VERSION ""

NS_ :

BS_:

BU_:

BO_ 2365524759 FF0B: 8 Vector__XXX
 SG_ LightCheckSwitch : 0|2@1+ (1,0) [0|3] "" Vector__XXX
 SG_ D1DemistSwitch : 4|2@1+ (1,0) [0|3] "" Vector__XXX
 SG_ SchoolFlashSwitch : 6|2@1+ (1,0) [0|3] "" Vector__XXX
 SG_ BellCancelSwitch : 8|2@1+ (1,0) [0|3] "" Vector__XXX
 SG_ MapLightSwitch : 10|2@1+ (1,0) [0|3] "" Vector__XXX
 SG_ CabLightSwitch : 2|2@1+ (1,0) [0|3] "" Vector__XXX
 SG_ D1Switch : 14|2@1+ (1,0) [0|3] "" Vector__XXX
 SG_ D2Switch : 12|2@1+ (1,0) [0|3] "" Vector__XXX
 SG_ Switch_2S_10 : 18|2@1+ (1,0) [0|3] "" Vector__XXX
 SG_ Switch_2S_11 : 20|2@1+ (1,0) [0|3] "" Vector__XXX
 SG_ Switch_2S_12 : 22|2@1+ (1,0) [0|3] "" Vector__XXX
 SG_ Switch_2S_13 : 24|2@1+ (1,0) [0|3] "" Vector__XXX
 SG_ Switch_2S_14 : 56|2@1+ (1,0) [0|3] "" Vector__XXX
 SG_ Switch_2S_15 : 48|2@1+ (1,0) [0|3] "" Vector__XXX
 SG_ Switch_2S_16 : 40|2@1+ (1,0) [0|3] "" Vector__XXX
 SG_ Switch_2S_17 : 32|2@1+ (1,0) [0|3] "" Vector__XXX
 SG_ ECASSwitch : 34|3@1+ (1,0) [0|7] "" Vector__XXX
 SG_ DemistFanSwitch : 37|3@1+ (1,0) [0|7] "" Vector__XXX
 SG_ DriverFanSwitch : 42|3@1+ (1,0) [0|7] "" Vector__XXX
 SG_ SaloonLightSwitch : 45|3@1+ (1,0) [0|7] "" Vector__XXX
 SG_ RTRH_Switch : 29|3@1+ (1,0) [0|7] "" Vector__XXX
 SG_ DemistTempSwitch : 26|3@1+ (1,0) [0|7] "" Vector__XXX
 SG_ Switch_3S_7 : 50|3@1+ (1,0) [0|7] "" Vector__XXX
 SG_ Switch_3S_8 : 53|3@1+ (1,0) [0|7] "" Vector__XXX
 SG_ Switch_3S_9 : 58|3@1+ (1,0) [0|7] "" Vector__XXX
 SG_ Switch_3S_10 : 61|3@1+ (1,0) [0|7] "" Vector__XXX
 SG_ Switch_2S_9 : 16|2@1+ (1,0) [0|3] "" Vector__XXX

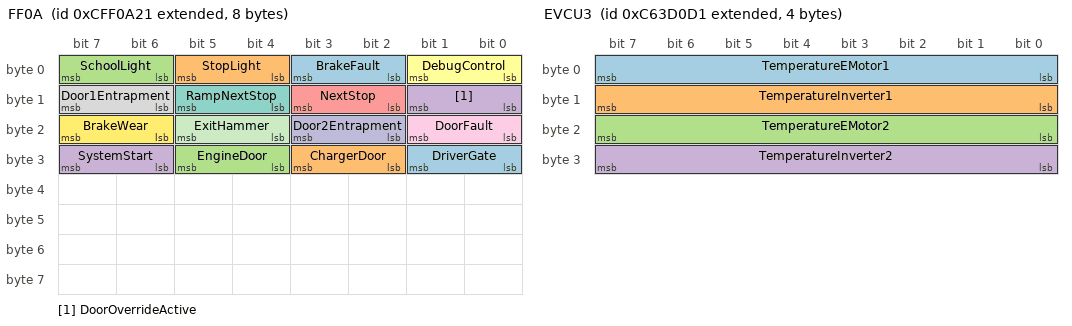
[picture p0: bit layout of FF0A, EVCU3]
BO_ 2365524513 FF0A: 8 Vector__XXX
 SG_ BrakeFault : 2|2@1+ (1,0) [0|3] "" Vector__XXX
 SG_ StopLight : 4|2@1+ (1,0) [0|3] "" Vector__XXX
 SG_ SchoolLight : 6|2@1+ (1,0) [0|3] "" Vector__XXX
 SG_ DoorOverrideActive : 8|2@1+ (1,0) [0|3] "" Vector__XXX
 SG_ NextStop : 10|2@1+ (1,0) [0|3] "" Vector__XXX
 SG_ DebugControl : 0|2@1+ (1,0) [0|3] "" Vector__XXX
 SG_ RampNextStop : 12|2@1+ (1,0) [0|3] "" Vector__XXX
 SG_ Door1Entrapment : 14|2@1+ (1,0) [0|3] "" Vector__XXX
 SG_ DoorFault : 16|2@1+ (1,0) [0|3] "" Vector__XXX
 SG_ Door2Entrapment : 18|2@1+ (1,0) [0|3] "" Vector__XXX
 SG_ ExitHammer : 20|2@1+ (1,0) [0|3] "" Vector__XXX
 SG_ BrakeWear : 22|2@1+ (1,0) [0|3] "" Vector__XXX
 SG_ DriverGate : 24|2@1+ (1,0) [0|3] "" Vector__XXX
 SG_ ChargerDoor : 26|2@1+ (1,0) [0|3] "" Vector__XXX
 SG_ EngineDoor : 28|2@1+ (1,0) [0|3] "" Vector__XXX
 SG_ SystemStart : 30|2@1+ (1,0) [0|3] "" Vector__XXX

BO_ 2355220689 EVCU1: 8 Vector__XXX
 SG_ ActualdirectionmodeAVESyst : 0|2@1+ (1,0) [0|2] "" Vector__XXX
 SG_ ActualDrivemode : 2|2@1+ (1,0) [0|3] "" Vector__XXX
 SG_ WheelSlippagedetection : 4|4@1+ (1,0) [0|3] "sts" Vector__XXX
 SG_ Averagemotorspeed : 8|16@1+ (1,0) [0|15000] "rpm" Vector__XXX
 SG_ ActualtorqueAVESystem : 24|12@1+ (1,0) [0|3200] "Nm" Vector__XXX
 SG_ AVESystemReady : 36|1@1+ (1,0) [0|1] "b" Vector__XXX
 SG_ AVESystemReducedOperational : 37|1@1+ (1,0) [0|1] "b" Vector__XXX
 SG_ ElectricalBrakeTorqueLow : 38|1@1+ (1,0) [0|1] "b" Vector__XXX
 SG_ CreeperStopping : 39|1@1+ (1,0) [0|1] "b" Vector__XXX
 SG_ CreeperNotAvailable : 40|1@1+ (1,0) [0|1] "b" Vector__XXX
 SG_ TUpAStopping : 41|1@1+ (1,0) [0|1] "b" Vector__XXX
 SG_ TUpANotAvailable : 42|1@1+ (1,0) [0|1] "b" Vector__XXX
 SG_ RecuperationHighStatus : 43|1@1+ (1,0) [0|1] "b" Vector__XXX
 SG_ Reserved4 : 44|1@1+ (1,0) [0|1] "b" Vector__XXX
 SG_ Reserved57 : 45|3@1+ (1,0) [0|1] "b" Vector__XXX
 SG_ EMotorOverspeed : 48|2@1+ (1,0) [0|3] "b" Vector__XXX
 SG_ EVECU1MSGCounter : 52|4@1+ (1,0) [0|15] "cnt" Vector__XXX
 SG_ EVEC1MSGCRC : 56|8@1+ (1,0) [0|255] "" Vector__XXX

BO_ 2355351761 EVCU3: 4 Vector__XXX
 SG_ TemperatureEMotor1 : 0|8@1+ (1,-40) [-40|213] "°C" Vector__XXX
 SG_ TemperatureInverter1 : 8|8@1+ (1,-40) [-40|213] "°C" Vector__XXX
 SG_ TemperatureEMotor2 : 16|8@1+ (1,-40) [-40|213] "°C" Vector__XXX
 SG_ TemperatureInverter2 : 24|8@1+ (1,-40) [-40|213] "°C" Vector__XXX

BO_ 2566759713 DC2: 8 Vector__XXX
 SG_ LockStatusOfDoor1 : 0|2@1+ (1,0) [0|3] "" Vector__XXX
 SG_ OpenStatusOfDoor1 : 2|2@1+ (1,0) [0|3] "" Vector__XXX
 SG_ EnableStatusOfDoor1 : 4|2@1+ (1,0) [0|3] "" Vector__XXX
 SG_ LockStatusOfDoor2 : 6|2@1+ (1,0) [0|3] "" Vector__XXX
 SG_ OpenStatusOfDoor2 : 8|2@1+ (1,0) [0|3] "" Vector__XXX
 SG_ EnableStatusOfDoor2 : 10|2@1+ (1,0) [0|3] "" Vector__XXX
 SG_ LockStatusOfDoor3 : 12|2@1+ (1,0) [0|3] "" Vector__XXX
 SG_ OpenStatusOfDoor3 : 14|2@1+ (1,0) [0|3] "" Vector__XXX
 SG_ EnableStatusOfDoor3 : 16|2@1+ (1,0) [0|3] "" Vector__XXX
 SG_ LockStatusOfDoor4 : 18|2@1+ (1,0) [0|3] "" Vector__XXX
 SG_ OpenStatusOfDoor4 : 20|2@1+ (1,0) [0|3] "" Vector__XXX
 SG_ EnableStatusOfDoor4 : 22|2@1+ (1,0) [0|3] "" Vector__XXX
 SG_ LockStatusOfDoor5 : 24|2@1+ (1,0) [0|3] "" Vector__XXX
 SG_ OpenStatusOfDoor5 : 26|2@1+ (1,0) [0|3] "" Vector__XXX
 SG_ EnableStatusOfDoor5 : 28|2@1+ (1,0) [0|3] "" Vector__XXX
 SG_ LockStatusOfDoor6 : 30|2@1+ (1,0) [0|3] "" Vector__XXX
 SG_ OpenStatusOfDoor6 : 32|2@1+ (1,0) [0|3] "" Vector__XXX
 SG_ EnableStatusOfDoor6 : 34|2@1+ (1,0) [0|3] "" Vector__XXX
 SG_ LockStatusOfDoor7 : 36|2@1+ (1,0) [0|3] "" Vector__XXX
 SG_ OpenStatusOfDoor7 : 38|2@1+ (1,0) [0|3] "" Vector__XXX
 SG_ EnableStatusOfDoor7 : 40|2@1+ (1,0) [0|3] "" Vector__XXX
 SG_ LockStatusOfDoor8 : 42|2@1+ (1,0) [0|3] "" Vector__XXX
 SG_ OpenStatusOfDoor8 : 44|2@1+ (1,0) [0|3] "" Vector__XXX
 SG_ EnableStatusOfDoor8 : 46|2@1+ (1,0) [0|3] "" Vector__XXX
 SG_ LockStatusOfDoor9 : 48|2@1+ (1,0) [0|3] "" Vector__XXX
 SG_ OpenStatusOfDoor9 : 50|2@1+ (1,0) [0|3] "" Vector__XXX
 SG_ EnableStatusOfDoor9 : 52|2@1+ (1,0) [0|3] "" Vector__XXX
 SG_ LockStatusOfDoor10 : 54|2@1+ (1,0) [0|3] "" Vector__XXX
 SG_ OpenStatusOfDoor10 : 56|2@1+ (1,0) [0|3] "" Vector__XXX
 SG_ EnableStatusOfDoor10 : 58|2@1+ (1,0) [0|3] "" Vector__XXX

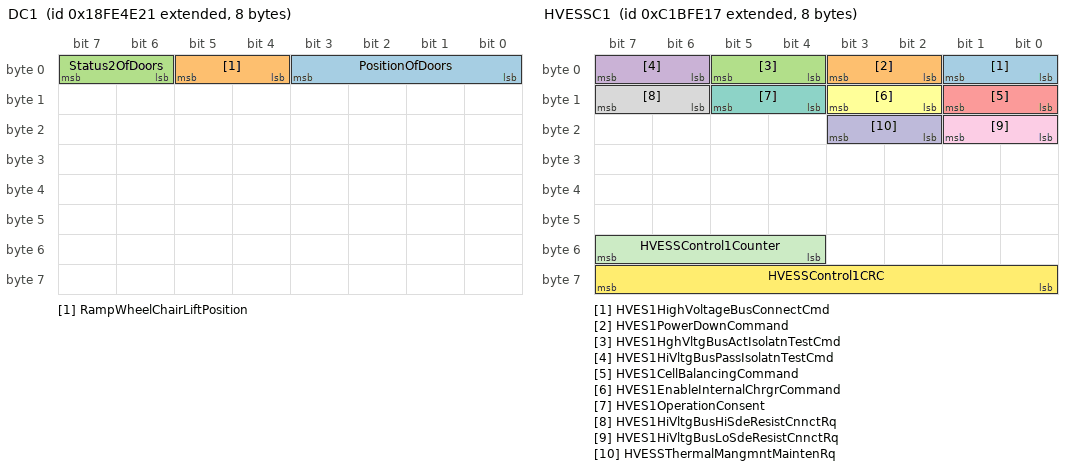
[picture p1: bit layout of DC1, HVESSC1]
BO_ 2566802977 DC1: 8 Vector__XXX
 SG_ PositionOfDoors : 0|4@1+ (1,0) [0|15] "" Vector__XXX
 SG_ RampWheelChairLiftPosition : 4|2@1+ (1,0) [0|3] "" Vector__XXX
 SG_ Status2OfDoors : 6|2@1+ (1,0) [0|3] "" Vector__XXX

BO_ 2350644759 HVESSC1: 8 Vector__XXX
 SG_ HVES1HighVoltageBusConnectCmd : 0|2@1+ (1,0) [0|3] "" Vector__XXX
 SG_ HVES1PowerDownCommand : 2|2@1+ (1,0) [0|3] "" Vector__XXX
 SG_ HVES1HghVltgBusActIsolatnTestCmd : 4|2@1+ (1,0) [0|3] "" Vector__XXX
 SG_ HVES1HiVltgBusPassIsolatnTestCmd : 6|2@1+ (1,0) [0|3] "" Vector__XXX
 SG_ HVES1CellBalancingCommand : 8|2@1+ (1,0) [0|3] "" Vector__XXX
 SG_ HVES1EnableInternalChrgrCommand : 10|2@1+ (1,0) [0|3] "" Vector__XXX
 SG_ HVES1OperationConsent : 12|2@1+ (1,0) [0|3] "" Vector__XXX
 SG_ HVES1HiVltgBusHiSdeResistCnnctRq : 14|2@1+ (1,0) [0|3] "" Vector__XXX
 SG_ HVES1HiVltgBusLoSdeResistCnnctRq : 16|2@1+ (1,0) [0|3] "" Vector__XXX
 SG_ HVESSThermalMangmntMaintenRq : 18|2@1+ (1,0) [0|3] "" Vector__XXX
 SG_ HVESSControl1Counter : 52|4@1+ (1,0) [0|15] "" Vector__XXX
 SG_ HVESSControl1CRC : 56|8@1+ (1,0) [0|255] "" Vector__XXX

BO_ 2565865739 EBC1: 8 Vector__XXX
 SG_ ASREngineControlActive : 0|2@1+ (1,0) [0|3] "" Vector__XXX
 SG_ ASRBrakeControlActive : 2|2@1+ (1,0) [0|3] "" Vector__XXX
 SG_ AntiLockBrakingActive : 4|2@1+ (1,0) [0|3] "" Vector__XXX
 SG_ EBSBrakeSwitch : 6|2@1+ (1,0) [0|3] "" Vector__XXX
 SG_ BrakePedalPosition : 8|8@1+ (0.4,0) [0|100] "%" Vector__XXX
 SG_ ABSOffRoadSwitch : 16|2@1+ (1,0) [0|3] "" Vector__XXX
 SG_ ASROffRoadSwitch : 18|2@1+ (1,0) [0|3] "" Vector__XXX
 SG_ ASRHillHolderSwitch : 20|2@1+ (1,0) [0|3] "" Vector__XXX
 SG_ TractionControlOverrideSwitch : 22|2@1+ (1,0) [0|3] "" Vector__XXX
 SG_ AcceleratorInterlockSwitch : 24|2@1+ (1,0) [0|3] "" Vector__XXX
 SG_ EngineDerateSwitch : 26|2@1+ (1,0) [0|3] "" Vector__XXX
 SG_ EngineAuxiliaryShutdownSwitch : 28|2@1+ (1,0) [0|3] "" Vector__XXX
 SG_ RemoteAcceleratorEnableSwitch : 30|2@1+ (1,0) [0|3] "" Vector__XXX
 SG_ EngineRetarderSelection : 32|8@1+ (0.4,0) [0|100] "%" Vector__XXX
 SG_ ABSFullyOperational : 40|2@1+ (1,0) [0|3] "" Vector__XXX
 SG_ EBSRedWarningSignal : 42|2@1+ (1,0) [0|3] "" Vector__XXX
 SG_ ABSEBSAmberWarningSignal : 44|2@1+ (1,0) [0|3] "" Vector__XXX
 SG_ ATCASRInformationSignal : 46|2@1+ (1,0) [0|3] "" Vector__XXX
 SG_ SrcAddrOfCtrllingDevForBrkCtrl : 48|8@1+ (1,0) [0|255] "" Vector__XXX
 SG_ RailroadModeSwitch : 56|2@1+ (1,0) [0|3] "" Vector__XXX
 SG_ HaltBrakeSwitch : 58|2@1+ (1,0) [0|3] "" Vector__XXX
 SG_ TrailerABSStatus : 60|2@1+ (1,0) [0|3] "" Vector__XXX
 SG_ TractorMntdTrailerABSWarningSig : 62|2@1+ (1,0) [0|3] "" Vector__XXX

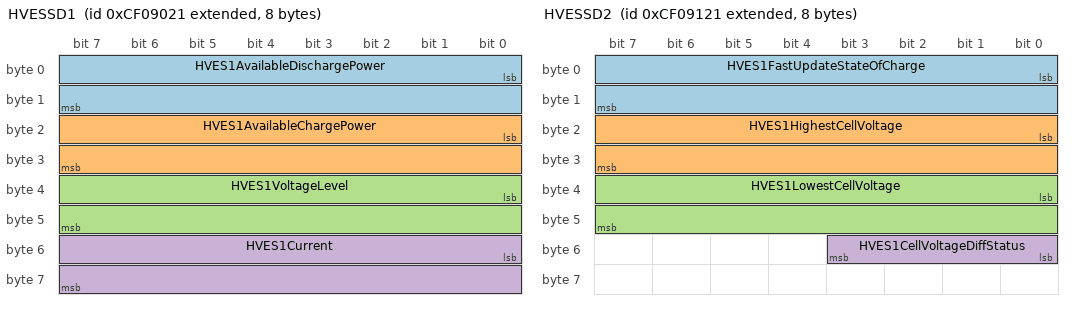
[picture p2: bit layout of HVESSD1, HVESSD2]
BO_ 2364575777 HVESSD1: 8 Vector__XXX
 SG_ HVES1AvailableDischargePower : 0|16@1+ (0.05,0) [0|3212.75] "kW" Vector__XXX
 SG_ HVES1AvailableChargePower : 16|16@1+ (0.05,0) [0|3212.75] "kW" Vector__XXX
 SG_ HVES1VoltageLevel : 32|16@1+ (0.05,0) [0|3212.75] "V" Vector__XXX
 SG_ HVES1Current : 48|16@1+ (0.05,-1600) [-1600|1612.75] "A" Vector__XXX

BO_ 2364576033 HVESSD2: 8 Vector__XXX
 SG_ HVES1FastUpdateStateOfCharge : 0|16@1+ (0.0015625,0) [0|100.3984375] "%" Vector__XXX
 SG_ HVES1HighestCellVoltage : 16|16@1+ (0.001,0) [0|64.255] "V" Vector__XXX
 SG_ HVES1LowestCellVoltage : 32|16@1+ (0.001,0) [0|64.255] "V" Vector__XXX
 SG_ HVES1CellVoltageDiffStatus : 48|4@1+ (1,0) [0|15] "" Vector__XXX

BO_ 2566545953 LD2: 8 Vector__XXX
 SG_ TractorHazardLights : 0|2@1+ (1,0) [0|3] "" Vector__XXX

BO_ 2365219607 LCMD2: 8 Vector__XXX
 SG_ LightingData2RequestCommand : 0|2@1+ (1,0) [0|3] "" Vector__XXX
 SG_ TractorHazardLightsCommand : 2|2@1+ (1,0) [0|3] "" Vector__XXX

BO_ 2499547671 CDC1: 8 Vector__XXX
 SG_ CabDoorsLockActuationCommand : 0|3@1+ (1,0) [0|7] "" Vector__XXX
 SG_ RemoteCabDoorLockRequest : 8|3@1+ (1,0) [0|7] "" Vector__XXX
 SG_ LeftFrontWindowPositionCommand : 16|3@1+ (1,0) [0|7] "" Vector__XXX
 SG_ RightFrontWindowPositionCommand : 19|3@1+ (1,0) [0|7] "" Vector__XXX
 SG_ MirrorFoldingSwitch : 22|2@1+ (1,0) [0|3] "" Vector__XXX
 SG_ LeftRearWindowPositionCommand : 24|3@1+ (1,0) [0|7] "" Vector__XXX
 SG_ RightRearWindowPositionCommand : 27|3@1+ (1,0) [0|7] "" Vector__XXX
 SG_ MirrorAutoPanningEnable : 30|2@1+ (1,0) [0|3] "" Vector__XXX
 SG_ MirrorLeft1HorizontalCommand : 32|2@1+ (1,0) [0|3] "" Vector__XXX
 SG_ MirrorLeft1VerticalCommand : 34|2@1+ (1,0) [0|3] "" Vector__XXX
 SG_ MirrorRight1HorizontalCommand : 36|2@1+ (1,0) [0|3] "" Vector__XXX
 SG_ MirrorRight1VerticalCommand : 38|2@1+ (1,0) [0|3] "" Vector__XXX
 SG_ MirrorLeft2HorizontalCommand : 40|2@1+ (1,0) [0|3] "" Vector__XXX
 SG_ MirrorLeft2VerticalCommand : 42|2@1+ (1,0) [0|3] "" Vector__XXX
 SG_ MirrorRight2HorizontalCommand : 44|2@1+ (1,0) [0|3] "" Vector__XXX
 SG_ MirrorRight2VerticalCommand : 46|2@1+ (1,0) [0|3] "" Vector__XXX
 SG_ MirrorLeft1HeatCommand : 48|2@1+ (1,0) [0|3] "" Vector__XXX
 SG_ MirrorRight1HeatCommand : 50|2@1+ (1,0) [0|3] "" Vector__XXX
 SG_ MirrorLeft2HeatCommand : 52|2@1+ (1,0) [0|3] "" Vector__XXX
 SG_ MirrorRight2HeatCommand : 54|2@1+ (1,0) [0|3] "" Vector__XXX

BO_ 2566771745 CM3: 8 Vector__XXX
 SG_ TransferCaseSelectorSwitch : 0|3@1+ (1,0) [0|7] "" Vector__XXX
 SG_ AfttreatmentSCRDosingModeCommand : 3|3@1+ (1,0) [0|7] "" Vector__XXX
 SG_ MomentaryOperatorKeySwitch : 6|2@1+ (1,0) [0|3] "" Vector__XXX
 SG_ FifthWheelReleaseControl : 8|2@1+ (1,0) [0|3] "" Vector__XXX
 SG_ FifthWhlReleaseCtrlSecurityLckt : 10|2@1+ (1,0) [0|3] "" Vector__XXX
 SG_ VehicleTrailerStatus : 12|2@1+ (1,0) [0|3] "" Vector__XXX
 SG_ OperatorKeyDetected : 14|2@1+ (1,0) [0|3] "" Vector__XXX
 SG_ TransmissionOilLevelRequest : 16|2@1+ (1,0) [0|3] "" Vector__XXX
 SG_ OperatorKeySwitchAccessoryPower : 18|2@1+ (1,0) [0|3] "" Vector__XXX
 SG_ OperatorKeySwitchIgnitionPower : 20|2@1+ (1,0) [0|3] "" Vector__XXX
 SG_ OperatorKeySwitchStart : 22|2@1+ (1,0) [0|3] "" Vector__XXX
 SG_ OprtrKeySwitchDelayedBattryOff : 24|2@1+ (1,0) [0|3] "" Vector__XXX
 SG_ HornSwitch : 26|2@1+ (1,0) [0|3] "" Vector__XXX
 SG_ EngineAirShutoffTestSwitch : 28|2@1+ (1,0) [0|3] "" Vector__XXX
 SG_ EngineAirShutoffManualSwitch : 30|2@1+ (1,0) [0|3] "" Vector__XXX
 SG_ OperatorKeySwitchService : 32|2@1+ (1,0) [0|3] "" Vector__XXX
 SG_ OperatorKeySwitchOff : 34|2@1+ (1,0) [0|3] "" Vector__XXX
 SG_ RemoteKeyFobFunctionRequested : 40|5@1+ (1,0) [0|31] "" Vector__XXX

BO_ 2566799393 LD: 8 Vector__XXX
 SG_ RunningLight : 0|2@1+ (1,0) [0|3] "" Vector__XXX
 SG_ AlternateBeamHeadLightData : 2|2@1+ (1,0) [0|3] "" Vector__XXX
 SG_ LowBeamHeadLightData : 4|2@1+ (1,0) [0|3] "" Vector__XXX
 SG_ HighBeamHeadLightData : 6|2@1+ (1,0) [0|3] "" Vector__XXX
 SG_ TractorFrontFogLights : 8|2@1+ (1,0) [0|3] "" Vector__XXX
 SG_ RotatingBeaconLight : 10|2@1+ (1,0) [0|3] "" Vector__XXX
 SG_ RightTurnSignalLights : 12|2@1+ (1,0) [0|3] "" Vector__XXX
 SG_ LeftTurnSignalLights : 14|2@1+ (1,0) [0|3] "" Vector__XXX
 SG_ BackUpLightAndAlarmHorn : 16|2@1+ (1,0) [0|3] "" Vector__XXX
 SG_ CenterStopLight : 18|2@1+ (1,0) [0|3] "" Vector__XXX
 SG_ RightStopLight : 20|2@1+ (1,0) [0|3] "" Vector__XXX
 SG_ LeftStopLight : 22|2@1+ (1,0) [0|3] "" Vector__XXX
 SG_ ImplementClearanceLight : 24|2@1+ (1,0) [0|3] "" Vector__XXX
 SG_ TractorClearanceLight : 26|2@1+ (1,0) [0|3] "" Vector__XXX
 SG_ ImplementMarkerLight : 28|2@1+ (1,0) [0|3] "" Vector__XXX
 SG_ TractorMarkerLight : 30|2@1+ (1,0) [0|3] "" Vector__XXX
 SG_ RearFogLights : 32|2@1+ (1,0) [0|3] "" Vector__XXX
 SG_ TractorUndersideMntdWorkLights : 34|2@1+ (1,0) [0|3] "" Vector__XXX
 SG_ TractorRearLowMountedWorkLights : 36|2@1+ (1,0) [0|3] "" Vector__XXX
 SG_ TractorRearHighMountedWorkLights : 38|2@1+ (1,0) [0|3] "" Vector__XXX
 SG_ TractorSideLowMountedWorkLights : 40|2@1+ (1,0) [0|3] "" Vector__XXX
 SG_ TractorSideHighMountedWorkLights : 42|2@1+ (1,0) [0|3] "" Vector__XXX
 SG_ TractorFrontLowMountedWorkLights : 44|2@1+ (1,0) [0|3] "" Vector__XXX
 SG_ TractorFrntHighMountedWorkLights : 46|2@1+ (1,0) [0|3] "" Vector__XXX
 SG_ ImplementOEMOption2Light : 48|2@1+ (1,0) [0|3] "" Vector__XXX
 SG_ ImplementOEMOption1Light : 50|2@1+ (1,0) [0|3] "" Vector__XXX
 SG_ ImplementRightFacingWorkLight : 52|2@1+ (1,0) [0|3] "" Vector__XXX
 SG_ ImplementLeftForwardWorkLight : 54|2@1+ (1,0) [0|3] "" Vector__XXX
 SG_ ImplementRightForwardWorkLight : 58|2@1+ (1,0) [0|3] "" Vector__XXX
 SG_ ImplementLeftFacingWorkLight : 60|2@1+ (1,0) [0|3] "" Vector__XXX
 SG_ ImplementRearWorkLight : 62|2@1+ (1,0) [0|3] "" Vector__XXX

BO_ 2365473047 LCMD: 8 Vector__XXX
 SG_ RunningLightCommand : 0|2@1+ (1,0) [0|3] "" Vector__XXX
 SG_ AlternateBeamHeadLightCommand : 2|2@1+ (1,0) [0|3] "" Vector__XXX
 SG_ LowBeamHeadLightCommand : 4|2@1+ (1,0) [0|3] "" Vector__XXX
 SG_ HighBeamHeadLightCommand : 6|2@1+ (1,0) [0|3] "" Vector__XXX
 SG_ TractorFrontFogLightsCommand : 8|2@1+ (1,0) [0|3] "" Vector__XXX
 SG_ RotatingBeaconLightCommand : 10|2@1+ (1,0) [0|3] "" Vector__XXX
 SG_ RightTurnSignalLightsCommand : 12|2@1+ (1,0) [0|3] "" Vector__XXX
 SG_ LeftTurnSignalLightsCommand : 14|2@1+ (1,0) [0|3] "" Vector__XXX
 SG_ BackUpLightAndAlarmHornCommand : 16|2@1+ (1,0) [0|3] "" Vector__XXX
 SG_ CenterStopLightCommand : 18|2@1+ (1,0) [0|3] "" Vector__XXX
 SG_ RightStopLightCommand : 20|2@1+ (1,0) [0|3] "" Vector__XXX
 SG_ LeftStopLightCommand : 22|2@1+ (1,0) [0|3] "" Vector__XXX
 SG_ ImplementClearanceLightCommand : 24|2@1+ (1,0) [0|3] "" Vector__XXX
 SG_ TractorClearanceLightCommand : 26|2@1+ (1,0) [0|3] "" Vector__XXX
 SG_ ImplementMarkerLightCommand : 28|2@1+ (1,0) [0|3] "" Vector__XXX
 SG_ TractorMarkerLightCommand : 30|2@1+ (1,0) [0|3] "" Vector__XXX
 SG_ RearFogLightCommand : 32|2@1+ (1,0) [0|3] "" Vector__XXX
 SG_ TractorUnderSdeMntdWorkLightsCmd : 34|2@1+ (1,0) [0|3] "" Vector__XXX
 SG_ TractorRearLowMntdWorkLightsCmd : 36|2@1+ (1,0) [0|3] "" Vector__XXX
 SG_ TractorRearHghMntdWorkLightsCmd : 38|2@1+ (1,0) [0|3] "" Vector__XXX
 SG_ TractorSideLowMntdWorkLightsCmd : 40|2@1+ (1,0) [0|3] "" Vector__XXX
 SG_ TractorSideHghMntdWorkLightsCmd : 42|2@1+ (1,0) [0|3] "" Vector__XXX
 SG_ TractorFrntLowMntdWorkLightsCmd : 44|2@1+ (1,0) [0|3] "" Vector__XXX
 SG_ TractorFrntHghMntdWorkLightsCmd : 46|2@1+ (1,0) [0|3] "" Vector__XXX
 SG_ ImplementOEMOption2LightCommand : 48|2@1+ (1,0) [0|3] "" Vector__XXX
 SG_ ImplementOEMOption1LightCommand : 50|2@1+ (1,0) [0|3] "" Vector__XXX
 SG_ ImplementRightFacingWorkLightCmd : 52|2@1+ (1,0) [0|3] "" Vector__XXX
 SG_ ImplementLeftForwardWorkLightCmd : 54|2@1+ (1,0) [0|3] "" Vector__XXX
 SG_ LightingDataRequestCommand : 56|2@1+ (1,0) [0|3] "" Vector__XXX
 SG_ ImplementRightFrwdWorkLightCmd : 58|2@1+ (1,0) [0|3] "" Vector__XXX
 SG_ ImplementLeftFacingWorkLightCmd : 60|2@1+ (1,0) [0|3] "" Vector__XXX
 SG_ ImplementRearWorkLightCommand : 62|2@1+ (1,0) [0|3] "" Vector__XXX

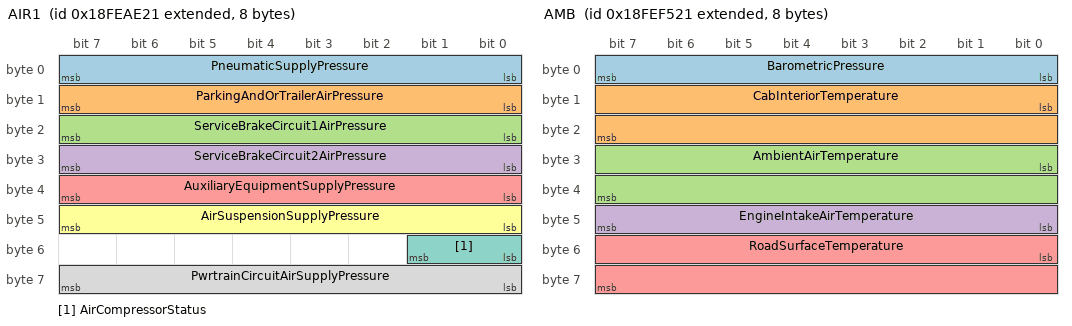
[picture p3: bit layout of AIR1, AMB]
BO_ 2566827553 AIR1: 8 Vector__XXX
 SG_ PneumaticSupplyPressure : 0|8@1+ (8,0) [0|2000] "kPa" Vector__XXX
 SG_ ParkingAndOrTrailerAirPressure : 8|8@1+ (8,0) [0|2000] "kPa" Vector__XXX
 SG_ ServiceBrakeCircuit1AirPressure : 16|8@1+ (8,0) [0|2000] "kPa" Vector__XXX
 SG_ ServiceBrakeCircuit2AirPressure : 24|8@1+ (8,0) [0|2000] "kPa" Vector__XXX
 SG_ AuxiliaryEquipmentSupplyPressure : 32|8@1+ (8,0) [0|2000] "kPa" Vector__XXX
 SG_ AirSuspensionSupplyPressure : 40|8@1+ (8,0) [0|2000] "kPa" Vector__XXX
 SG_ AirCompressorStatus : 48|2@1+ (1,0) [0|3] "" Vector__XXX
 SG_ PwrtrainCircuitAirSupplyPressure : 56|8@1+ (8,0) [0|2000] "kPa" Vector__XXX

BO_ 2566844705 CCVS1: 8 Vector__XXX
 SG_ TwoSpeedAxleSwitch : 0|2@1+ (1,0) [0|3] "" Vector__XXX
 SG_ ParkingBrakeSwitch : 2|2@1+ (1,0) [0|3] "" Vector__XXX
 SG_ CruiseControlPauseSwitch : 4|2@1+ (1,0) [0|3] "" Vector__XXX
 SG_ ParkBrakeReleaseInhibitRequest : 6|2@1+ (1,0) [0|3] "" Vector__XXX
 SG_ WheelBasedVehicleSpeed : 8|16@1+ (0.00390625,0) [0|250.99609375] "km/h" Vector__XXX
 SG_ CruiseControlActive : 24|2@1+ (1,0) [0|3] "" Vector__XXX
 SG_ CruiseControlEnableSwitch : 26|2@1+ (1,0) [0|3] "" Vector__XXX
 SG_ BrakeSwitch : 28|2@1+ (1,0) [0|3] "" Vector__XXX
 SG_ ClutchSwitch : 30|2@1+ (1,0) [0|3] "" Vector__XXX
 SG_ CruiseControlSetSwitch : 32|2@1+ (1,0) [0|3] "" Vector__XXX
 SG_ CruiseControlCoastSwitch : 34|2@1+ (1,0) [0|3] "" Vector__XXX
 SG_ CruiseControlResumeSwitch : 36|2@1+ (1,0) [0|3] "" Vector__XXX
 SG_ CruiseControlAccelerateSwitch : 38|2@1+ (1,0) [0|3] "" Vector__XXX
 SG_ CruiseControlSetSpeed : 40|8@1+ (1,0) [0|250] "km/h" Vector__XXX
 SG_ PTOGovernorState : 48|5@1+ (1,0) [0|31] "" Vector__XXX
 SG_ CruiseControlStates : 53|3@1+ (1,0) [0|7] "" Vector__XXX
 SG_ EngineIdleIncrementSwitch : 56|2@1+ (1,0) [0|3] "" Vector__XXX
 SG_ EngineIdleDecrementSwitch : 58|2@1+ (1,0) [0|3] "" Vector__XXX
 SG_ EngineDiagnosticTestModeSwitch : 60|2@1+ (1,0) [0|3] "" Vector__XXX
 SG_ EngineShutdownOverrideSwitch : 62|2@1+ (1,0) [0|3] "" Vector__XXX

BO_ 2566845729 AMB: 8 Vector__XXX
 SG_ BarometricPressure : 0|8@1+ (0.5,0) [0|125] "kPa" Vector__XXX
 SG_ CabInteriorTemperature : 8|16@1+ (0.03125,-273) [-273|1734.96875] "deg C" Vector__XXX
 SG_ AmbientAirTemperature : 24|16@1+ (0.03125,-273) [-273|1734.96875] "deg C" Vector__XXX
 SG_ EngineIntakeAirTemperature : 40|8@1+ (1,-40) [-40|210] "deg C" Vector__XXX
 SG_ RoadSurfaceTemperature : 48|16@1+ (0.03125,-273) [-273|1734.96875] "deg C" Vector__XXX

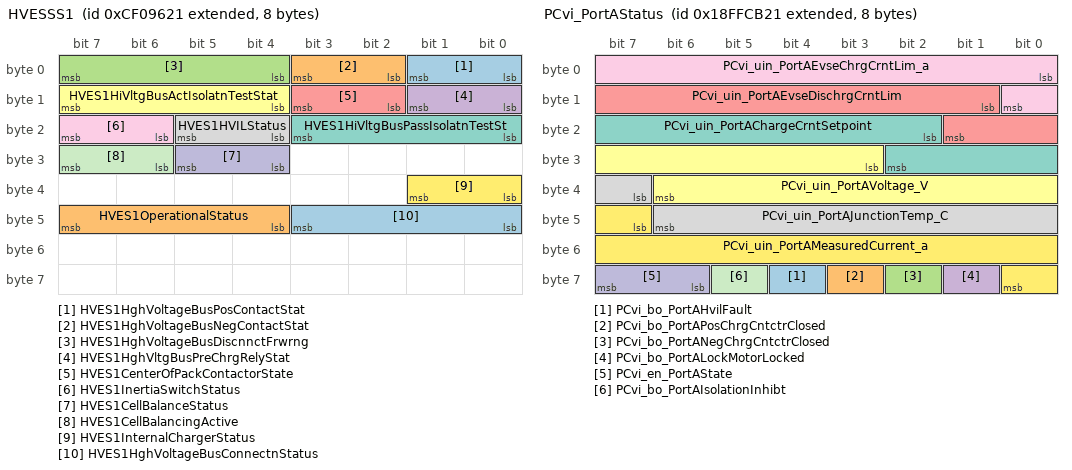
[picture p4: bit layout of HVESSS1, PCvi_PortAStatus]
BO_ 2364577313 HVESSS1: 8 Vector__XXX
 SG_ HVES1HghVoltageBusPosContactStat : 0|2@1+ (1,0) [0|3] "" Vector__XXX
 SG_ HVES1HghVoltageBusNegContactStat : 2|2@1+ (1,0) [0|3] "" Vector__XXX
 SG_ HVES1HghVoltageBusDiscnnctFrwrng : 4|4@1+ (1,0) [0|15] "" Vector__XXX
 SG_ HVES1HghVltgBusPreChrgRelyStat : 8|2@1+ (1,0) [0|3] "" Vector__XXX
 SG_ HVES1CenterOfPackContactorState : 10|2@1+ (1,0) [0|3] "" Vector__XXX
 SG_ HVES1HiVltgBusActIsolatnTestStat : 12|4@1+ (1,0) [0|15] "" Vector__XXX
 SG_ HVES1HiVltgBusPassIsolatnTestSt : 16|4@1+ (1,0) [0|15] "" Vector__XXX
 SG_ HVES1HVILStatus : 20|2@1+ (1,0) [0|3] "" Vector__XXX
 SG_ HVES1InertiaSwitchStatus : 22|2@1+ (1,0) [0|3] "" Vector__XXX
 SG_ HVES1CellBalanceStatus : 28|2@1+ (1,0) [0|3] "" Vector__XXX
 SG_ HVES1CellBalancingActive : 30|2@1+ (1,0) [0|3] "" Vector__XXX
 SG_ HVES1InternalChargerStatus : 32|2@1+ (1,0) [0|3] "" Vector__XXX
 SG_ HVES1HghVoltageBusConnectnStatus : 40|4@1+ (1,0) [0|15] "" Vector__XXX
 SG_ HVES1OperationalStatus : 44|4@1+ (1,0) [0|15] "" Vector__XXX

BO_ 2566900513 PCvi_PortAStatus: 8 Vector__XXX
 SG_ PCvi_bo_PortAHvilFault : 60|1@1+ (1,0) [0|1] "" Vector__XXX
 SG_ PCvi_bo_PortAPosChrgCntctrClosed : 59|1@1+ (1,0) [0|1] "" Vector__XXX
 SG_ PCvi_bo_PortANegChrgCntctrClosed : 58|1@1+ (1,0) [0|1] "" Vector__XXX
 SG_ PCvi_bo_PortALockMotorLocked : 57|1@1+ (1,0) [0|1] "" Vector__XXX
 SG_ PCvi_uin_PortAEvseDischrgCrntLim : 9|9@1+ (1,0) [0|511] "A" Vector__XXX
 SG_ PCvi_uin_PortAVoltage_V : 27|12@1+ (0.5,-1024) [-1024|1023.5] "V" Vector__XXX
 SG_ PCvi_uin_PortAChargeCrntSetpoint : 18|9@1+ (1,0) [0|511] "A" Vector__XXX
 SG_ PCvi_uin_PortAJunctionTemp_C : 39|8@1+ (1,-50) [-50|205] "C" Vector__XXX
 SG_ PCvi_uin_PortAEvseChrgCrntLim_a : 0|9@1+ (1,0) [0|511] "A" Vector__XXX
 SG_ PCvi_en_PortAState : 62|2@1+ (1,0) [0|3] "" Vector__XXX
 SG_ PCvi_bo_PortAIsolationInhibt : 61|1@1+ (1,0) [0|1] "" Vector__XXX
 SG_ PCvi_uin_PortAMeasuredCurrent_a : 47|10@1+ (1,-512) [-512|511] "A" Vector__XXX

BO_ 2365479471 ASC1_A: 8 Vector__XXX
 SG_ NominalLevelFrontAxle : 0|4@1+ (1,0) [0|15] "" Vector__XXX
 SG_ NominalLevelRearAxle : 4|4@1+ (1,0) [0|15] "" Vector__XXX
 SG_ BelowNominalLevelFrontAxle : 8|2@1+ (1,0) [0|3] "" Vector__XXX
 SG_ BelowNominalLevelRearAxle : 10|2@1+ (1,0) [0|3] "" Vector__XXX
 SG_ AboveNominalLevelFrontAxle : 12|2@1+ (1,0) [0|3] "" Vector__XXX
 SG_ AboveNominalLevelRearAxle : 14|2@1+ (1,0) [0|3] "" Vector__XXX
 SG_ LoweringControlModeFrontAxle : 16|2@1+ (1,0) [0|3] "" Vector__XXX
 SG_ LoweringControlModeRearAxle : 18|2@1+ (1,0) [0|3] "" Vector__XXX
 SG_ LiftingControlModeFrontAxle : 20|2@1+ (1,0) [0|3] "" Vector__XXX
 SG_ LiftingControlModeRearAxle : 22|2@1+ (1,0) [0|3] "" Vector__XXX
 SG_ KneelingInformation : 24|4@1+ (1,0) [0|15] "" Vector__XXX
 SG_ LevelControlMode : 28|4@1+ (1,0) [0|15] "" Vector__XXX
 SG_ SecurityDevice : 32|2@1+ (1,0) [0|3] "" Vector__XXX
 SG_ VehicleMotionInhibit : 34|2@1+ (1,0) [0|3] "" Vector__XXX
 SG_ DoorRelease : 36|2@1+ (1,0) [0|3] "" Vector__XXX
 SG_ LiftAxle1Position : 38|2@1+ (1,0) [0|3] "" Vector__XXX
 SG_ FrontAxleInBumperRange : 40|2@1+ (1,0) [0|3] "" Vector__XXX
 SG_ RearAxleInBumperRange : 42|2@1+ (1,0) [0|3] "" Vector__XXX
 SG_ LiftAxle2Position : 46|2@1+ (1,0) [0|3] "" Vector__XXX
 SG_ SuspensionRemoteControl1 : 48|2@1+ (1,0) [0|3] "" Vector__XXX
 SG_ SuspensionRemoteControl2 : 50|2@1+ (1,0) [0|3] "" Vector__XXX
 SG_ AllowLevelCtrlDuringBrkngStatus : 52|2@1+ (1,0) [0|3] "" Vector__XXX
 SG_ SpeedDependantLevelControlStatus : 54|2@1+ (1,0) [0|3] "" Vector__XXX
 SG_ SuspensionCtrlRefusalInformation : 56|4@1+ (1,0) [0|15] "" Vector__XXX
 SG_ MemoryLevel : 60|4@1+ (1,0) [0|15] "" Vector__XXX

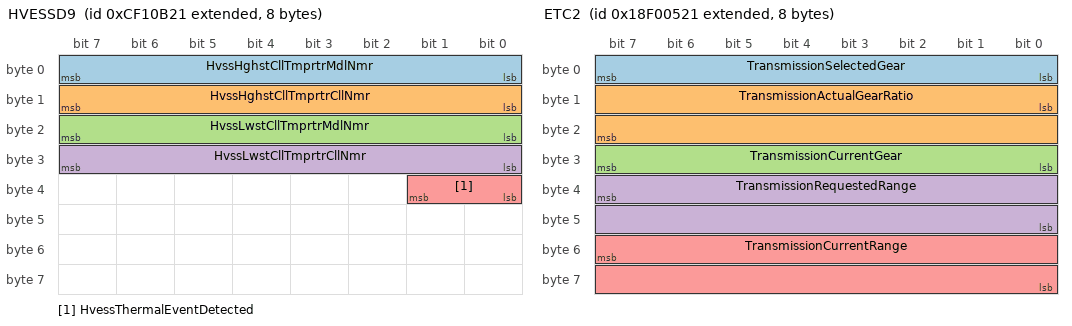
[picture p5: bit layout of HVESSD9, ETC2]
BO_ 2364607265 HVESSD9: 8 Vector__XXX
 SG_ HvssHghstCllTmprtrMdlNmr : 0|8@1+ (1,0) [0|250] "count" Vector__XXX
 SG_ HvssHghstCllTmprtrCllNmr : 8|8@1+ (1,0) [0|250] "count" Vector__XXX
 SG_ HvssLwstCllTmprtrMdlNmr : 16|8@1+ (1,0) [0|250] "count" Vector__XXX
 SG_ HvssLwstCllTmprtrCllNmr : 24|8@1+ (1,0) [0|250] "count" Vector__XXX
 SG_ HvessThermalEventDetected : 32|2@1+ (1,0) [0|3] "" Vector__XXX

BO_ 2565866785 ETC2: 8 Vector__XXX
 SG_ TransmissionSelectedGear : 0|8@1+ (1,-125) [-125|125] "" Vector__XXX
 SG_ TransmissionActualGearRatio : 8|16@1+ (0.001,0) [0|64.255] "" Vector__XXX
 SG_ TransmissionCurrentGear : 24|8@1+ (1,-125) [-125|125] "" Vector__XXX
 SG_ TransmissionRequestedRange : 39|16@0+ (1,0) [0|65535] "ASCII" Vector__XXX
 SG_ TransmissionCurrentRange : 55|16@0+ (1,0) [0|65535] "ASCII" Vector__XXX

BO_ 2566719265 DLCC1: 8 Vector__XXX
 SG_ EngineProtectLampCommand : 0|2@1+ (1,0) [0|3] "" Vector__XXX
 SG_ EngineAmberWarningLampCommand : 2|2@1+ (1,0) [0|3] "" Vector__XXX
 SG_ EngineRedStopLampCommand : 4|2@1+ (1,0) [0|3] "" Vector__XXX
 SG_ OBDMalfunctionIndicatorLampCmd : 6|2@1+ (1,0) [0|3] "" Vector__XXX
 SG_ EngineBrakeActiveLampCommand : 8|2@1+ (1,0) [0|3] "" Vector__XXX
 SG_ ComPrsionBrkEnblSwIndictrLampCmd : 10|2@1+ (1,0) [0|3] "" Vector__XXX
 SG_ EngineOilPressureLowLampCommand : 12|2@1+ (1,0) [0|3] "" Vector__XXX
 SG_ EngCoolntTemperatureHighLampCmd : 14|2@1+ (1,0) [0|3] "" Vector__XXX
 SG_ EngineCoolantLevelLowLampCommand : 16|2@1+ (1,0) [0|3] "" Vector__XXX
 SG_ EngineIdleManagementActvLampCmd : 18|2@1+ (1,0) [0|3] "" Vector__XXX
 SG_ EngAirFilterRestrictionLampCmd : 20|2@1+ (1,0) [0|3] "" Vector__XXX
 SG_ EngFuelFilterRestrictedLampCmd : 22|2@1+ (1,0) [0|3] "" Vector__XXX
 SG_ EngCtrlModule1ReadyForUseLampCmd : 24|2@1+ (1,0) [0|3] "" Vector__XXX
 SG_ EngCtrlModule2ReadyForUseLampCmd : 26|2@1+ (1,0) [0|3] "" Vector__XXX
 SG_ EngCtrlModule3ReadyForUseLampCmd : 28|2@1+ (1,0) [0|3] "" Vector__XXX
 SG_ EngineSpeedHighLampCommand : 30|2@1+ (1,0) [0|3] "" Vector__XXX
 SG_ EngineSpeedVeryHighLampCommand : 32|2@1+ (1,0) [0|3] "" Vector__XXX
 SG_ VehicleAccltnRateLimitLampCmd : 34|2@1+ (1,0) [0|3] "" Vector__XXX
 SG_ EngIdlMangmntPendingEvntLampCmd : 36|2@1+ (1,0) [0|3] "" Vector__XXX
 SG_ EngStopStartAutoStopActvLampCmd : 38|2@1+ (1,0) [0|3] "" Vector__XXX
 SG_ EngStopStrtAutoStrtFailedLampCmd : 40|2@1+ (1,0) [0|3] "" Vector__XXX
 SG_ EngineStopStartEnabledLampCmd : 42|2@1+ (1,0) [0|3] "" Vector__XXX
 SG_ EngineOilTemperatureHighLampCmd : 44|2@1+ (1,0) [0|3] "" Vector__XXX
 SG_ EngineFuelTemperatureHighLampCmd : 46|2@1+ (1,0) [0|3] "" Vector__XXX
 SG_ EngIntercoolerTempHghLampCmd : 48|2@1+ (1,0) [0|3] "" Vector__XXX
 SG_ EngineAirShutoffLampCommand : 50|2@1+ (1,0) [0|3] "" Vector__XXX

BO_ 2566749463 FMS1: 8 Vector__XXX
 SG_ FMS1_Mux M : 0|4@1+ (1,0) [0|0] "" Vector__XXX
 SG_ Coolingairconditioning m0 : 4|3@1+ (1,0) [0|7] "" Vector__XXX
 SG_ Highbeammainbeam m0 : 8|3@1+ (1,0) [0|7] "" Vector__XXX
 SG_ Lowbeamdippedbeam m0 : 12|3@1+ (1,0) [0|7] "" Vector__XXX
 SG_ Turnsignals m0 : 16|3@1+ (1,0) [0|7] "" Vector__XXX
 SG_ Hazardwarning m0 : 20|3@1+ (1,0) [0|7] "" Vector__XXX
 SG_ Provisionforthehandicapped m0 : 24|3@1+ (1,0) [0|7] "" Vector__XXX
 SG_ ParkingBrake m0 : 28|3@1+ (1,0) [0|7] "" Vector__XXX
 SG_ Brakefailure m0 : 32|3@1+ (1,0) [0|7] "" Vector__XXX
 SG_ Hatchopen m0 : 36|3@1+ (1,0) [0|7] "" Vector__XXX
 SG_ Fuellevel m0 : 40|3@1+ (1,0) [0|7] "" Vector__XXX
 SG_ Enginecoolanttemperature m0 : 44|3@1+ (1,0) [0|7] "" Vector__XXX
 SG_ Batterychargingcondition m0 : 48|3@1+ (1,0) [0|7] "" Vector__XXX
 SG_ Engineoil m0 : 52|3@1+ (1,0) [0|7] "" Vector__XXX
 SG_ Positionlightssidelights m0 : 56|3@1+ (1,0) [0|7] "" Vector__XXX
 SG_ Frontfoglight m0 : 60|3@1+ (1,0) [0|7] "" Vector__XXX
 SG_ StopRequest m2 : 32|3@1+ (1,0) [0|7] "" Vector__XXX
 SG_ Electricmotorfailures m4 : 8|3@1+ (1,0) [0|7] "" Vector__XXX
 SG_ Batterypack m4 : 20|3@1+ (1,0) [0|7] "" Vector__XXX
 SG_ HVsystemcaution m4 : 24|3@1+ (1,0) [0|7] "" Vector__XXX
 SG_ Batterypacktemperature m4 : 28|3@1+ (1,0) [0|7] "" Vector__XXX
 SG_ Limitedperformanceelectricmtr m4 : 32|3@1+ (1,0) [0|7] "" Vector__XXX
 SG_ Batterypackcooling m4 : 36|3@1+ (1,0) [0|7] "" Vector__XXX

BO_ 2566843431 VI: 200 Vector__XXX

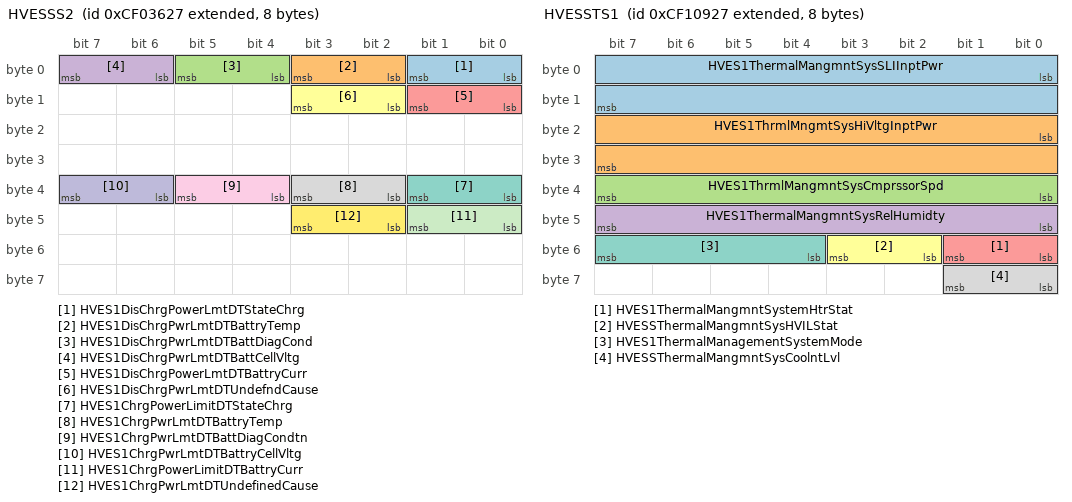
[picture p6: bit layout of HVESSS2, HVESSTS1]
BO_ 2364552743 HVESSS2: 8 Vector__XXX
 SG_ HVES1DisChrgPowerLmtDTStateChrg : 0|2@1+ (1,0) [0|3] "" Vector__XXX
 SG_ HVES1DisChrgPwrLmtDTBattryTemp : 2|2@1+ (1,0) [0|3] "" Vector__XXX
 SG_ HVES1DisChrgPwrLmtDTBattDiagCond : 4|2@1+ (1,0) [0|3] "" Vector__XXX
 SG_ HVES1DisChrgPwrLmtDTBattCellVltg : 6|2@1+ (1,0) [0|3] "" Vector__XXX
 SG_ HVES1DisChrgPowerLmtDTBattryCurr : 8|2@1+ (1,0) [0|3] "" Vector__XXX
 SG_ HVES1DisChrgPwrLmtDTUndefndCause : 10|2@1+ (1,0) [0|3] "" Vector__XXX
 SG_ HVES1ChrgPowerLimitDTStateChrg : 32|2@1+ (1,0) [0|3] "" Vector__XXX
 SG_ HVES1ChrgPwrLmtDTBattryTemp : 34|2@1+ (1,0) [0|3] "" Vector__XXX
 SG_ HVES1ChrgPwrLmtDTBattDiagCondtn : 36|2@1+ (1,0) [0|3] "" Vector__XXX
 SG_ HVES1ChrgPwrLmtDTBattryCellVltg : 38|2@1+ (1,0) [0|3] "" Vector__XXX
 SG_ HVES1ChrgPowerLimitDTBattryCurr : 40|2@1+ (1,0) [0|3] "" Vector__XXX
 SG_ HVES1ChrgPwrLmtDTUndefinedCause : 42|2@1+ (1,0) [0|3] "" Vector__XXX

BO_ 2364606759 HVESSTS1: 8 Vector__XXX
 SG_ HVES1ThermalMangmntSysSLIInptPwr : 0|16@1+ (0.5,0) [0|32127.5] "W" Vector__XXX
 SG_ HVES1ThrmlMngmtSysHiVltgInptPwr : 16|16@1+ (0.5,0) [0|32127.5] "W" Vector__XXX
 SG_ HVES1ThrmlMangmntSysCmprssorSpd : 32|8@1+ (32,0) [0|8000] "rpm" Vector__XXX
 SG_ HVES1ThermalMangmntSysRelHumidty : 40|8@1+ (0.4,0) [0|100] "%" Vector__XXX
 SG_ HVES1ThermalMangmntSystemHtrStat : 48|2@1+ (1,0) [0|3] "" Vector__XXX
 SG_ HVESSThermalMangmntSysHVILStat : 50|2@1+ (1,0) [0|3] "" Vector__XXX
 SG_ HVES1ThermalManagementSystemMode : 52|4@1+ (1,0) [0|15] "" Vector__XXX
 SG_ HVESSThermalMangmntSysCoolntLvl : 56|2@1+ (1,0) [0|3] "" Vector__XXX

BO_ 2566540583 EVEI: 8 Vector__XXX
 SG_ TotalTripEnergyConsumed : 0|32@1+ (0.1,0) [0|421108121.5] "kWh" Vector__XXX
 SG_ TripDriveEnergyEconomy : 32|16@1+ (0.001953125,0) [0|125.49804688] "kWh/km" Vector__XXX

BO_ 2365349415 HVESSHIST: 19 Vector__XXX
 SG_ HVES1StateOfHealth : 0|8@1+ (0.4,0) [0|100] "%" Vector__XXX
 SG_ HVES1ContactorOpenUnderLoadCount : 8|16@1+ (1,0) [0|64255] "" Vector__XXX
 SG_ HVES1TotalEnergyThroughput : 24|32@1+ (100,0) [0|201326492] "Watt-hour" Vector__XXX
 SG_ HVES1TotalAccumulatedCharge : 56|32@1+ (100,0) [0|201326492] "Ah" Vector__XXX
 SG_ HVESSTotalLifetimeEnergyInput : 88|32@1+ (1,0) [0|4211081215] "kWh" Vector__XXX
 SG_ HVESSTotalLifetimeEnergyOutput : 120|32@1+ (1,0) [0|4211081215] "kWh" Vector__XXX

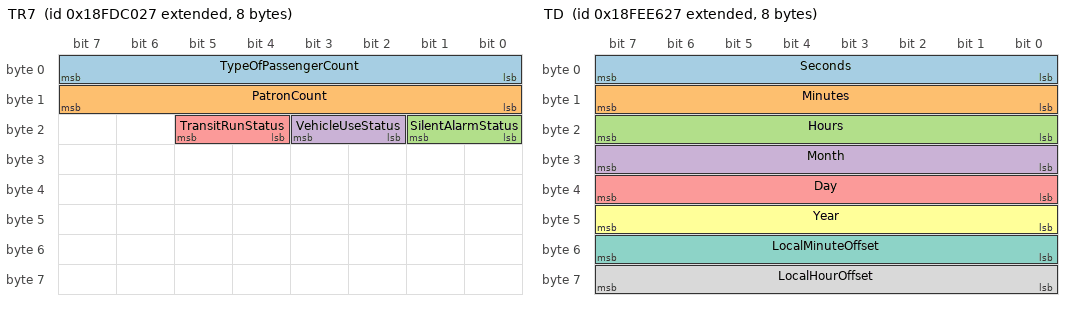
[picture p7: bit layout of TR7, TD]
BO_ 2566766631 TR7: 8 Vector__XXX
 SG_ TypeOfPassengerCount : 0|8@1+ (1,0) [0|255] "" Vector__XXX
 SG_ PatronCount : 8|8@1+ (1,0) [0|250] "" Vector__XXX
 SG_ SilentAlarmStatus : 16|2@1+ (1,0) [0|3] "" Vector__XXX
 SG_ VehicleUseStatus : 18|2@1+ (1,0) [0|3] "" Vector__XXX
 SG_ TransitRunStatus : 20|2@1+ (1,0) [0|3] "" Vector__XXX

BO_ 2566841895 TD: 8 Vector__XXX
 SG_ Seconds : 0|8@1+ (0.25,0) [0|62.5] "s" Vector__XXX
 SG_ Minutes : 8|8@1+ (1,0) [0|250] "min" Vector__XXX
 SG_ Hours : 16|8@1+ (1,0) [0|250] "h" Vector__XXX
 SG_ Month : 24|8@1+ (1,0) [0|250] "month" Vector__XXX
 SG_ Day : 32|8@1+ (0.25,0) [0|62.5] "Days" Vector__XXX
 SG_ Year : 40|8@1+ (1,1985) [1985|2235] "year" Vector__XXX
 SG_ LocalMinuteOffset : 48|8@1+ (1,-125) [-125|125] "min" Vector__XXX
 SG_ LocalHourOffset : 56|8@1+ (1,-125) [-125|125] "h" Vector__XXX

BO_ 2566842151 VH: 8 Vector__XXX
 SG_ TotalVehicleHours : 0|32@1+ (0.05,0) [0|210554060.75] "h" Vector__XXX
 SG_ TotalPowerTakeoffHours : 32|32@1+ (0.05,0) [0|210554060.75] "h" Vector__XXX

BO_ 2566834699 DM1_EBS: 50 Vector__XXX
 SG_ ProtectLamp : 0|2@1+ (1,0) [0|3] "" Vector__XXX
 SG_ AmberWarningLamp : 2|2@1+ (1,0) [0|3] "" Vector__XXX
 SG_ RedStopLamp : 4|2@1+ (1,0) [0|3] "" Vector__XXX
 SG_ MalfunctionIndicatorLamp : 6|2@1+ (1,0) [0|3] "" Vector__XXX
 SG_ FlashProtectLamp : 8|2@1+ (1,0) [0|3] "" Vector__XXX
 SG_ FlashAmberWarningLamp : 10|2@1+ (1,0) [0|3] "" Vector__XXX
 SG_ FlashRedStopLamp : 12|2@1+ (1,0) [0|3] "" Vector__XXX
 SG_ FlashMalfunctionIndicatorLamp : 14|2@1+ (1,0) [0|3] "" Vector__XXX
 SG_ SuspectParameterNumber : 23|19@0+ (1,0) [0|524287] "" Vector__XXX
 SG_ FailureModeIdentifier : 32|5@1+ (1,0) [0|31] "" Vector__XXX
 SG_ OccurrenceCount : 40|7@1+ (1,0) [0|127] "" Vector__XXX
 SG_ SPNConversionMethod : 47|1@1+ (1,0) [0|1] "" Vector__XXX
 SG_ SuspectParameterNumber2 : 39|19@0+ (1,0) [0|524287] "" Vector__XXX
 SG_ FailureModeIdentifier2 : 64|5@1+ (1,0) [0|31] "" Vector__XXX
 SG_ OccurrenceCount2 : 72|7@1+ (1,0) [0|127] "" Vector__XXX
 SG_ SPNConversionMethod2 : 79|1@1+ (1,0) [0|1] "" Vector__XXX
 SG_ SuspectParameterNumber3 : 71|19@0+ (1,0) [0|524287] "" Vector__XXX
 SG_ FailureModeIdentifier3 : 96|5@1+ (1,0) [0|31] "" Vector__XXX
 SG_ OccurrenceCount3 : 104|7@1+ (1,0) [0|127] "" Vector__XXX
 SG_ SPNConversionMethod3 : 111|1@1+ (1,0) [0|1] "" Vector__XXX
 SG_ SuspectParameterNumber4 : 103|19@0+ (1,0) [0|524287] "" Vector__XXX
 SG_ FailureModeIdentifier4 : 128|5@1+ (1,0) [0|31] "" Vector__XXX
 SG_ OccurrenceCount4 : 136|7@1+ (1,0) [0|127] "" Vector__XXX
 SG_ SPNConversionMethod4 : 143|1@1+ (1,0) [0|1] "" Vector__XXX
 SG_ SuspectParameterNumber5 : 135|19@0+ (1,0) [0|524287] "" Vector__XXX
 SG_ FailureModeIdentifier5 : 160|5@1+ (1,0) [0|31] "" Vector__XXX
 SG_ OccurrenceCount5 : 168|7@1+ (1,0) [0|127] "" Vector__XXX
 SG_ SPNConversionMethod5 : 175|1@1+ (1,0) [0|1] "" Vector__XXX
 SG_ SuspectParameterNumber6 : 167|19@0+ (1,0) [0|524287] "" Vector__XXX
 SG_ FailureModeIdentifier6 : 192|5@1+ (1,0) [0|31] "" Vector__XXX
 SG_ OccurrenceCount6 : 200|7@1+ (1,0) [0|127] "" Vector__XXX
 SG_ SPNConversionMethod6 : 207|1@1+ (1,0) [0|1] "" Vector__XXX
 SG_ SuspectParameterNumber7 : 199|19@0+ (1,0) [0|524287] "" Vector__XXX
 SG_ FailureModeIdentifier7 : 224|5@1+ (1,0) [0|31] "" Vector__XXX
 SG_ OccurrenceCount7 : 232|7@1+ (1,0) [0|127] "" Vector__XXX
 SG_ SPNConversionMethod7 : 239|1@1+ (1,0) [0|1] "" Vector__XXX
 SG_ SuspectParameterNumber8 : 231|19@0+ (1,0) [0|524287] "" Vector__XXX
 SG_ FailureModeIdentifier8 : 256|5@1+ (1,0) [0|31] "" Vector__XXX
 SG_ OccurrenceCount8 : 264|7@1+ (1,0) [0|127] "" Vector__XXX
 SG_ SPNConversionMethod8 : 271|1@1+ (1,0) [0|1] "" Vector__XXX
 SG_ SuspectParameterNumber9 : 263|19@0+ (1,0) [0|524287] "" Vector__XXX
 SG_ FailureModeIdentifier9 : 288|5@1+ (1,0) [0|31] "" Vector__XXX
 SG_ OccurrenceCount9 : 296|7@1+ (1,0) [0|127] "" Vector__XXX
 SG_ SPNConversionMethod9 : 303|1@1+ (1,0) [0|1] "" Vector__XXX
 SG_ SuspectParameterNumber10 : 295|19@0+ (1,0) [0|524287] "" Vector__XXX
 SG_ FailureModeIdentifier10 : 320|5@1+ (1,0) [0|31] "" Vector__XXX
 SG_ OccurrenceCount10 : 328|7@1+ (1,0) [0|127] "" Vector__XXX
 SG_ SPNConversionMethod10 : 335|1@1+ (1,0) [0|1] "" Vector__XXX
 SG_ SuspectParameterNumber11 : 327|19@0+ (1,0) [0|524287] "" Vector__XXX
 SG_ FailureModeIdentifier11 : 352|5@1+ (1,0) [0|31] "" Vector__XXX
 SG_ OccurrenceCount11 : 360|7@1+ (1,0) [0|127] "" Vector__XXX
 SG_ SPNConversionMethod11 : 367|1@1+ (1,0) [0|1] "" Vector__XXX
 SG_ SuspectParameterNumber12 : 359|19@0+ (1,0) [0|524287] "" Vector__XXX
 SG_ FailureModeIdentifier12 : 384|5@1+ (1,0) [0|31] "" Vector__XXX
 SG_ OccurrenceCount12 : 392|7@1+ (1,0) [0|127] "" Vector__XXX
 SG_ SPNConversionMethod12 : 399|1@1+ (1,0) [0|1] "" Vector__XXX

BO_ 2566834735 DM1_ECAS: 50 Vector__XXX
 SG_ ProtectLamp : 0|2@1+ (1,0) [0|3] "" Vector__XXX
 SG_ AmberWarningLamp : 2|2@1+ (1,0) [0|3] "" Vector__XXX
 SG_ RedStopLamp : 4|2@1+ (1,0) [0|3] "" Vector__XXX
 SG_ MalfunctionIndicatorLamp : 6|2@1+ (1,0) [0|3] "" Vector__XXX
 SG_ FlashProtectLamp : 8|2@1+ (1,0) [0|3] "" Vector__XXX
 SG_ FlashAmberWarningLamp : 10|2@1+ (1,0) [0|3] "" Vector__XXX
 SG_ FlashRedStopLamp : 12|2@1+ (1,0) [0|3] "" Vector__XXX
 SG_ FlashMalfunctionIndicatorLamp : 14|2@1+ (1,0) [0|3] "" Vector__XXX
 SG_ SuspectParameterNumber : 23|19@0+ (1,0) [0|524287] "" Vector__XXX
 SG_ FailureModeIdentifier : 32|5@1+ (1,0) [0|31] "" Vector__XXX
 SG_ OccurrenceCount : 40|7@1+ (1,0) [0|127] "" Vector__XXX
 SG_ SPNConversionMethod : 47|1@1+ (1,0) [0|1] "" Vector__XXX
 SG_ SuspectParameterNumber2 : 39|19@0+ (1,0) [0|524287] "" Vector__XXX
 SG_ FailureModeIdentifier2 : 64|5@1+ (1,0) [0|31] "" Vector__XXX
 SG_ OccurrenceCount2 : 72|7@1+ (1,0) [0|127] "" Vector__XXX
 SG_ SPNConversionMethod2 : 79|1@1+ (1,0) [0|1] "" Vector__XXX
 SG_ SuspectParameterNumber3 : 71|19@0+ (1,0) [0|524287] "" Vector__XXX
 SG_ FailureModeIdentifier3 : 96|5@1+ (1,0) [0|31] "" Vector__XXX
 SG_ OccurrenceCount3 : 104|7@1+ (1,0) [0|127] "" Vector__XXX
 SG_ SPNConversionMethod3 : 111|1@1+ (1,0) [0|1] "" Vector__XXX
 SG_ SuspectParameterNumber4 : 103|19@0+ (1,0) [0|524287] "" Vector__XXX
 SG_ FailureModeIdentifier4 : 128|5@1+ (1,0) [0|31] "" Vector__XXX
 SG_ OccurrenceCount4 : 136|7@1+ (1,0) [0|127] "" Vector__XXX
 SG_ SPNConversionMethod4 : 143|1@1+ (1,0) [0|1] "" Vector__XXX
 SG_ SuspectParameterNumber5 : 135|19@0+ (1,0) [0|524287] "" Vector__XXX
 SG_ FailureModeIdentifier5 : 160|5@1+ (1,0) [0|31] "" Vector__XXX
 SG_ OccurrenceCount5 : 168|7@1+ (1,0) [0|127] "" Vector__XXX
 SG_ SPNConversionMethod5 : 175|1@1+ (1,0) [0|1] "" Vector__XXX
 SG_ SuspectParameterNumber6 : 167|19@0+ (1,0) [0|524287] "" Vector__XXX
 SG_ FailureModeIdentifier6 : 192|5@1+ (1,0) [0|31] "" Vector__XXX
 SG_ OccurrenceCount6 : 200|7@1+ (1,0) [0|127] "" Vector__XXX
 SG_ SPNConversionMethod6 : 207|1@1+ (1,0) [0|1] "" Vector__XXX
 SG_ SuspectParameterNumber7 : 199|19@0+ (1,0) [0|524287] "" Vector__XXX
 SG_ FailureModeIdentifier7 : 224|5@1+ (1,0) [0|31] "" Vector__XXX
 SG_ OccurrenceCount7 : 232|7@1+ (1,0) [0|127] "" Vector__XXX
 SG_ SPNConversionMethod7 : 239|1@1+ (1,0) [0|1] "" Vector__XXX
 SG_ SuspectParameterNumber8 : 231|19@0+ (1,0) [0|524287] "" Vector__XXX
 SG_ FailureModeIdentifier8 : 256|5@1+ (1,0) [0|31] "" Vector__XXX
 SG_ OccurrenceCount8 : 264|7@1+ (1,0) [0|127] "" Vector__XXX
 SG_ SPNConversionMethod8 : 271|1@1+ (1,0) [0|1] "" Vector__XXX
 SG_ SuspectParameterNumber9 : 263|19@0+ (1,0) [0|524287] "" Vector__XXX
 SG_ FailureModeIdentifier9 : 288|5@1+ (1,0) [0|31] "" Vector__XXX
 SG_ OccurrenceCount9 : 296|7@1+ (1,0) [0|127] "" Vector__XXX
 SG_ SPNConversionMethod9 : 303|1@1+ (1,0) [0|1] "" Vector__XXX
 SG_ SuspectParameterNumber10 : 295|19@0+ (1,0) [0|524287] "" Vector__XXX
 SG_ FailureModeIdentifier10 : 320|5@1+ (1,0) [0|31] "" Vector__XXX
 SG_ OccurrenceCount10 : 328|7@1+ (1,0) [0|127] "" Vector__XXX
 SG_ SPNConversionMethod10 : 335|1@1+ (1,0) [0|1] "" Vector__XXX
 SG_ SuspectParameterNumber11 : 327|19@0+ (1,0) [0|524287] "" Vector__XXX
 SG_ FailureModeIdentifier11 : 352|5@1+ (1,0) [0|31] "" Vector__XXX
 SG_ OccurrenceCount11 : 360|7@1+ (1,0) [0|127] "" Vector__XXX
 SG_ SPNConversionMethod11 : 367|1@1+ (1,0) [0|1] "" Vector__XXX
 SG_ SuspectParameterNumber12 : 359|19@0+ (1,0) [0|524287] "" Vector__XXX
 SG_ FailureModeIdentifier12 : 384|5@1+ (1,0) [0|31] "" Vector__XXX
 SG_ OccurrenceCount12 : 392|7@1+ (1,0) [0|127] "" Vector__XXX
 SG_ SPNConversionMethod12 : 399|1@1+ (1,0) [0|1] "" Vector__XXX

BO_ 2566834778 DM1_ZF: 50 Vector__XXX
 SG_ ProtectLamp : 0|2@1+ (1,0) [0|3] "" Vector__XXX
 SG_ AmberWarningLamp : 2|2@1+ (1,0) [0|3] "" Vector__XXX
 SG_ RedStopLamp : 4|2@1+ (1,0) [0|3] "" Vector__XXX
 SG_ MalfunctionIndicatorLamp : 6|2@1+ (1,0) [0|3] "" Vector__XXX
 SG_ FlashProtectLamp : 8|2@1+ (1,0) [0|3] "" Vector__XXX
 SG_ FlashAmberWarningLamp : 10|2@1+ (1,0) [0|3] "" Vector__XXX
 SG_ FlashRedStopLamp : 12|2@1+ (1,0) [0|3] "" Vector__XXX
 SG_ FlashMalfunctionIndicatorLamp : 14|2@1+ (1,0) [0|3] "" Vector__XXX
 SG_ SuspectParameterNumber : 23|19@0+ (1,0) [0|524287] "" Vector__XXX
 SG_ FailureModeIdentifier : 32|5@1+ (1,0) [0|31] "" Vector__XXX
 SG_ OccurrenceCount : 40|7@1+ (1,0) [0|127] "" Vector__XXX
 SG_ SPNConversionMethod : 47|1@1+ (1,0) [0|1] "" Vector__XXX
 SG_ SuspectParameterNumber2 : 39|19@0+ (1,0) [0|524287] "" Vector__XXX
 SG_ FailureModeIdentifier2 : 64|5@1+ (1,0) [0|31] "" Vector__XXX
 SG_ OccurrenceCount2 : 72|7@1+ (1,0) [0|127] "" Vector__XXX
 SG_ SPNConversionMethod2 : 79|1@1+ (1,0) [0|1] "" Vector__XXX
 SG_ SuspectParameterNumber3 : 71|19@0+ (1,0) [0|524287] "" Vector__XXX
 SG_ FailureModeIdentifier3 : 96|5@1+ (1,0) [0|31] "" Vector__XXX
 SG_ OccurrenceCount3 : 104|7@1+ (1,0) [0|127] "" Vector__XXX
 SG_ SPNConversionMethod3 : 111|1@1+ (1,0) [0|1] "" Vector__XXX
 SG_ SuspectParameterNumber4 : 103|19@0+ (1,0) [0|524287] "" Vector__XXX
 SG_ FailureModeIdentifier4 : 128|5@1+ (1,0) [0|31] "" Vector__XXX
 SG_ OccurrenceCount4 : 136|7@1+ (1,0) [0|127] "" Vector__XXX
 SG_ SPNConversionMethod4 : 143|1@1+ (1,0) [0|1] "" Vector__XXX
 SG_ SuspectParameterNumber5 : 135|19@0+ (1,0) [0|524287] "" Vector__XXX
 SG_ FailureModeIdentifier5 : 160|5@1+ (1,0) [0|31] "" Vector__XXX
 SG_ OccurrenceCount5 : 168|7@1+ (1,0) [0|127] "" Vector__XXX
 SG_ SPNConversionMethod5 : 175|1@1+ (1,0) [0|1] "" Vector__XXX
 SG_ SuspectParameterNumber6 : 167|19@0+ (1,0) [0|524287] "" Vector__XXX
 SG_ FailureModeIdentifier6 : 192|5@1+ (1,0) [0|31] "" Vector__XXX
 SG_ OccurrenceCount6 : 200|7@1+ (1,0) [0|127] "" Vector__XXX
 SG_ SPNConversionMethod6 : 207|1@1+ (1,0) [0|1] "" Vector__XXX
 SG_ SuspectParameterNumber7 : 199|19@0+ (1,0) [0|524287] "" Vector__XXX
 SG_ FailureModeIdentifier7 : 224|5@1+ (1,0) [0|31] "" Vector__XXX
 SG_ OccurrenceCount7 : 232|7@1+ (1,0) [0|127] "" Vector__XXX
 SG_ SPNConversionMethod7 : 239|1@1+ (1,0) [0|1] "" Vector__XXX
 SG_ SuspectParameterNumber8 : 231|19@0+ (1,0) [0|524287] "" Vector__XXX
 SG_ FailureModeIdentifier8 : 256|5@1+ (1,0) [0|31] "" Vector__XXX
 SG_ OccurrenceCount8 : 264|7@1+ (1,0) [0|127] "" Vector__XXX
 SG_ SPNConversionMethod8 : 271|1@1+ (1,0) [0|1] "" Vector__XXX
 SG_ SuspectParameterNumber9 : 263|19@0+ (1,0) [0|524287] "" Vector__XXX
 SG_ FailureModeIdentifier9 : 288|5@1+ (1,0) [0|31] "" Vector__XXX
 SG_ OccurrenceCount9 : 296|7@1+ (1,0) [0|127] "" Vector__XXX
 SG_ SPNConversionMethod9 : 303|1@1+ (1,0) [0|1] "" Vector__XXX
 SG_ SuspectParameterNumber10 : 295|19@0+ (1,0) [0|524287] "" Vector__XXX
 SG_ FailureModeIdentifier10 : 320|5@1+ (1,0) [0|31] "" Vector__XXX
 SG_ OccurrenceCount10 : 328|7@1+ (1,0) [0|127] "" Vector__XXX
 SG_ SPNConversionMethod10 : 335|1@1+ (1,0) [0|1] "" Vector__XXX
 SG_ SuspectParameterNumber11 : 327|19@0+ (1,0) [0|524287] "" Vector__XXX
 SG_ FailureModeIdentifier11 : 352|5@1+ (1,0) [0|31] "" Vector__XXX
 SG_ OccurrenceCount11 : 360|7@1+ (1,0) [0|127] "" Vector__XXX
 SG_ SPNConversionMethod11 : 367|1@1+ (1,0) [0|1] "" Vector__XXX
 SG_ SuspectParameterNumber12 : 359|19@0+ (1,0) [0|524287] "" Vector__XXX
 SG_ FailureModeIdentifier12 : 384|5@1+ (1,0) [0|31] "" Vector__XXX
 SG_ OccurrenceCount12 : 392|7@1+ (1,0) [0|127] "" Vector__XXX
 SG_ SPNConversionMethod12 : 399|1@1+ (1,0) [0|1] "" Vector__XXX

CM_ BO_ 2365524759 "Proprietary B (0Bh) (Dash IO)";
CM_ BO_ 2365524513 "Proprietary B - Page 1 (0Ah)";
CM_ BO_ 2566759713 "Door Control 2";
CM_ BO_ 2566802977 "Door Control 1";
CM_ BO_ 2350644759 "High Voltage Energy Storage System Control 1";
CM_ BO_ 2565865739 "Electronic Brake Controller 1";
CM_ BO_ 2364575777 "High Voltage Energy Storage System Data 1";
CM_ BO_ 2364576033 "High Voltage Energy Storage System Data 2";
CM_ BO_ 2566545953 "Lighting Data 2";
CM_ BO_ 2365219607 "Lighting Command 2";
CM_ BO_ 2499547671 "Cab Door Control 1";
CM_ BO_ 2566771745 "Cab Message 3";
CM_ BO_ 2566799393 "Lighting Data";
CM_ BO_ 2365473047 "Lighting Command";
CM_ BO_ 2566827553 "Air Supply Pressure";
CM_ BO_ 2566844705 "Cruise Control/Vehicle Speed 1";
CM_ BO_ 2566845729 "Ambient Conditions";
CM_ BO_ 2364577313 "High Voltage Energy Storage System Status 1, Proterra VIC";
CM_ BO_ 2566900513 "Proprietary: [PropB_CA] Needs Definition";
CM_ BO_ 2365479471 "Air Suspension Control 1";
CM_ BO_ 2364607265 "High Voltage Energy Storage System Data 9";
CM_ SG_ 2364607265 HvssHghstCllTmprtrMdlNmr "HVESS Highest Cell Temperature Module Number: Identifies the location of the module containing SPN 8075 (HVESS Highest Cell Temperature).This parameter provides HVES system level information. If there are multiple packs in the system, then both indiv...";
CM_ SG_ 2364607265 HvssHghstCllTmprtrCllNmr "HVESS Highest Cell Temperature Cell Number: Identifies the location of SPN 8075 (HVESS Highest Cell Temperature) within SPN 8241 (HVESS Highest Cell Temperature Module Number).This parameter provides HVES system level information. If there are multip...";
CM_ SG_ 2364607265 HvssLwstCllTmprtrMdlNmr "HVESS Lowest Cell Temperature Module Number: Identifies the location of the module containing SPN 8076 (HVESS Lowest Cell Temperature ).This parameter provides HVES system level information. If there are multiple packs in the system, then both indivi...";
CM_ SG_ 2364607265 HvssLwstCllTmprtrCllNmr "HVESS Lowest Cell Temperature Cell Number: Identifies the location of SPN 8076 (HVESS Lowest Cell Temperature) within SPN 8243 (HVESS Lowest Cell Temperature Module Number).This parameter provides HVES system level information. If there are multiple ...";
CM_ SG_ 2364607265 HvessThermalEventDetected "HVESS Thermal Event Detected: A sensor has detected the presence of a thermal event at or near High Voltage Energy Storage System  (or Pack 1 in systems with only one pack).00b = No Thermal Event Detected01b = Thermal Event Detected10b = Error11b = N...";
CM_ BO_ 2565866785 "Electronic Transmission Controller 2";
CM_ BO_ 2566719265 "Direct Lamp Control Command 1";
CM_ BO_ 2566749463 "Reserved for FMS Telltale status";
CM_ BO_ 2566843431 "Vehicle Identification";
CM_ BO_ 2364552743 "High Voltage Energy Storage System Status 2";
CM_ BO_ 2364606759 "High Voltage Energy Storage System Thermal Management System Status 1";
CM_ BO_ 2566540583 "EV Economy Information";
CM_ BO_ 2365349415 "High Voltage Energy Storage System History";
CM_ BO_ 2566766631 "Passenger Counter";
CM_ BO_ 2566841895 "Time/Date";
CM_ BO_ 2566842151 "Vehicle Hours";
CM_ BO_ 2566834699 "Active Diagnostic Trouble Codes";
CM_ BO_ 2566834735 "Active Diagnostic Trouble Codes";
CM_ BO_ 2566834778 "Active Diagnostic Trouble Codes";
BA_DEF_  "BusType" STRING ;
BA_DEF_  "ProtocolType" STRING ;
BA_DEF_ BO_  "VFrameFormat" ENUM  "StandardCAN","ExtendedCAN","reserved","J1939PG";
BA_DEF_ BO_  "GenMsgCycleTime" INT 0 65535;
BA_DEF_ SG_  "GenSigStartValue" FLOAT -3.4e+38 3.4e+38;
BA_DEF_ SG_  "SPN" INT 0 655350;
BA_DEF_DEF_  "BusType" "CAN";
BA_DEF_DEF_  "ProtocolType" "J1939";
BA_DEF_DEF_  "VFrameFormat" "J1939PG";
BA_DEF_DEF_  "GenMsgCycleTime" 0;
BA_DEF_DEF_  "GenSigStartValue" 0;
BA_DEF_DEF_  "SPN" 0;
BA_ "GenMsgCycleTime" BO_ 2365524759 1000;
BA_ "GenSigStartValue" SG_ 2365524759 LightCheckSwitch 3;
BA_ "GenSigStartValue" SG_ 2365524759 D1DemistSwitch 3;
BA_ "GenSigStartValue" SG_ 2365524759 SchoolFlashSwitch 3;
BA_ "GenSigStartValue" SG_ 2365524759 BellCancelSwitch 3;
BA_ "GenSigStartValue" SG_ 2365524759 MapLightSwitch 3;
BA_ "GenSigStartValue" SG_ 2365524759 CabLightSwitch 3;
BA_ "GenSigStartValue" SG_ 2365524759 D1Switch 3;
BA_ "GenSigStartValue" SG_ 2365524759 D2Switch 3;
BA_ "GenSigStartValue" SG_ 2365524759 Switch_2S_10 3;
BA_ "GenSigStartValue" SG_ 2365524759 Switch_2S_11 3;
BA_ "GenSigStartValue" SG_ 2365524759 Switch_2S_12 3;
BA_ "GenSigStartValue" SG_ 2365524759 Switch_2S_13 3;
BA_ "GenSigStartValue" SG_ 2365524759 Switch_2S_14 3;
BA_ "GenSigStartValue" SG_ 2365524759 Switch_2S_15 3;
BA_ "GenSigStartValue" SG_ 2365524759 Switch_2S_16 3;
BA_ "GenSigStartValue" SG_ 2365524759 Switch_2S_17 3;
BA_ "GenSigStartValue" SG_ 2365524759 ECASSwitch 7;
BA_ "GenSigStartValue" SG_ 2365524759 DemistFanSwitch 7;
BA_ "GenSigStartValue" SG_ 2365524759 DriverFanSwitch 7;
BA_ "GenSigStartValue" SG_ 2365524759 SaloonLightSwitch 7;
BA_ "GenSigStartValue" SG_ 2365524759 RTRH_Switch 7;
BA_ "GenSigStartValue" SG_ 2365524759 DemistTempSwitch 7;
BA_ "GenSigStartValue" SG_ 2365524759 Switch_3S_7 7;
BA_ "GenSigStartValue" SG_ 2365524759 Switch_3S_8 7;
BA_ "GenSigStartValue" SG_ 2365524759 Switch_3S_9 7;
BA_ "GenSigStartValue" SG_ 2365524759 Switch_3S_10 7;
BA_ "GenSigStartValue" SG_ 2365524759 Switch_2S_9 3;
BA_ "GenMsgCycleTime" BO_ 2365524513 1000;
BA_ "GenMsgCycleTime" BO_ 2355220689 10;
BA_ "GenMsgCycleTime" BO_ 2355351761 100;
BA_ "GenMsgCycleTime" BO_ 2566759713 100;
BA_ "SPN" SG_ 2566759713 LockStatusOfDoor1 3412;
BA_ "SPN" SG_ 2566759713 OpenStatusOfDoor1 3413;
BA_ "SPN" SG_ 2566759713 EnableStatusOfDoor1 3414;
BA_ "SPN" SG_ 2566759713 LockStatusOfDoor2 3415;
BA_ "SPN" SG_ 2566759713 OpenStatusOfDoor2 3416;
BA_ "SPN" SG_ 2566759713 EnableStatusOfDoor2 3417;
BA_ "SPN" SG_ 2566759713 LockStatusOfDoor3 3418;
BA_ "SPN" SG_ 2566759713 OpenStatusOfDoor3 3419;
BA_ "SPN" SG_ 2566759713 EnableStatusOfDoor3 3420;
BA_ "SPN" SG_ 2566759713 LockStatusOfDoor4 3421;
BA_ "SPN" SG_ 2566759713 OpenStatusOfDoor4 3422;
BA_ "SPN" SG_ 2566759713 EnableStatusOfDoor4 3423;
BA_ "SPN" SG_ 2566759713 LockStatusOfDoor5 3424;
BA_ "SPN" SG_ 2566759713 OpenStatusOfDoor5 3425;
BA_ "SPN" SG_ 2566759713 EnableStatusOfDoor5 3426;
BA_ "SPN" SG_ 2566759713 LockStatusOfDoor6 3427;
BA_ "SPN" SG_ 2566759713 OpenStatusOfDoor6 3428;
BA_ "SPN" SG_ 2566759713 EnableStatusOfDoor6 3429;
BA_ "SPN" SG_ 2566759713 LockStatusOfDoor7 3430;
BA_ "SPN" SG_ 2566759713 OpenStatusOfDoor7 3431;
BA_ "SPN" SG_ 2566759713 EnableStatusOfDoor7 3432;
BA_ "SPN" SG_ 2566759713 LockStatusOfDoor8 3433;
BA_ "SPN" SG_ 2566759713 OpenStatusOfDoor8 3434;
BA_ "SPN" SG_ 2566759713 EnableStatusOfDoor8 3435;
BA_ "SPN" SG_ 2566759713 LockStatusOfDoor9 3436;
BA_ "SPN" SG_ 2566759713 OpenStatusOfDoor9 3437;
BA_ "SPN" SG_ 2566759713 EnableStatusOfDoor9 3438;
BA_ "SPN" SG_ 2566759713 LockStatusOfDoor10 3439;
BA_ "SPN" SG_ 2566759713 OpenStatusOfDoor10 3440;
BA_ "SPN" SG_ 2566759713 EnableStatusOfDoor10 3441;
BA_ "GenMsgCycleTime" BO_ 2566802977 100;
BA_ "SPN" SG_ 2566802977 PositionOfDoors 1821;
BA_ "SPN" SG_ 2566802977 RampWheelChairLiftPosition 1820;
BA_ "SPN" SG_ 2566802977 Status2OfDoors 3411;
BA_ "GenMsgCycleTime" BO_ 2350644759 20;
BA_ "SPN" SG_ 2350644759 HVES1HighVoltageBusConnectCmd 8123;
BA_ "SPN" SG_ 2350644759 HVES1PowerDownCommand 8124;
BA_ "SPN" SG_ 2350644759 HVES1HghVltgBusActIsolatnTestCmd 8125;
BA_ "SPN" SG_ 2350644759 HVES1HiVltgBusPassIsolatnTestCmd 8126;
BA_ "SPN" SG_ 2350644759 HVES1CellBalancingCommand 8127;
BA_ "SPN" SG_ 2350644759 HVES1EnableInternalChrgrCommand 8213;
BA_ "SPN" SG_ 2350644759 HVES1OperationConsent 8412;
BA_ "SPN" SG_ 2350644759 HVES1HiVltgBusHiSdeResistCnnctRq 8433;
BA_ "SPN" SG_ 2350644759 HVES1HiVltgBusLoSdeResistCnnctRq 8434;
BA_ "SPN" SG_ 2350644759 HVESSThermalMangmntMaintenRq 20878;
BA_ "SPN" SG_ 2350644759 HVESSControl1Counter 13027;
BA_ "SPN" SG_ 2350644759 HVESSControl1CRC 13028;
BA_ "GenMsgCycleTime" BO_ 2565865739 100;
BA_ "SPN" SG_ 2565865739 ASREngineControlActive 561;
BA_ "SPN" SG_ 2565865739 ASRBrakeControlActive 562;
BA_ "SPN" SG_ 2565865739 AntiLockBrakingActive 563;
BA_ "SPN" SG_ 2565865739 EBSBrakeSwitch 1121;
BA_ "SPN" SG_ 2565865739 BrakePedalPosition 521;
BA_ "SPN" SG_ 2565865739 ABSOffRoadSwitch 575;
BA_ "SPN" SG_ 2565865739 ASROffRoadSwitch 576;
BA_ "SPN" SG_ 2565865739 ASRHillHolderSwitch 577;
BA_ "SPN" SG_ 2565865739 TractionControlOverrideSwitch 1238;
BA_ "SPN" SG_ 2565865739 AcceleratorInterlockSwitch 972;
BA_ "SPN" SG_ 2565865739 EngineDerateSwitch 971;
BA_ "SPN" SG_ 2565865739 EngineAuxiliaryShutdownSwitch 970;
BA_ "SPN" SG_ 2565865739 RemoteAcceleratorEnableSwitch 969;
BA_ "SPN" SG_ 2565865739 EngineRetarderSelection 973;
BA_ "SPN" SG_ 2565865739 ABSFullyOperational 1243;
BA_ "SPN" SG_ 2565865739 EBSRedWarningSignal 1439;
BA_ "SPN" SG_ 2565865739 ABSEBSAmberWarningSignal 1438;
BA_ "SPN" SG_ 2565865739 ATCASRInformationSignal 1793;
BA_ "SPN" SG_ 2565865739 SrcAddrOfCtrllingDevForBrkCtrl 1481;
BA_ "SPN" SG_ 2565865739 RailroadModeSwitch 7941;
BA_ "SPN" SG_ 2565865739 HaltBrakeSwitch 2911;
BA_ "SPN" SG_ 2565865739 TrailerABSStatus 1836;
BA_ "SPN" SG_ 2565865739 TractorMntdTrailerABSWarningSig 1792;
BA_ "GenMsgCycleTime" BO_ 2364575777 20;
BA_ "SPN" SG_ 2364575777 HVES1AvailableDischargePower 5917;
BA_ "SPN" SG_ 2364575777 HVES1AvailableChargePower 5918;
BA_ "SPN" SG_ 2364575777 HVES1VoltageLevel 5919;
BA_ "SPN" SG_ 2364575777 HVES1Current 5920;
BA_ "GenMsgCycleTime" BO_ 2364576033 20;
BA_ "SPN" SG_ 2364576033 HVES1FastUpdateStateOfCharge 5921;
BA_ "SPN" SG_ 2364576033 HVES1HighestCellVoltage 5922;
BA_ "SPN" SG_ 2364576033 HVES1LowestCellVoltage 5923;
BA_ "SPN" SG_ 2364576033 HVES1CellVoltageDiffStatus 5924;
BA_ "GenMsgCycleTime" BO_ 2566545953 1000;
BA_ "SPN" SG_ 2566545953 TractorHazardLights 20800;
BA_ "GenMsgCycleTime" BO_ 2365219607 1000;
BA_ "SPN" SG_ 2365219607 LightingData2RequestCommand 20798;
BA_ "SPN" SG_ 2365219607 TractorHazardLightsCommand 20799;
BA_ "GenMsgCycleTime" BO_ 2499547671 1000;
BA_ "SPN" SG_ 2499547671 CabDoorsLockActuationCommand 7727;
BA_ "SPN" SG_ 2499547671 RemoteCabDoorLockRequest 7728;
BA_ "SPN" SG_ 2499547671 LeftFrontWindowPositionCommand 7729;
BA_ "SPN" SG_ 2499547671 RightFrontWindowPositionCommand 7730;
BA_ "SPN" SG_ 2499547671 MirrorFoldingSwitch 12317;
BA_ "SPN" SG_ 2499547671 LeftRearWindowPositionCommand 7731;
BA_ "SPN" SG_ 2499547671 RightRearWindowPositionCommand 7732;
BA_ "SPN" SG_ 2499547671 MirrorAutoPanningEnable 12318;
BA_ "SPN" SG_ 2499547671 MirrorLeft1HorizontalCommand 7733;
BA_ "SPN" SG_ 2499547671 MirrorLeft1VerticalCommand 7734;
BA_ "SPN" SG_ 2499547671 MirrorRight1HorizontalCommand 7735;
BA_ "SPN" SG_ 2499547671 MirrorRight1VerticalCommand 7736;
BA_ "SPN" SG_ 2499547671 MirrorLeft2HorizontalCommand 7737;
BA_ "SPN" SG_ 2499547671 MirrorLeft2VerticalCommand 7738;
BA_ "SPN" SG_ 2499547671 MirrorRight2HorizontalCommand 7739;
BA_ "SPN" SG_ 2499547671 MirrorRight2VerticalCommand 7740;
BA_ "SPN" SG_ 2499547671 MirrorLeft1HeatCommand 7741;
BA_ "SPN" SG_ 2499547671 MirrorRight1HeatCommand 7742;
BA_ "SPN" SG_ 2499547671 MirrorLeft2HeatCommand 7743;
BA_ "SPN" SG_ 2499547671 MirrorRight2HeatCommand 7744;
BA_ "GenMsgCycleTime" BO_ 2566771745 10000;
BA_ "SPN" SG_ 2566771745 TransferCaseSelectorSwitch 2796;
BA_ "SPN" SG_ 2566771745 AfttreatmentSCRDosingModeCommand 9175;
BA_ "SPN" SG_ 2566771745 MomentaryOperatorKeySwitch 9842;
BA_ "SPN" SG_ 2566771745 FifthWheelReleaseControl 3314;
BA_ "SPN" SG_ 2566771745 FifthWhlReleaseCtrlSecurityLckt 3315;
BA_ "SPN" SG_ 2566771745 VehicleTrailerStatus 7711;
BA_ "SPN" SG_ 2566771745 OperatorKeyDetected 10144;
BA_ "SPN" SG_ 2566771745 TransmissionOilLevelRequest 3809;
BA_ "SPN" SG_ 2566771745 OperatorKeySwitchAccessoryPower 3996;
BA_ "SPN" SG_ 2566771745 OperatorKeySwitchIgnitionPower 10145;
BA_ "SPN" SG_ 2566771745 OperatorKeySwitchStart 10146;
BA_ "SPN" SG_ 2566771745 OprtrKeySwitchDelayedBattryOff 10147;
BA_ "SPN" SG_ 2566771745 HornSwitch 2641;
BA_ "SPN" SG_ 2566771745 EngineAirShutoffTestSwitch 13363;
BA_ "SPN" SG_ 2566771745 EngineAirShutoffManualSwitch 13364;
BA_ "SPN" SG_ 2566771745 OperatorKeySwitchService 21126;
BA_ "SPN" SG_ 2566771745 OperatorKeySwitchOff 21127;
BA_ "SPN" SG_ 2566771745 RemoteKeyFobFunctionRequested 21139;
BA_ "GenMsgCycleTime" BO_ 2566799393 1000;
BA_ "SPN" SG_ 2566799393 RunningLight 2404;
BA_ "SPN" SG_ 2566799393 AlternateBeamHeadLightData 2352;
BA_ "SPN" SG_ 2566799393 LowBeamHeadLightData 2350;
BA_ "SPN" SG_ 2566799393 HighBeamHeadLightData 2348;
BA_ "SPN" SG_ 2566799393 TractorFrontFogLights 2388;
BA_ "SPN" SG_ 2566799393 RotatingBeaconLight 2386;
BA_ "SPN" SG_ 2566799393 RightTurnSignalLights 2370;
BA_ "SPN" SG_ 2566799393 LeftTurnSignalLights 2368;
BA_ "SPN" SG_ 2566799393 BackUpLightAndAlarmHorn 2392;
BA_ "SPN" SG_ 2566799393 CenterStopLight 2376;
BA_ "SPN" SG_ 2566799393 RightStopLight 2374;
BA_ "SPN" SG_ 2566799393 LeftStopLight 2372;
BA_ "SPN" SG_ 2566799393 ImplementClearanceLight 2384;
BA_ "SPN" SG_ 2566799393 TractorClearanceLight 2382;
BA_ "SPN" SG_ 2566799393 ImplementMarkerLight 2380;
BA_ "SPN" SG_ 2566799393 TractorMarkerLight 2378;
BA_ "SPN" SG_ 2566799393 RearFogLights 2390;
BA_ "SPN" SG_ 2566799393 TractorUndersideMntdWorkLights 2358;
BA_ "SPN" SG_ 2566799393 TractorRearLowMountedWorkLights 2360;
BA_ "SPN" SG_ 2566799393 TractorRearHighMountedWorkLights 2362;
BA_ "SPN" SG_ 2566799393 TractorSideLowMountedWorkLights 2364;
BA_ "SPN" SG_ 2566799393 TractorSideHighMountedWorkLights 2366;
BA_ "SPN" SG_ 2566799393 TractorFrontLowMountedWorkLights 2354;
BA_ "SPN" SG_ 2566799393 TractorFrntHighMountedWorkLights 2356;
BA_ "SPN" SG_ 2566799393 ImplementOEMOption2Light 2398;
BA_ "SPN" SG_ 2566799393 ImplementOEMOption1Light 2396;
BA_ "SPN" SG_ 2566799393 ImplementRightFacingWorkLight 2407;
BA_ "SPN" SG_ 2566799393 ImplementLeftForwardWorkLight 2598;
BA_ "SPN" SG_ 2566799393 ImplementRightForwardWorkLight 2402;
BA_ "SPN" SG_ 2566799393 ImplementLeftFacingWorkLight 2400;
BA_ "SPN" SG_ 2566799393 ImplementRearWorkLight 2394;
BA_ "GenMsgCycleTime" BO_ 2365473047 1000;
BA_ "SPN" SG_ 2365473047 RunningLightCommand 2403;
BA_ "SPN" SG_ 2365473047 AlternateBeamHeadLightCommand 2351;
BA_ "SPN" SG_ 2365473047 LowBeamHeadLightCommand 2349;
BA_ "SPN" SG_ 2365473047 HighBeamHeadLightCommand 2347;
BA_ "SPN" SG_ 2365473047 TractorFrontFogLightsCommand 2387;
BA_ "SPN" SG_ 2365473047 RotatingBeaconLightCommand 2385;
BA_ "SPN" SG_ 2365473047 RightTurnSignalLightsCommand 2369;
BA_ "SPN" SG_ 2365473047 LeftTurnSignalLightsCommand 2367;
BA_ "SPN" SG_ 2365473047 BackUpLightAndAlarmHornCommand 2391;
BA_ "SPN" SG_ 2365473047 CenterStopLightCommand 2375;
BA_ "SPN" SG_ 2365473047 RightStopLightCommand 2373;
BA_ "SPN" SG_ 2365473047 LeftStopLightCommand 2371;
BA_ "SPN" SG_ 2365473047 ImplementClearanceLightCommand 2383;
BA_ "SPN" SG_ 2365473047 TractorClearanceLightCommand 2381;
BA_ "SPN" SG_ 2365473047 ImplementMarkerLightCommand 2379;
BA_ "SPN" SG_ 2365473047 TractorMarkerLightCommand 2377;
BA_ "SPN" SG_ 2365473047 RearFogLightCommand 2389;
BA_ "SPN" SG_ 2365473047 TractorUnderSdeMntdWorkLightsCmd 2357;
BA_ "SPN" SG_ 2365473047 TractorRearLowMntdWorkLightsCmd 2359;
BA_ "SPN" SG_ 2365473047 TractorRearHghMntdWorkLightsCmd 2361;
BA_ "SPN" SG_ 2365473047 TractorSideLowMntdWorkLightsCmd 2363;
BA_ "SPN" SG_ 2365473047 TractorSideHghMntdWorkLightsCmd 2365;
BA_ "SPN" SG_ 2365473047 TractorFrntLowMntdWorkLightsCmd 2353;
BA_ "SPN" SG_ 2365473047 TractorFrntHghMntdWorkLightsCmd 2355;
BA_ "SPN" SG_ 2365473047 ImplementOEMOption2LightCommand 2397;
BA_ "SPN" SG_ 2365473047 ImplementOEMOption1LightCommand 2395;
BA_ "SPN" SG_ 2365473047 ImplementRightFacingWorkLightCmd 2406;
BA_ "SPN" SG_ 2365473047 ImplementLeftForwardWorkLightCmd 2597;
BA_ "SPN" SG_ 2365473047 LightingDataRequestCommand 2393;
BA_ "SPN" SG_ 2365473047 ImplementRightFrwdWorkLightCmd 2401;
BA_ "SPN" SG_ 2365473047 ImplementLeftFacingWorkLightCmd 2399;
BA_ "SPN" SG_ 2365473047 ImplementRearWorkLightCommand 2405;
BA_ "GenMsgCycleTime" BO_ 2566827553 1000;
BA_ "SPN" SG_ 2566827553 PneumaticSupplyPressure 46;
BA_ "SPN" SG_ 2566827553 ParkingAndOrTrailerAirPressure 1086;
BA_ "SPN" SG_ 2566827553 ServiceBrakeCircuit1AirPressure 1087;
BA_ "SPN" SG_ 2566827553 ServiceBrakeCircuit2AirPressure 1088;
BA_ "SPN" SG_ 2566827553 AuxiliaryEquipmentSupplyPressure 1089;
BA_ "SPN" SG_ 2566827553 AirSuspensionSupplyPressure 1090;
BA_ "SPN" SG_ 2566827553 AirCompressorStatus 1351;
BA_ "SPN" SG_ 2566827553 PwrtrainCircuitAirSupplyPressure 6305;
BA_ "GenMsgCycleTime" BO_ 2566844705 100;
BA_ "SPN" SG_ 2566844705 TwoSpeedAxleSwitch 69;
BA_ "SPN" SG_ 2566844705 ParkingBrakeSwitch 70;
BA_ "SPN" SG_ 2566844705 CruiseControlPauseSwitch 1633;
BA_ "SPN" SG_ 2566844705 ParkBrakeReleaseInhibitRequest 3807;
BA_ "SPN" SG_ 2566844705 WheelBasedVehicleSpeed 84;
BA_ "SPN" SG_ 2566844705 CruiseControlActive 595;
BA_ "SPN" SG_ 2566844705 CruiseControlEnableSwitch 596;
BA_ "SPN" SG_ 2566844705 BrakeSwitch 597;
BA_ "SPN" SG_ 2566844705 ClutchSwitch 598;
BA_ "SPN" SG_ 2566844705 CruiseControlSetSwitch 599;
BA_ "SPN" SG_ 2566844705 CruiseControlCoastSwitch 600;
BA_ "SPN" SG_ 2566844705 CruiseControlResumeSwitch 601;
BA_ "SPN" SG_ 2566844705 CruiseControlAccelerateSwitch 602;
BA_ "SPN" SG_ 2566844705 CruiseControlSetSpeed 86;
BA_ "SPN" SG_ 2566844705 PTOGovernorState 976;
BA_ "SPN" SG_ 2566844705 CruiseControlStates 527;
BA_ "SPN" SG_ 2566844705 EngineIdleIncrementSwitch 968;
BA_ "SPN" SG_ 2566844705 EngineIdleDecrementSwitch 967;
BA_ "SPN" SG_ 2566844705 EngineDiagnosticTestModeSwitch 966;
BA_ "SPN" SG_ 2566844705 EngineShutdownOverrideSwitch 1237;
BA_ "GenMsgCycleTime" BO_ 2566845729 1000;
BA_ "SPN" SG_ 2566845729 BarometricPressure 108;
BA_ "SPN" SG_ 2566845729 CabInteriorTemperature 170;
BA_ "SPN" SG_ 2566845729 AmbientAirTemperature 171;
BA_ "SPN" SG_ 2566845729 EngineIntakeAirTemperature 172;
BA_ "SPN" SG_ 2566845729 RoadSurfaceTemperature 79;
BA_ "GenMsgCycleTime" BO_ 2364577313 100;
BA_ "SPN" SG_ 2364577313 HVES1HghVoltageBusPosContactStat 8091;
BA_ "SPN" SG_ 2364577313 HVES1HghVoltageBusNegContactStat 8092;
BA_ "SPN" SG_ 2364577313 HVES1HghVoltageBusDiscnnctFrwrng 8093;
BA_ "SPN" SG_ 2364577313 HVES1HghVltgBusPreChrgRelyStat 8094;
BA_ "SPN" SG_ 2364577313 HVES1CenterOfPackContactorState 8095;
BA_ "SPN" SG_ 2364577313 HVES1HiVltgBusActIsolatnTestStat 8096;
BA_ "SPN" SG_ 2364577313 HVES1HiVltgBusPassIsolatnTestSt 8097;
BA_ "SPN" SG_ 2364577313 HVES1HVILStatus 8098;
BA_ "SPN" SG_ 2364577313 HVES1InertiaSwitchStatus 8099;
BA_ "SPN" SG_ 2364577313 HVES1CellBalanceStatus 8101;
BA_ "SPN" SG_ 2364577313 HVES1CellBalancingActive 8102;
BA_ "SPN" SG_ 2364577313 HVES1InternalChargerStatus 8207;
BA_ "SPN" SG_ 2364577313 HVES1HghVoltageBusConnectnStatus 8413;
BA_ "SPN" SG_ 2364577313 HVES1OperationalStatus 8414;
BA_ "GenMsgCycleTime" BO_ 2566900513 250;
BA_ "GenMsgCycleTime" BO_ 2365479471 100;
BA_ "SPN" SG_ 2365479471 NominalLevelFrontAxle 1734;
BA_ "SPN" SG_ 2365479471 NominalLevelRearAxle 1733;
BA_ "SPN" SG_ 2365479471 BelowNominalLevelFrontAxle 1738;
BA_ "SPN" SG_ 2365479471 BelowNominalLevelRearAxle 1754;
BA_ "SPN" SG_ 2365479471 AboveNominalLevelFrontAxle 1737;
BA_ "SPN" SG_ 2365479471 AboveNominalLevelRearAxle 1736;
BA_ "SPN" SG_ 2365479471 LoweringControlModeFrontAxle 1740;
BA_ "SPN" SG_ 2365479471 LoweringControlModeRearAxle 1755;
BA_ "SPN" SG_ 2365479471 LiftingControlModeFrontAxle 1739;
BA_ "SPN" SG_ 2365479471 LiftingControlModeRearAxle 1756;
BA_ "SPN" SG_ 2365479471 KneelingInformation 1742;
BA_ "SPN" SG_ 2365479471 LevelControlMode 1741;
BA_ "SPN" SG_ 2365479471 SecurityDevice 1746;
BA_ "SPN" SG_ 2365479471 VehicleMotionInhibit 1745;
BA_ "SPN" SG_ 2365479471 DoorRelease 1744;
BA_ "SPN" SG_ 2365479471 LiftAxle1Position 1743;
BA_ "SPN" SG_ 2365479471 FrontAxleInBumperRange 1824;
BA_ "SPN" SG_ 2365479471 RearAxleInBumperRange 1823;
BA_ "SPN" SG_ 2365479471 LiftAxle2Position 1822;
BA_ "SPN" SG_ 2365479471 SuspensionRemoteControl1 1826;
BA_ "SPN" SG_ 2365479471 SuspensionRemoteControl2 1825;
BA_ "SPN" SG_ 2365479471 AllowLevelCtrlDuringBrkngStatus 5294;
BA_ "SPN" SG_ 2365479471 SpeedDependantLevelControlStatus 5296;
BA_ "SPN" SG_ 2365479471 SuspensionCtrlRefusalInformation 1827;
BA_ "SPN" SG_ 2365479471 MemoryLevel 5432;
BA_ "SPN" SG_ 2364607265 HvssHghstCllTmprtrMdlNmr 8241;
BA_ "SPN" SG_ 2364607265 HvssHghstCllTmprtrCllNmr 8242;
BA_ "SPN" SG_ 2364607265 HvssLwstCllTmprtrMdlNmr 8243;
BA_ "SPN" SG_ 2364607265 HvssLwstCllTmprtrCllNmr 8244;
BA_ "SPN" SG_ 2364607265 HvessThermalEventDetected 21287;
BA_ "GenMsgCycleTime" BO_ 2565866785 100;
BA_ "SPN" SG_ 2565866785 TransmissionSelectedGear 524;
BA_ "SPN" SG_ 2565866785 TransmissionActualGearRatio 526;
BA_ "SPN" SG_ 2565866785 TransmissionCurrentGear 523;
BA_ "SPN" SG_ 2565866785 TransmissionRequestedRange 162;
BA_ "SPN" SG_ 2565866785 TransmissionCurrentRange 163;
BA_ "GenMsgCycleTime" BO_ 2566719265 1000;
BA_ "SPN" SG_ 2566719265 EngineProtectLampCommand 5077;
BA_ "SPN" SG_ 2566719265 EngineAmberWarningLampCommand 5078;
BA_ "SPN" SG_ 2566719265 EngineRedStopLampCommand 5079;
BA_ "SPN" SG_ 2566719265 OBDMalfunctionIndicatorLampCmd 5080;
BA_ "SPN" SG_ 2566719265 EngineBrakeActiveLampCommand 5081;
BA_ "SPN" SG_ 2566719265 ComPrsionBrkEnblSwIndictrLampCmd 3987;
BA_ "SPN" SG_ 2566719265 EngineOilPressureLowLampCommand 5082;
BA_ "SPN" SG_ 2566719265 EngCoolntTemperatureHighLampCmd 5083;
BA_ "SPN" SG_ 2566719265 EngineCoolantLevelLowLampCommand 5084;
BA_ "SPN" SG_ 2566719265 EngineIdleManagementActvLampCmd 5085;
BA_ "SPN" SG_ 2566719265 EngAirFilterRestrictionLampCmd 5086;
BA_ "SPN" SG_ 2566719265 EngFuelFilterRestrictedLampCmd 5469;
BA_ "SPN" SG_ 2566719265 EngCtrlModule1ReadyForUseLampCmd 6205;
BA_ "SPN" SG_ 2566719265 EngCtrlModule2ReadyForUseLampCmd 6206;
BA_ "SPN" SG_ 2566719265 EngCtrlModule3ReadyForUseLampCmd 6207;
BA_ "SPN" SG_ 2566719265 EngineSpeedHighLampCommand 6709;
BA_ "SPN" SG_ 2566719265 EngineSpeedVeryHighLampCommand 6710;
BA_ "SPN" SG_ 2566719265 VehicleAccltnRateLimitLampCmd 6899;
BA_ "SPN" SG_ 2566719265 EngIdlMangmntPendingEvntLampCmd 9372;
BA_ "SPN" SG_ 2566719265 EngStopStartAutoStopActvLampCmd 9683;
BA_ "SPN" SG_ 2566719265 EngStopStrtAutoStrtFailedLampCmd 9684;
BA_ "SPN" SG_ 2566719265 EngineStopStartEnabledLampCmd 9685;
BA_ "SPN" SG_ 2566719265 EngineOilTemperatureHighLampCmd 13105;
BA_ "SPN" SG_ 2566719265 EngineFuelTemperatureHighLampCmd 13106;
BA_ "SPN" SG_ 2566719265 EngIntercoolerTempHghLampCmd 13107;
BA_ "SPN" SG_ 2566719265 EngineAirShutoffLampCommand 13379;
BA_ "GenMsgCycleTime" BO_ 2364552743 100;
BA_ "SPN" SG_ 2364552743 HVES1DisChrgPowerLmtDTStateChrg 8103;
BA_ "SPN" SG_ 2364552743 HVES1DisChrgPwrLmtDTBattryTemp 8104;
BA_ "SPN" SG_ 2364552743 HVES1DisChrgPwrLmtDTBattDiagCond 8105;
BA_ "SPN" SG_ 2364552743 HVES1DisChrgPwrLmtDTBattCellVltg 8106;
BA_ "SPN" SG_ 2364552743 HVES1DisChrgPowerLmtDTBattryCurr 8107;
BA_ "SPN" SG_ 2364552743 HVES1DisChrgPwrLmtDTUndefndCause 8108;
BA_ "SPN" SG_ 2364552743 HVES1ChrgPowerLimitDTStateChrg 8109;
BA_ "SPN" SG_ 2364552743 HVES1ChrgPwrLmtDTBattryTemp 8110;
BA_ "SPN" SG_ 2364552743 HVES1ChrgPwrLmtDTBattDiagCondtn 8111;
BA_ "SPN" SG_ 2364552743 HVES1ChrgPwrLmtDTBattryCellVltg 8112;
BA_ "SPN" SG_ 2364552743 HVES1ChrgPowerLimitDTBattryCurr 8113;
BA_ "SPN" SG_ 2364552743 HVES1ChrgPwrLmtDTUndefinedCause 8114;
BA_ "GenMsgCycleTime" BO_ 2364606759 100;
BA_ "SPN" SG_ 2364606759 HVES1ThermalMangmntSysSLIInptPwr 8230;
BA_ "SPN" SG_ 2364606759 HVES1ThrmlMngmtSysHiVltgInptPwr 8231;
BA_ "SPN" SG_ 2364606759 HVES1ThrmlMangmntSysCmprssorSpd 8232;
BA_ "SPN" SG_ 2364606759 HVES1ThermalMangmntSysRelHumidty 8233;
BA_ "SPN" SG_ 2364606759 HVES1ThermalMangmntSystemHtrStat 8234;
BA_ "SPN" SG_ 2364606759 HVESSThermalMangmntSysHVILStat 12813;
BA_ "SPN" SG_ 2364606759 HVES1ThermalManagementSystemMode 8235;
BA_ "SPN" SG_ 2364606759 HVESSThermalMangmntSysCoolntLvl 12897;
BA_ "SPN" SG_ 2566540583 TotalTripEnergyConsumed 20876;
BA_ "SPN" SG_ 2566540583 TripDriveEnergyEconomy 20875;
BA_ "SPN" SG_ 2365349415 HVES1StateOfHealth 8121;
BA_ "SPN" SG_ 2365349415 HVES1ContactorOpenUnderLoadCount 8122;
BA_ "SPN" SG_ 2365349415 HVES1TotalEnergyThroughput 8211;
BA_ "SPN" SG_ 2365349415 HVES1TotalAccumulatedCharge 8212;
BA_ "SPN" SG_ 2365349415 HVESSTotalLifetimeEnergyInput 13365;
BA_ "SPN" SG_ 2365349415 HVESSTotalLifetimeEnergyOutput 13366;
BA_ "SPN" SG_ 2566766631 TypeOfPassengerCount 3043;
BA_ "SPN" SG_ 2566766631 PatronCount 3047;
BA_ "SPN" SG_ 2566766631 SilentAlarmStatus 3044;
BA_ "SPN" SG_ 2566766631 VehicleUseStatus 3045;
BA_ "SPN" SG_ 2566766631 TransitRunStatus 3046;
BA_ "SPN" SG_ 2566841895 Seconds 959;
BA_ "SPN" SG_ 2566841895 Minutes 960;
BA_ "SPN" SG_ 2566841895 Hours 961;
BA_ "SPN" SG_ 2566841895 Month 963;
BA_ "SPN" SG_ 2566841895 Day 962;
BA_ "GenSigStartValue" SG_ 2566841895 Year 1985;
BA_ "SPN" SG_ 2566841895 Year 964;
BA_ "SPN" SG_ 2566841895 LocalMinuteOffset 1601;
BA_ "SPN" SG_ 2566841895 LocalHourOffset 1602;
BA_ "SPN" SG_ 2566842151 TotalVehicleHours 246;
BA_ "SPN" SG_ 2566842151 TotalPowerTakeoffHours 248;
BA_ "SPN" SG_ 2566834699 ProtectLamp 987;
BA_ "SPN" SG_ 2566834699 AmberWarningLamp 624;
BA_ "SPN" SG_ 2566834699 RedStopLamp 623;
BA_ "SPN" SG_ 2566834699 MalfunctionIndicatorLamp 1213;
BA_ "SPN" SG_ 2566834699 FlashProtectLamp 3041;
BA_ "SPN" SG_ 2566834699 FlashAmberWarningLamp 3040;
BA_ "SPN" SG_ 2566834699 FlashRedStopLamp 3039;
BA_ "SPN" SG_ 2566834699 FlashMalfunctionIndicatorLamp 3038;
BA_ "SPN" SG_ 2566834699 SuspectParameterNumber 1214;
BA_ "SPN" SG_ 2566834699 FailureModeIdentifier 1215;
BA_ "SPN" SG_ 2566834699 OccurrenceCount 1216;
BA_ "SPN" SG_ 2566834699 SPNConversionMethod 1706;
BA_ "SPN" SG_ 2566834699 SuspectParameterNumber2 1214;
BA_ "SPN" SG_ 2566834699 FailureModeIdentifier2 1215;
BA_ "SPN" SG_ 2566834699 OccurrenceCount2 1216;
BA_ "SPN" SG_ 2566834699 SPNConversionMethod2 1706;
BA_ "SPN" SG_ 2566834699 SuspectParameterNumber3 1214;
BA_ "SPN" SG_ 2566834699 FailureModeIdentifier3 1215;
BA_ "SPN" SG_ 2566834699 OccurrenceCount3 1216;
BA_ "SPN" SG_ 2566834699 SPNConversionMethod3 1706;
BA_ "SPN" SG_ 2566834699 SuspectParameterNumber4 1214;
BA_ "SPN" SG_ 2566834699 FailureModeIdentifier4 1215;
BA_ "SPN" SG_ 2566834699 OccurrenceCount4 1216;
BA_ "SPN" SG_ 2566834699 SPNConversionMethod4 1706;
BA_ "SPN" SG_ 2566834699 SuspectParameterNumber5 1214;
BA_ "SPN" SG_ 2566834699 FailureModeIdentifier5 1215;
BA_ "SPN" SG_ 2566834699 OccurrenceCount5 1216;
BA_ "SPN" SG_ 2566834699 SPNConversionMethod5 1706;
BA_ "SPN" SG_ 2566834699 SuspectParameterNumber6 1214;
BA_ "SPN" SG_ 2566834699 FailureModeIdentifier6 1215;
BA_ "SPN" SG_ 2566834699 OccurrenceCount6 1216;
BA_ "SPN" SG_ 2566834699 SPNConversionMethod6 1706;
BA_ "SPN" SG_ 2566834699 SuspectParameterNumber7 1214;
BA_ "SPN" SG_ 2566834699 FailureModeIdentifier7 1215;
BA_ "SPN" SG_ 2566834699 OccurrenceCount7 1216;
BA_ "SPN" SG_ 2566834699 SPNConversionMethod7 1706;
BA_ "SPN" SG_ 2566834699 SuspectParameterNumber8 1214;
BA_ "SPN" SG_ 2566834699 FailureModeIdentifier8 1215;
BA_ "SPN" SG_ 2566834699 OccurrenceCount8 1216;
BA_ "SPN" SG_ 2566834699 SPNConversionMethod8 1706;
BA_ "SPN" SG_ 2566834699 SuspectParameterNumber9 1214;
BA_ "SPN" SG_ 2566834699 FailureModeIdentifier9 1215;
BA_ "SPN" SG_ 2566834699 OccurrenceCount9 1216;
BA_ "SPN" SG_ 2566834699 SPNConversionMethod9 1706;
BA_ "SPN" SG_ 2566834699 SuspectParameterNumber10 1214;
BA_ "SPN" SG_ 2566834699 FailureModeIdentifier10 1215;
BA_ "SPN" SG_ 2566834699 OccurrenceCount10 1216;
BA_ "SPN" SG_ 2566834699 SPNConversionMethod10 1706;
BA_ "SPN" SG_ 2566834699 SuspectParameterNumber11 1214;
BA_ "SPN" SG_ 2566834699 FailureModeIdentifier11 1215;
BA_ "SPN" SG_ 2566834699 OccurrenceCount11 1216;
BA_ "SPN" SG_ 2566834699 SPNConversionMethod11 1706;
BA_ "SPN" SG_ 2566834699 SuspectParameterNumber12 1214;
BA_ "SPN" SG_ 2566834699 FailureModeIdentifier12 1215;
BA_ "SPN" SG_ 2566834699 OccurrenceCount12 1216;
BA_ "SPN" SG_ 2566834699 SPNConversionMethod12 1706;
BA_ "SPN" SG_ 2566834735 ProtectLamp 987;
BA_ "SPN" SG_ 2566834735 AmberWarningLamp 624;
BA_ "SPN" SG_ 2566834735 RedStopLamp 623;
BA_ "SPN" SG_ 2566834735 MalfunctionIndicatorLamp 1213;
BA_ "SPN" SG_ 2566834735 FlashProtectLamp 3041;
BA_ "SPN" SG_ 2566834735 FlashAmberWarningLamp 3040;
BA_ "SPN" SG_ 2566834735 FlashRedStopLamp 3039;
BA_ "SPN" SG_ 2566834735 FlashMalfunctionIndicatorLamp 3038;
BA_ "SPN" SG_ 2566834735 SuspectParameterNumber 1214;
BA_ "SPN" SG_ 2566834735 FailureModeIdentifier 1215;
BA_ "SPN" SG_ 2566834735 OccurrenceCount 1216;
BA_ "SPN" SG_ 2566834735 SPNConversionMethod 1706;
BA_ "SPN" SG_ 2566834735 SuspectParameterNumber2 1214;
BA_ "SPN" SG_ 2566834735 FailureModeIdentifier2 1215;
BA_ "SPN" SG_ 2566834735 OccurrenceCount2 1216;
BA_ "SPN" SG_ 2566834735 SPNConversionMethod2 1706;
BA_ "SPN" SG_ 2566834735 SuspectParameterNumber3 1214;
BA_ "SPN" SG_ 2566834735 FailureModeIdentifier3 1215;
BA_ "SPN" SG_ 2566834735 OccurrenceCount3 1216;
BA_ "SPN" SG_ 2566834735 SPNConversionMethod3 1706;
BA_ "SPN" SG_ 2566834735 SuspectParameterNumber4 1214;
BA_ "SPN" SG_ 2566834735 FailureModeIdentifier4 1215;
BA_ "SPN" SG_ 2566834735 OccurrenceCount4 1216;
BA_ "SPN" SG_ 2566834735 SPNConversionMethod4 1706;
BA_ "SPN" SG_ 2566834735 SuspectParameterNumber5 1214;
BA_ "SPN" SG_ 2566834735 FailureModeIdentifier5 1215;
BA_ "SPN" SG_ 2566834735 OccurrenceCount5 1216;
BA_ "SPN" SG_ 2566834735 SPNConversionMethod5 1706;
BA_ "SPN" SG_ 2566834735 SuspectParameterNumber6 1214;
BA_ "SPN" SG_ 2566834735 FailureModeIdentifier6 1215;
BA_ "SPN" SG_ 2566834735 OccurrenceCount6 1216;
BA_ "SPN" SG_ 2566834735 SPNConversionMethod6 1706;
BA_ "SPN" SG_ 2566834735 SuspectParameterNumber7 1214;
BA_ "SPN" SG_ 2566834735 FailureModeIdentifier7 1215;
BA_ "SPN" SG_ 2566834735 OccurrenceCount7 1216;
BA_ "SPN" SG_ 2566834735 SPNConversionMethod7 1706;
BA_ "SPN" SG_ 2566834735 SuspectParameterNumber8 1214;
BA_ "SPN" SG_ 2566834735 FailureModeIdentifier8 1215;
BA_ "SPN" SG_ 2566834735 OccurrenceCount8 1216;
BA_ "SPN" SG_ 2566834735 SPNConversionMethod8 1706;
BA_ "SPN" SG_ 2566834735 SuspectParameterNumber9 1214;
BA_ "SPN" SG_ 2566834735 FailureModeIdentifier9 1215;
BA_ "SPN" SG_ 2566834735 OccurrenceCount9 1216;
BA_ "SPN" SG_ 2566834735 SPNConversionMethod9 1706;
BA_ "SPN" SG_ 2566834735 SuspectParameterNumber10 1214;
BA_ "SPN" SG_ 2566834735 FailureModeIdentifier10 1215;
BA_ "SPN" SG_ 2566834735 OccurrenceCount10 1216;
BA_ "SPN" SG_ 2566834735 SPNConversionMethod10 1706;
BA_ "SPN" SG_ 2566834735 SuspectParameterNumber11 1214;
BA_ "SPN" SG_ 2566834735 FailureModeIdentifier11 1215;
BA_ "SPN" SG_ 2566834735 OccurrenceCount11 1216;
BA_ "SPN" SG_ 2566834735 SPNConversionMethod11 1706;
BA_ "SPN" SG_ 2566834735 SuspectParameterNumber12 1214;
BA_ "SPN" SG_ 2566834735 FailureModeIdentifier12 1215;
BA_ "SPN" SG_ 2566834735 OccurrenceCount12 1216;
BA_ "SPN" SG_ 2566834735 SPNConversionMethod12 1706;
BA_ "SPN" SG_ 2566834778 ProtectLamp 987;
BA_ "SPN" SG_ 2566834778 AmberWarningLamp 624;
BA_ "SPN" SG_ 2566834778 RedStopLamp 623;
BA_ "SPN" SG_ 2566834778 MalfunctionIndicatorLamp 1213;
BA_ "SPN" SG_ 2566834778 FlashProtectLamp 3041;
BA_ "SPN" SG_ 2566834778 FlashAmberWarningLamp 3040;
BA_ "SPN" SG_ 2566834778 FlashRedStopLamp 3039;
BA_ "SPN" SG_ 2566834778 FlashMalfunctionIndicatorLamp 3038;
BA_ "SPN" SG_ 2566834778 SuspectParameterNumber 1214;
BA_ "SPN" SG_ 2566834778 FailureModeIdentifier 1215;
BA_ "SPN" SG_ 2566834778 OccurrenceCount 1216;
BA_ "SPN" SG_ 2566834778 SPNConversionMethod 1706;
BA_ "SPN" SG_ 2566834778 SuspectParameterNumber2 1214;
BA_ "SPN" SG_ 2566834778 FailureModeIdentifier2 1215;
BA_ "SPN" SG_ 2566834778 OccurrenceCount2 1216;
BA_ "SPN" SG_ 2566834778 SPNConversionMethod2 1706;
BA_ "SPN" SG_ 2566834778 SuspectParameterNumber3 1214;
BA_ "SPN" SG_ 2566834778 FailureModeIdentifier3 1215;
BA_ "SPN" SG_ 2566834778 OccurrenceCount3 1216;
BA_ "SPN" SG_ 2566834778 SPNConversionMethod3 1706;
BA_ "SPN" SG_ 2566834778 SuspectParameterNumber4 1214;
BA_ "SPN" SG_ 2566834778 FailureModeIdentifier4 1215;
BA_ "SPN" SG_ 2566834778 OccurrenceCount4 1216;
BA_ "SPN" SG_ 2566834778 SPNConversionMethod4 1706;
BA_ "SPN" SG_ 2566834778 SuspectParameterNumber5 1214;
BA_ "SPN" SG_ 2566834778 FailureModeIdentifier5 1215;
BA_ "SPN" SG_ 2566834778 OccurrenceCount5 1216;
BA_ "SPN" SG_ 2566834778 SPNConversionMethod5 1706;
BA_ "SPN" SG_ 2566834778 SuspectParameterNumber6 1214;
BA_ "SPN" SG_ 2566834778 FailureModeIdentifier6 1215;
BA_ "SPN" SG_ 2566834778 OccurrenceCount6 1216;
BA_ "SPN" SG_ 2566834778 SPNConversionMethod6 1706;
BA_ "SPN" SG_ 2566834778 SuspectParameterNumber7 1214;
BA_ "SPN" SG_ 2566834778 FailureModeIdentifier7 1215;
BA_ "SPN" SG_ 2566834778 OccurrenceCount7 1216;
BA_ "SPN" SG_ 2566834778 SPNConversionMethod7 1706;
BA_ "SPN" SG_ 2566834778 SuspectParameterNumber8 1214;
BA_ "SPN" SG_ 2566834778 FailureModeIdentifier8 1215;
BA_ "SPN" SG_ 2566834778 OccurrenceCount8 1216;
BA_ "SPN" SG_ 2566834778 SPNConversionMethod8 1706;
BA_ "SPN" SG_ 2566834778 SuspectParameterNumber9 1214;
BA_ "SPN" SG_ 2566834778 FailureModeIdentifier9 1215;
BA_ "SPN" SG_ 2566834778 OccurrenceCount9 1216;
BA_ "SPN" SG_ 2566834778 SPNConversionMethod9 1706;
BA_ "SPN" SG_ 2566834778 SuspectParameterNumber10 1214;
BA_ "SPN" SG_ 2566834778 FailureModeIdentifier10 1215;
BA_ "SPN" SG_ 2566834778 OccurrenceCount10 1216;
BA_ "SPN" SG_ 2566834778 SPNConversionMethod10 1706;
BA_ "SPN" SG_ 2566834778 SuspectParameterNumber11 1214;
BA_ "SPN" SG_ 2566834778 FailureModeIdentifier11 1215;
BA_ "SPN" SG_ 2566834778 OccurrenceCount11 1216;
BA_ "SPN" SG_ 2566834778 SPNConversionMethod11 1706;
BA_ "SPN" SG_ 2566834778 SuspectParameterNumber12 1214;
BA_ "SPN" SG_ 2566834778 FailureModeIdentifier12 1215;
BA_ "SPN" SG_ 2566834778 OccurrenceCount12 1216;
BA_ "SPN" SG_ 2566834778 SPNConversionMethod12 1706;
VAL_ 2365524759 LightCheckSwitch 0 "Off" 1 "On" 2 "Error" 3 "Not avaliable" ;
VAL_ 2365524759 D1DemistSwitch 0 "Off" 1 "On" 2 "Error" 3 "Not avaliable" ;
VAL_ 2365524759 SchoolFlashSwitch 0 "Off" 1 "On" 2 "Error" 3 "Not avaliable" ;
VAL_ 2365524759 BellCancelSwitch 0 "Off" 1 "On" 2 "Error" 3 "Not avaliable" ;
VAL_ 2365524759 MapLightSwitch 0 "Off" 1 "On" 2 "Error" 3 "Not avaliable" ;
VAL_ 2365524759 CabLightSwitch 0 "Off" 1 "On" 2 "Error" 3 "Not avaliable" ;
VAL_ 2365524759 D1Switch 0 "Off" 1 "On" 2 "Error" 3 "Not avaliable" ;
VAL_ 2365524759 D2Switch 0 "Off" 1 "On" 2 "Error" 3 "Not avaliable" ;
VAL_ 2365524759 Switch_2S_10 0 "Off" 1 "On" 2 "Error" 3 "Not avaliable" ;
VAL_ 2365524759 Switch_2S_11 0 "Off" 1 "On" 2 "Error" 3 "Not avaliable" ;
VAL_ 2365524759 Switch_2S_12 0 "Off" 1 "On" 2 "Error" 3 "Not avaliable" ;
VAL_ 2365524759 Switch_2S_13 0 "Off" 1 "On" 2 "Error" 3 "Not avaliable" ;
VAL_ 2365524759 Switch_2S_14 0 "Off" 1 "On" 2 "Error" 3 "Not avaliable" ;
VAL_ 2365524759 Switch_2S_15 0 "Off" 1 "On" 2 "Error" 3 "Not avaliable" ;
VAL_ 2365524759 Switch_2S_16 0 "Off" 1 "On" 2 "Error" 3 "Not avaliable" ;
VAL_ 2365524759 Switch_2S_17 0 "Off" 1 "On" 2 "Error" 3 "Not avaliable" ;
VAL_ 2365524759 ECASSwitch 0 "Off" 1 "Lower" 2 "Raise" 7 "Not avaliable" 6 "Error" ;
VAL_ 2365524759 DemistFanSwitch 0 "Off" 1 "Low" 2 "High" 7 "Not avaliable" 6 "Error" ;
VAL_ 2365524759 DriverFanSwitch 0 "Off" 1 "Low" 2 "High" 7 "Not avaliable" 6 "Error" ;
VAL_ 2365524759 SaloonLightSwitch 0 "Off" 1 "Low" 2 "High" 7 "Not avaliable" 6 "Error" ;
VAL_ 2365524759 RTRH_Switch 0 "Off" 1 "Kneel" 2 "RTRH" 7 "Not avaliable" 6 "Error" ;
VAL_ 2365524759 DemistTempSwitch 0 "Off" 1 "Low" 2 "High" 7 "Not avaliable" 6 "Error" ;
VAL_ 2365524759 Switch_3S_7 0 "Off" 1 "State 1" 2 "State 2" 7 "Not avaliable" 6 "Error" ;
VAL_ 2365524759 Switch_3S_8 0 "Off" 1 "State 1" 2 "State 2" 7 "Not avaliable" 6 "Error" ;
VAL_ 2365524759 Switch_3S_9 0 "Off" 1 "State 1" 2 "State 2" 7 "Not avaliable" 6 "Error" ;
VAL_ 2365524759 Switch_3S_10 0 "Off" 1 "State 1" 2 "State 2" 7 "Not avaliable" 6 "Error" ;
VAL_ 2365524759 Switch_2S_9 0 "Off" 1 "On" 2 "Error" 3 "Not avaliable" ;
VAL_ 2365524513 BrakeFault 0 "Off" 1 "Colour A" 2 "Colour B" 3 "Not avaliable" ;
VAL_ 2365524513 StopLight 0 "Off" 1 "Colour A" 2 "Colour B" 3 "Not avaliable" ;
VAL_ 2365524513 SchoolLight 0 "Off" 1 "Colour A" 2 "Colour B" 3 "Not avaliable" ;
VAL_ 2365524513 DoorOverrideActive 0 "Off" 1 "Colour A" 2 "Colour B" 3 "Not avaliable" ;
VAL_ 2365524513 NextStop 0 "Off" 1 "Colour A" 2 "Colour B" 3 "Not avaliable" ;
VAL_ 2365524513 DebugControl 0 "Default screen" 1 "Debug screen" 2 "Error" 3 "Not avaliable" ;
VAL_ 2365524513 RampNextStop 0 "Off" 1 "Colour A" 2 "Colour B" 3 "Not avaliable" ;
VAL_ 2365524513 Door1Entrapment 0 "No Doors" 1 "Door 1" 2 "Door 2" 3 "Not avaliable" ;
VAL_ 2365524513 DoorFault 0 "No Doors" 1 "Door 1" 2 "Door 2" 3 "Not avaliable" ;
VAL_ 2365524513 Door2Entrapment 0 "No Doors" 1 "Door 1" 2 "Door 2" 3 "Not avaliable" ;
VAL_ 2365524513 ExitHammer 0 "Off" 1 "Colour A" 2 "Colour B" 3 "Not avaliable" ;
VAL_ 2365524513 BrakeWear 0 "Off" 1 "Colour A" 2 "Colour B" 3 "Not avaliable" ;
VAL_ 2365524513 DriverGate 0 "Off" 1 "Colour A" 2 "Colour B" 3 "Not avaliable" ;
VAL_ 2365524513 ChargerDoor 0 "Off" 1 "Colour A" 2 "Colour B" 3 "Not avaliable" ;
VAL_ 2365524513 EngineDoor 0 "Off" 1 "Colour A" 2 "Colour B" 3 "Not avaliable" ;
VAL_ 2365524513 SystemStart 0 "Off" 1 "Colour A" 2 "Colour B" 3 "Not avaliable" ;
VAL_ 2566759713 LockStatusOfDoor1 0 "Unlocked" 1 "Locked" 2 "Error" 3 "Not available" ;
VAL_ 2566759713 OpenStatusOfDoor1 0 "Door closed" 1 "Door opened" 2 "Error" 3 "Not available" ;
VAL_ 2566759713 EnableStatusOfDoor1 0 "Door disabled" 1 "Door enabled" 2 "Error" 3 "Not available" ;
VAL_ 2566759713 LockStatusOfDoor2 0 "Unlocked" 1 "Locked" 2 "Error" 3 "Not available" ;
VAL_ 2566759713 OpenStatusOfDoor2 0 "Door closed" 1 "Door opened" 2 "Error" 3 "Not available" ;
VAL_ 2566759713 EnableStatusOfDoor2 0 "Door disabled" 1 "Door enabled" 2 "Error" 3 "Not available" ;
VAL_ 2566759713 LockStatusOfDoor3 0 "Unlocked" 1 "Locked" 2 "Error" 3 "Not available" ;
VAL_ 2566759713 OpenStatusOfDoor3 0 "Door closed" 1 "Door opened" 2 "Error" 3 "Not available" ;
VAL_ 2566759713 EnableStatusOfDoor3 0 "Door disabled" 1 "Door enabled" 2 "Error" 3 "Not available" ;
VAL_ 2566759713 LockStatusOfDoor4 0 "Unlocked" 1 "Locked" 2 "Error" 3 "Not available" ;
VAL_ 2566759713 OpenStatusOfDoor4 0 "Door closed" 1 "Door opened" 2 "Error" 3 "Not available" ;
VAL_ 2566759713 EnableStatusOfDoor4 0 "Door disabled" 1 "Door enabled" 2 "Error" 3 "Not available" ;
VAL_ 2566759713 LockStatusOfDoor5 0 "Unlocked" 1 "Locked" 2 "Error" 3 "Not available" ;
VAL_ 2566759713 OpenStatusOfDoor5 0 "Door closed" 1 "Door opened" 2 "Error" 3 "Not available" ;
VAL_ 2566759713 EnableStatusOfDoor5 0 "Door disabled" 1 "Door enabled" 2 "Error" 3 "Not available" ;
VAL_ 2566759713 LockStatusOfDoor6 0 "Unlocked" 1 "Locked" 2 "Error" 3 "Not available" ;
VAL_ 2566759713 OpenStatusOfDoor6 0 "Door closed" 1 "Door opened" 2 "Error" 3 "Not available" ;
VAL_ 2566759713 EnableStatusOfDoor6 0 "Door disabled" 1 "Door enabled" 2 "Error" 3 "Not available" ;
VAL_ 2566759713 LockStatusOfDoor7 0 "Unlocked" 1 "Locked" 2 "Error" 3 "Not available" ;
VAL_ 2566759713 OpenStatusOfDoor7 0 "Door closed" 1 "Door opened" 2 "Error" 3 "Not available" ;
VAL_ 2566759713 EnableStatusOfDoor7 0 "Door disabled" 1 "Door enabled" 2 "Error" 3 "Not available" ;
VAL_ 2566759713 LockStatusOfDoor8 0 "Unlocked" 1 "Locked" 2 "Error" 3 "Not available" ;
VAL_ 2566759713 OpenStatusOfDoor8 0 "Door closed" 1 "Door opened" 2 "Error" 3 "Not available" ;
VAL_ 2566759713 EnableStatusOfDoor8 0 "Door disabled" 1 "Door enabled" 2 "Error" 3 "Not available" ;
VAL_ 2566759713 LockStatusOfDoor9 0 "Unlocked" 1 "Locked" 2 "Error" 3 "Not available" ;
VAL_ 2566759713 OpenStatusOfDoor9 0 "Door closed" 1 "Door opened" 2 "Error" 3 "Not available" ;
VAL_ 2566759713 EnableStatusOfDoor9 0 "Door disabled" 1 "Door enabled" 2 "Error" 3 "Not available" ;
VAL_ 2566759713 LockStatusOfDoor10 0 "Unlocked" 1 "Locked" 2 "Error" 3 "Not available" ;
VAL_ 2566759713 OpenStatusOfDoor10 0 "Door closed" 1 "Door opened" 2 "Error" 3 "Not available" ;
VAL_ 2566759713 EnableStatusOfDoor10 0 "Door disabled" 1 "Door enabled" 2 "Error" 3 "Not available" ;
VAL_ 2566802977 PositionOfDoors 0 "At least 1 door is open" 1 "Closing last door" 2 "All doors close" 3 "Not defined" 14 "Error" 15 "Not available" ;
VAL_ 2566802977 RampWheelChairLiftPosition 0 "Inside bus" 1 "Outside bus" 2 "Error" 3 "Not available" ;
VAL_ 2566802977 Status2OfDoors 0 "all bus doors are disabled" 1 "at least 1 bus door enabled" 2 "error" 3 "not available" ;
VAL_ 2350644759 HVES1HighVoltageBusConnectCmd 0 "Open Contactor" 1 "Close Contactor" 2 "Emergency contactor closure request" 3 "Don't care/Take no action" ;
VAL_ 2350644759 HVES1PowerDownCommand 0 "Power-down not requested" 1 "Execute normal power-down" 2 "Execute emergency power-down" 3 "Don't care/Take no action" ;
VAL_ 2350644759 HVES1HghVltgBusActIsolatnTestCmd 0 "Active Isolation Test not requested" 1 "Active Isolation Test request" 2 "Inhibit Active Isolation Test" 3 "Don't care/Take no action" ;
VAL_ 2350644759 HVES1HiVltgBusPassIsolatnTestCmd 0 "Passive Isolation Test not requested" 1 "Passive Isolation Test request" 2 "Inhibit Passive Isolation Test" 3 "Don't care/Take no action" ;
VAL_ 2350644759 HVES1CellBalancingCommand 0 "Cell Balancing not requested" 1 "Cell Balancing requested" 2 "Reserved" 3 "Don't care/Take no action" ;
VAL_ 2350644759 HVES1EnableInternalChrgrCommand 0 "Disable charging" 1 "Enable charging" 2 "Reserved" 3 "Don't care/Take no action" ;
VAL_ 2350644759 HVES1OperationConsent 0 "Consent revoked" 1 "Consent given" 2 "Error" 3 "Don't care/Take no action" ;
VAL_ 2350644759 HVES1HiVltgBusHiSdeResistCnnctRq 0 "Connection not Requested" 1 "Connection Requested" 2 "Reserved" 3 "Don't care/take no action" ;
VAL_ 2350644759 HVES1HiVltgBusLoSdeResistCnnctRq 0 "Connection not Requested" 1 "Connection Requested" 2 "Reserved" 3 "Don't care/take no action" ;
VAL_ 2350644759 HVESSThermalMangmntMaintenRq 0 "HVESS Thermal Management Maintenance Mode is not requested" 1 "HVESS Thermal Management Maintenance Mode is requested" 2 "Reserved" 3 "Don't care/take no action" ;
VAL_ 2565865739 ASREngineControlActive 0 "ASR engine control passive but installed" 1 "ASR engine control active" 2 "Reserved" 3 "Not available" ;
VAL_ 2565865739 ASRBrakeControlActive 0 "ASR brake control passive but installed" 1 "ASR brake control active" 2 "Reserved" 3 "Not available" ;
VAL_ 2565865739 AntiLockBrakingActive 0 "ABS passive but installed" 1 "ABS active" 2 "Reserved" 3 "Not available" ;
VAL_ 2565865739 EBSBrakeSwitch 0 "Brake pedal is not being pressed" 1 "Brake pedal is being pressed" 2 "Error" 3 "Not available" ;
VAL_ 2565865739 ABSOffRoadSwitch 0 "ABS off-road switch passive" 1 "ABS off-road switch active" 2 "Error" 3 "Not available" ;
VAL_ 2565865739 ASROffRoadSwitch 0 "ASR off-road switch passive" 1 "ASR off-road switch active" 2 "Error" 3 "Not available" ;
VAL_ 2565865739 ASRHillHolderSwitch 0 "ASR 'hill holder' switch passive" 1 "ASR 'hill holder' switch active" 2 "Error" 3 "Not available" ;
VAL_ 2565865739 TractionControlOverrideSwitch 0 "Off" 1 "On" 2 "Error" 3 "Not available or not installed" ;
VAL_ 2565865739 AcceleratorInterlockSwitch 0 "Off" 1 "On" 2 "Error" 3 "Not available" ;
VAL_ 2565865739 EngineDerateSwitch 0 "Off" 1 "On" 2 "Error" 3 "Not available" ;
VAL_ 2565865739 EngineAuxiliaryShutdownSwitch 0 "Off" 1 "On" 2 "Error" 3 "Not available" ;
VAL_ 2565865739 RemoteAcceleratorEnableSwitch 0 "Off" 1 "On" 2 "Error" 3 "Not available" ;
VAL_ 2565865739 ABSFullyOperational 0 "Not Fully Operational" 1 "Fully Operational" 2 "Reserved" 3 "Not available" ;
VAL_ 2565865739 EBSRedWarningSignal 0 "Off" 1 "On" 2 "Reserved" 3 "Take no action" ;
VAL_ 2565865739 ABSEBSAmberWarningSignal 0 "Off" 1 "On" 2 "Reserved" 3 "Take no action" ;
VAL_ 2565865739 ATCASRInformationSignal 0 "Off" 1 "On" 2 "Reserved" 3 "Take no action" ;
VAL_ 2565865739 RailroadModeSwitch 0 "Railroad mode switch passive" 1 "Railroad mode switch active" 2 "Error" 3 "Not available" ;
VAL_ 2565865739 HaltBrakeSwitch 0 "Halt brake switch passive" 1 "Halt brake switch active" 2 "Error" 3 "Not available" ;
VAL_ 2565865739 TrailerABSStatus 0 "Information Available Not Active" 1 "Active" 2 "Reserved" 3 "Information Not Available" ;
VAL_ 2565865739 TractorMntdTrailerABSWarningSig 0 "Off" 1 "On" 2 "Reserved" 3 "Take no action" ;
VAL_ 2364576033 HVES1CellVoltageDiffStatus 0 "Cell-to-cell voltage differential is within acceptable limits" 1 "Cell-to-cell voltage differential exceeds acceptable limits but can be corrected via auto-balancing" 2 "Cell-to-cell voltage differential exceeds acceptable limits to a point where external maintenance balancing is required to restore battery performance" 3 "Cell-to-cell voltage differential exceeds acceptable limits to a point where external maintenance balancing cannot restore battery performance" 4 "Cell-to-cell voltage differential exceeds acceptable limits" 5 "Reserved" 14 "Error" 15 "Not Available" ;
VAL_ 2566545953 TractorHazardLights 0 "De-activated" 1 "Activated" 2 "Fault Detected" 3 "Not Available" ;
VAL_ 2365219607 LightingData2RequestCommand 0 "Response not requested" 1 "Response requested" 2 "Reserved" 3 "Don't Care" ;
VAL_ 2365219607 TractorHazardLightsCommand 0 "De-activate" 1 "Activate" 2 "Reserved" 3 "Don't Care" ;
VAL_ 2499547671 CabDoorsLockActuationCommand 0 "Unlock left front cab door latch" 1 "Unlock right front cab door latch" 2 "Unlock left rear cab door latch" 3 "Unlock right rear cab door latch" 4 "Unlock all cab door latches" 5 "Lock all cab door latches" 6 "Reserved" 7 "Take no action" ;
VAL_ 2499547671 RemoteCabDoorLockRequest 0 "Request unlock left front cab door latch" 1 "Request unlock right front cab door latch" 2 "Request unlock left rear cab door latch" 3 "Request unlock right rear cab door latch" 4 "Request unlock all cab door latches" 5 "Request lock all cab door latches" 6 "Reserved" 7 "Take no action" ;
VAL_ 2499547671 LeftFrontWindowPositionCommand 0 "Window move up" 1 "Window move down" 2 "Window auto up" 3 "Window auto down" 4 "Reserved" 7 "Take no action" ;
VAL_ 2499547671 RightFrontWindowPositionCommand 0 "Window move up" 1 "Window move down" 2 "Window auto up" 3 "Window auto down" 4 "Reserved" 7 "Take no action" ;
VAL_ 2499547671 MirrorFoldingSwitch 0 "No Request" 1 "Request to toggle mirror position (fold/unfold)" 2 "Reserved" 3 "Take no action" ;
VAL_ 2499547671 LeftRearWindowPositionCommand 0 "Window move up" 1 "Window move down" 2 "Window auto up" 3 "Window auto down" 4 "Reserved" 7 "Take no action" ;
VAL_ 2499547671 RightRearWindowPositionCommand 0 "Window move up" 1 "Window move down" 2 "Window auto up" 3 "Window auto down" 4 "Reserved" 7 "Take no action" ;
VAL_ 2499547671 MirrorAutoPanningEnable 0 "Disable panning" 1 "Enable panning" 2 "Reserved" 3 "Not available/Take no action" ;
VAL_ 2499547671 MirrorLeft1HorizontalCommand 0 "Move left" 1 "Move right" 2 "Reset (Move to predefined position)" 3 "Take no action" ;
VAL_ 2499547671 MirrorLeft1VerticalCommand 0 "Move up" 1 "Move down" 2 "Reset (Move to predefined position)" 3 "Take no action" ;
VAL_ 2499547671 MirrorRight1HorizontalCommand 0 "Move left" 1 "Move right" 2 "Reset (Move to predefined position)" 3 "Take no action" ;
VAL_ 2499547671 MirrorRight1VerticalCommand 0 "Move up" 1 "Move down" 2 "Reset (Move to predefined position)" 3 "Take no action" ;
VAL_ 2499547671 MirrorLeft2HorizontalCommand 0 "Move left" 1 "Move right" 2 "Reset (Move to predefined position)" 3 "Take no action" ;
VAL_ 2499547671 MirrorLeft2VerticalCommand 0 "Move up" 1 "Move down" 2 "Reset (Move to predefined position)" 3 "Take no action" ;
VAL_ 2499547671 MirrorRight2HorizontalCommand 0 "Move left" 1 "Move right" 2 "Reset (Move to predefined position)" 3 "Take no action" ;
VAL_ 2499547671 MirrorRight2VerticalCommand 0 "Move up" 1 "Move down" 2 "Reset (Move to predefined position)" 3 "Take no action" ;
VAL_ 2499547671 MirrorLeft1HeatCommand 0 "Mirror heat off" 1 "Mirror heat on" 2 "Reserved" 3 "Take no action" ;
VAL_ 2499547671 MirrorRight1HeatCommand 0 "Mirror heat off" 1 "Mirror heat on" 2 "Reserved" 3 "Take no action" ;
VAL_ 2499547671 MirrorLeft2HeatCommand 0 "Mirror heat off" 1 "Mirror heat on" 2 "Reserved" 3 "Take no action" ;
VAL_ 2499547671 MirrorRight2HeatCommand 0 "Mirror heat off" 1 "Mirror heat on" 2 "Reserved" 3 "Take no action" ;
VAL_ 2566771745 TransferCaseSelectorSwitch 0 "2 wheel high (Normal or 'On Highway' Range)" 1 "4 wheel high (Normal or 'On Highway' Range)" 2 "Neutral" 3 "2 wheel low (or 'Off Highway' Range)" 4 "4 wheel low (or 'Off Highway' Range)" 5 "Reserved for SAE assignment" 6 "Error indicator" 7 "Not available" ;
VAL_ 2566771745 AfttreatmentSCRDosingModeCommand 0 "Standard SCR Dosing Mode" 1 "Reduced SCR Dosing Mode" 2 "Reserved" 6 "Reserved for status error value" 7 "Don't care/Take no Action" ;
VAL_ 2566771745 MomentaryOperatorKeySwitch 0 "Button is not depressed by the operator" 1 "Button is depressed by the operator" 2 "Error" 3 "Not Available" ;
VAL_ 2566771745 FifthWheelReleaseControl 0 "Coupler Locked" 1 "Coupler Unlocked" 2 "Error" 3 "Not Available" ;
VAL_ 2566771745 FifthWhlReleaseCtrlSecurityLckt 0 "Fifth wheel release Disabled" 1 "Fifth wheel release Enabled" 2 "Error" 3 "Not Available" ;
VAL_ 2566771745 VehicleTrailerStatus 0 "Trailer is not detected" 1 "Trailer is detected" 2 "Error" 3 "Not available" ;
VAL_ 2566771745 OperatorKeyDetected 0 "No key detected" 1 "Key is detected" 2 "Error" 3 "Not Available" ;
VAL_ 2566771745 TransmissionOilLevelRequest 0 "No transmission oil level reading desired" 1 "Transmission oil level reading desired" 2 "Reserved" 3 "Don't care / take no action" ;
VAL_ 2566771745 OperatorKeySwitchAccessoryPower 0 "Accessory power state is not active" 1 "Accessory power state active" 2 "Error" 3 "Not Available" ;
VAL_ 2566771745 OperatorKeySwitchIgnitionPower 0 "Ignition state is not active" 1 "Ignition state is active" 2 "Error" 3 "Not Available" ;
VAL_ 2566771745 OperatorKeySwitchStart 0 "Start state is not active" 1 "Start state is active" 2 "Error" 3 "Not Available" ;
VAL_ 2566771745 OprtrKeySwitchDelayedBattryOff 0 "Delayed battery off state not active" 1 "Battery power will be removed after delay" 2 "Error" 3 "Not Available" ;
VAL_ 2566771745 HornSwitch 0 "Horn switch is off" 1 "Horn switch is on" 2 "Error" 3 "Not Available" ;
VAL_ 2566771745 EngineAirShutoffTestSwitch 0 "Off" 1 "On" 2 "Error" 3 "Not available" ;
VAL_ 2566771745 EngineAirShutoffManualSwitch 0 "Off" 1 "On" 2 "Error" 3 "Not available" ;
VAL_ 2566771745 OperatorKeySwitchService 0 "Service state is not active" 1 "Service state is active" 2 "Error" 3 "Not Available" ;
VAL_ 2566771745 OperatorKeySwitchOff 0 "Non-Off State" 1 "Off State" 2 "Error" 3 "Not Available" ;
VAL_ 2566771745 RemoteKeyFobFunctionRequested 0 "No Request" 1 "Door Unlock Request" 2 "Door Lock Request" 3 "Start Request" 4 "Stop Request" 5 "Front Closure Release Request" 6 "Rear Closure Release Request" 7 "Power Rear Closure Start Request" 8 "Power Rear Closure Stop Request" 9 "Fuel Operated Heater Request Off" 10 "Fuel Operated Heater Request On" 11 "Mirror Unfold Request" 12 "Mirror Fold Request" 13 "Window Open Request" 14 "Window Close Request" 15 "Power Top Open" 16 "Power Top Close" 17 "Power Top Pause" 18 "Power Top Stop" 19 "Panic Alarm" 20 "Locator Alarm" 21 "Reserved" 30 "Error" 31 "Not Available" ;
VAL_ 2566799393 RunningLight 0 "De-activated" 1 "Activated" 2 "Fault Detected" 3 "Not Available" ;
VAL_ 2566799393 AlternateBeamHeadLightData 0 "De-activated" 1 "Activated" 2 "Fault Detected" 3 "Not Available" ;
VAL_ 2566799393 LowBeamHeadLightData 0 "De-activated" 1 "Activated" 2 "Fault Detected" 3 "Not Available" ;
VAL_ 2566799393 HighBeamHeadLightData 0 "De-activated" 1 "Activated" 2 "Fault Detected" 3 "Not Available" ;
VAL_ 2566799393 TractorFrontFogLights 0 "De-activated" 1 "Activated" 2 "Fault Detected" 3 "Not Available" ;
VAL_ 2566799393 RotatingBeaconLight 0 "De-activated" 1 "Activated" 2 "Fault Detected" 3 "Not Available" ;
VAL_ 2566799393 RightTurnSignalLights 0 "De-activated" 1 "Activated" 2 "Fault Detected" 3 "Not Available" ;
VAL_ 2566799393 LeftTurnSignalLights 0 "De-activated" 1 "Activated" 2 "Fault Detected" 3 "Not Available" ;
VAL_ 2566799393 BackUpLightAndAlarmHorn 0 "De-activated" 1 "Activated" 2 "Fault Detected" 3 "Not Available" ;
VAL_ 2566799393 CenterStopLight 0 "De-activated" 1 "Activated" 2 "Fault Detected" 3 "Not Available" ;
VAL_ 2566799393 RightStopLight 0 "De-activated" 1 "Activated" 2 "Fault Detected" 3 "Not Available" ;
VAL_ 2566799393 LeftStopLight 0 "De-activated" 1 "Activated" 2 "Fault Detected" 3 "Not Available" ;
VAL_ 2566799393 ImplementClearanceLight 0 "De-activated" 1 "Activated" 2 "Fault Detected" 3 "Not Available" ;
VAL_ 2566799393 TractorClearanceLight 0 "De-activated" 1 "Activated" 2 "Fault Detected" 3 "Not Available" ;
VAL_ 2566799393 ImplementMarkerLight 0 "De-activated" 1 "Activated" 2 "Fault Detected" 3 "Not Available" ;
VAL_ 2566799393 TractorMarkerLight 0 "De-activated" 1 "Activated" 2 "Fault Detected" 3 "Not Available" ;
VAL_ 2566799393 RearFogLights 0 "De-activated" 1 "Activated" 2 "Fault Detected" 3 "Not Available" ;
VAL_ 2566799393 TractorUndersideMntdWorkLights 0 "De-activated" 1 "Activated" 2 "Fault Detected" 3 "Not Available" ;
VAL_ 2566799393 TractorRearLowMountedWorkLights 0 "De-activated" 1 "Activated" 2 "Fault Detected" 3 "Not Available" ;
VAL_ 2566799393 TractorRearHighMountedWorkLights 0 "De-activated" 1 "Activated" 2 "Fault Detected" 3 "Not Available" ;
VAL_ 2566799393 TractorSideLowMountedWorkLights 0 "De-activated" 1 "Activated" 2 "Fault Detected" 3 "Not Available" ;
VAL_ 2566799393 TractorSideHighMountedWorkLights 0 "De-activated" 1 "Activated" 2 "Fault Detected" 3 "Not Available" ;
VAL_ 2566799393 TractorFrontLowMountedWorkLights 0 "De-activated" 1 "Activated" 2 "Fault Detected" 3 "Not Available" ;
VAL_ 2566799393 TractorFrntHighMountedWorkLights 0 "De-activated" 1 "Activated" 2 "Fault Detected" 3 "Not Available" ;
VAL_ 2566799393 ImplementOEMOption2Light 0 "De-activated" 1 "Activated" 2 "Fault Detected" 3 "Not Available" ;
VAL_ 2566799393 ImplementOEMOption1Light 0 "De-activated" 1 "Activated" 2 "Fault Detected" 3 "Not Available" ;
VAL_ 2566799393 ImplementRightFacingWorkLight 0 "De-activated" 1 "Activated" 2 "Fault Detected" 3 "Not Available" ;
VAL_ 2566799393 ImplementLeftForwardWorkLight 0 "De-activated" 1 "Activated" 2 "Fault Detected" 3 "Not Available" ;
VAL_ 2566799393 ImplementRightForwardWorkLight 0 "De-activated" 1 "Activated" 2 "Fault Detected" 3 "Not Available" ;
VAL_ 2566799393 ImplementLeftFacingWorkLight 0 "De-activated" 1 "Activated" 2 "Fault Detected" 3 "Not Available" ;
VAL_ 2566799393 ImplementRearWorkLight 0 "De-activated" 1 "Activated" 2 "Fault Detected" 3 "Not Available" ;
VAL_ 2365473047 RunningLightCommand 0 "De-activate" 1 "Activate" 2 "Reserved" 3 "Don't Care" ;
VAL_ 2365473047 AlternateBeamHeadLightCommand 0 "De-activate" 1 "Activate" 2 "Reserved" 3 "Don't Care" ;
VAL_ 2365473047 LowBeamHeadLightCommand 0 "De-activate" 1 "Activate" 2 "Reserved" 3 "Don't Care" ;
VAL_ 2365473047 HighBeamHeadLightCommand 0 "De-activate" 1 "Activate" 2 "Reserved" 3 "Don't Care" ;
VAL_ 2365473047 TractorFrontFogLightsCommand 0 "De-activate" 1 "Activate" 2 "Reserved" 3 "Don't Care" ;
VAL_ 2365473047 RotatingBeaconLightCommand 0 "De-activate" 1 "Activate" 2 "Reserved" 3 "Don't Care" ;
VAL_ 2365473047 RightTurnSignalLightsCommand 0 "De-activate" 1 "Activate" 2 "Reserved" 3 "Don't Care" ;
VAL_ 2365473047 LeftTurnSignalLightsCommand 0 "De-activate" 1 "Activate" 2 "Reserved" 3 "Don't Care" ;
VAL_ 2365473047 BackUpLightAndAlarmHornCommand 0 "De-activate" 1 "Activate" 2 "Reserved" 3 "Don't Care" ;
VAL_ 2365473047 CenterStopLightCommand 0 "De-activate" 1 "Activate" 2 "Reserved" 3 "Don't Care" ;
VAL_ 2365473047 RightStopLightCommand 0 "De-activate" 1 "Activate" 2 "Reserved" 3 "Don't Care" ;
VAL_ 2365473047 LeftStopLightCommand 0 "De-activate" 1 "Activate" 2 "Reserved" 3 "Don't Care" ;
VAL_ 2365473047 ImplementClearanceLightCommand 0 "De-activate" 1 "Activate" 2 "Reserved" 3 "Don't Care" ;
VAL_ 2365473047 TractorClearanceLightCommand 0 "De-activate" 1 "Activate" 2 "Reserved" 3 "Don't Care" ;
VAL_ 2365473047 ImplementMarkerLightCommand 0 "De-activate" 1 "Activate" 2 "Reserved" 3 "Don't Care" ;
VAL_ 2365473047 TractorMarkerLightCommand 0 "De-activate" 1 "Activate" 2 "Reserved" 3 "Don't Care" ;
VAL_ 2365473047 RearFogLightCommand 0 "De-activate" 1 "Activate" 2 "Reserved" 3 "Don't Care" ;
VAL_ 2365473047 TractorUnderSdeMntdWorkLightsCmd 0 "De-activate" 1 "Activate" 2 "Reserved" 3 "Don't Care" ;
VAL_ 2365473047 TractorRearLowMntdWorkLightsCmd 0 "De-activate" 1 "Activate" 2 "Reserved" 3 "Don't Care" ;
VAL_ 2365473047 TractorRearHghMntdWorkLightsCmd 0 "De-activate" 1 "Activate" 2 "Reserved" 3 "Don't Care" ;
VAL_ 2365473047 TractorSideLowMntdWorkLightsCmd 0 "De-activate" 1 "Activate" 2 "Reserved" 3 "Don't Care" ;
VAL_ 2365473047 TractorSideHghMntdWorkLightsCmd 0 "De-activate" 1 "Activate" 2 "Reserved" 3 "Don't Care" ;
VAL_ 2365473047 TractorFrntLowMntdWorkLightsCmd 0 "De-activate" 1 "Activate" 2 "Reserved" 3 "Don't Care" ;
VAL_ 2365473047 TractorFrntHghMntdWorkLightsCmd 0 "De-activate" 1 "Activate" 2 "Reserved" 3 "Don't Care" ;
VAL_ 2365473047 ImplementOEMOption2LightCommand 0 "De-activate" 1 "Activate" 2 "Reserved" 3 "Don't Care" ;
VAL_ 2365473047 ImplementOEMOption1LightCommand 0 "De-activate" 1 "Activate" 2 "Reserved" 3 "Don't Care" ;
VAL_ 2365473047 ImplementRightFacingWorkLightCmd 0 "De-activate" 1 "Activate" 2 "Reserved" 3 "Don't Care" ;
VAL_ 2365473047 ImplementLeftForwardWorkLightCmd 0 "De-activate" 1 "Activate" 2 "Reserved" 3 "Don't Care" ;
VAL_ 2365473047 LightingDataRequestCommand 0 "Response not requested" 1 "Response requested" 2 "Reserved" 3 "Don't Care" ;
VAL_ 2365473047 ImplementRightFrwdWorkLightCmd 0 "De-activate" 1 "Activate" 2 "Reserved" 3 "Don't Care" ;
VAL_ 2365473047 ImplementLeftFacingWorkLightCmd 0 "De-activate" 1 "Activate" 2 "Reserved" 3 "Don't Care" ;
VAL_ 2365473047 ImplementRearWorkLightCommand 0 "De-activate" 1 "Activate" 2 "Reserved" 3 "Don't Care" ;
VAL_ 2566827553 AirCompressorStatus 0 "Compressor not active" 1 "Compressor active" 2 "Error indicator" 3 "Not available" ;
VAL_ 2566844705 TwoSpeedAxleSwitch 0 "Low speed range" 1 "High speed range" 2 "Error" 3 "Not available" ;
VAL_ 2566844705 ParkingBrakeSwitch 0 "Parking brake not set" 1 "Parking brake set" 2 "Error" 3 "Not available" ;
VAL_ 2566844705 CruiseControlPauseSwitch 0 "Off" 1 "On" 2 "Error Indicator" 3 "Take No Action" ;
VAL_ 2566844705 ParkBrakeReleaseInhibitRequest 0 "Park Brake Release Inhibit not requested" 1 "Park Brake Release Inhibit requested" 2 "SAE reserved" 3 "Unavailable" ;
VAL_ 2566844705 CruiseControlActive 0 "Cruise control switched off" 1 "Cruise control switched on" 2 "Error" 3 "Not available" ;
VAL_ 2566844705 CruiseControlEnableSwitch 0 "Cruise control disabled" 1 "Cruise control enabled" 2 "Error" 3 "Not available" ;
VAL_ 2566844705 BrakeSwitch 0 "Brake pedal released" 1 "Brake pedal depressed" 2 "Error" 3 "Not Available" ;
VAL_ 2566844705 ClutchSwitch 0 "Clutch pedal released" 1 "Clutch pedal depressed" 2 "Error" 3 "Not available" ;
VAL_ 2566844705 CruiseControlSetSwitch 0 "Cruise control activator not in the position 'set'" 1 "Cruise control activator in position 'set'" 2 "Error" 3 "Not available" ;
VAL_ 2566844705 CruiseControlCoastSwitch 0 "Cruise control activator not in the position 'coast'" 1 "Cruise control activator in position 'coast'" 2 "Error" 3 "Not available" ;
VAL_ 2566844705 CruiseControlResumeSwitch 0 "Cruise control activator not in the position 'resume'" 1 "Cruise control activator in position 'resume'" 2 "Error" 3 "Not available" ;
VAL_ 2566844705 CruiseControlAccelerateSwitch 0 "Cruise control activator not in the position 'accelerate'" 1 "Cruise control activator in position 'accelerate'" 2 "Error" 3 "Not available" ;
VAL_ 2566844705 PTOGovernorState 0 "Off/Disabled" 1 "Hold" 2 "Remote Hold" 3 "Standby" 4 "Remote Standby" 5 "Set" 6 "Decelerate/Coast" 7 "Resume" 8 "Accelerate" 9 "Accelerator Override" 10 "Preprogrammed set speed 1" 11 "Preprogrammed set speed 2" 12 "Preprogrammed set speed 3" 13 "Preprogrammed set speed 4" 14 "Preprogrammed set speed 5" 15 "Preprogrammed set speed 6" 16 "Preprogrammed set speed 7" 17 "Preprogrammed set speed 8" 18 "PTO set speed memory 1" 19 "PTO set speed memory 2" 20 "PTO set speed memory 3" 21 "Not defined" 31 "Not available" ;
VAL_ 2566844705 CruiseControlStates 0 "Off/Disabled" 1 "Hold" 2 "Accelerate" 3 "Decelerate" 4 "Resume" 5 "Set" 6 "Accelerator Override" 7 "Not available" ;
VAL_ 2566844705 EngineIdleIncrementSwitch 0 "Off" 1 "On" 2 "Error" 3 "Not available" ;
VAL_ 2566844705 EngineIdleDecrementSwitch 0 "Off" 1 "On" 2 "Error" 3 "Not available" ;
VAL_ 2566844705 EngineDiagnosticTestModeSwitch 0 "Off" 1 "On" 2 "Error" 3 "Not available" ;
VAL_ 2566844705 EngineShutdownOverrideSwitch 0 "Off" 1 "On" 2 "Error" 3 "Not available" ;
VAL_ 2364577313 HVES1HghVoltageBusPosContactStat 0 "Contactor Open" 1 "Contactor Closed" 2 "Error" 3 "Not Available" ;
VAL_ 2364577313 HVES1HghVoltageBusNegContactStat 0 "Contactor Open" 1 "Contactor Closed" 2 "Error" 3 "Not Available" ;
VAL_ 2364577313 HVES1HghVoltageBusDiscnnctFrwrng 0 "Disconnect not pending" 1 "Disconnect imminent due to battery pack voltage approaching minimum acceptable level" 2 "Disconnect imminent due to battery pack voltage approaching maximum acceptable level" 3 "Disconnect imminent due to module voltage approaching minimum acceptable level" 4 "Disconnect imminent due to module voltage approaching maximum acceptable level" 5 "Disconnect imminent due to cell voltage approaching minimum acceptable level" 6 "Disconnect imminent due to cell voltage approaching maximum acceptable level" 7 "Disconnect imminent due to battery pack current approaching maximum acceptable level" 8 "Reserved" 13 "Disconnect imminent" 14 "Error" 15 "Not Available" ;
VAL_ 2364577313 HVES1HghVltgBusPreChrgRelyStat 0 "Relay Open" 1 "Relay Closed" 2 "Error" 3 "Not Available" ;
VAL_ 2364577313 HVES1CenterOfPackContactorState 0 "Contactor Open" 1 "Contactor Closed" 2 "Error" 3 "Not Available" ;
VAL_ 2364577313 HVES1HiVltgBusActIsolatnTestStat 0 "No test requested / No test in process" 1 "Test requested but not yet in process" 2 "Test in process" 3 "Test complete - isolation acceptable" 4 "Test complete - isolation marginal" 5 "Test complete - isolation fault" 6 "Test is inhibited" 7 "Reserved" 14 "Error" 15 "Not available" ;
VAL_ 2364577313 HVES1HiVltgBusPassIsolatnTestSt 0 "No test requested / No test in process" 1 "Test requested but not yet in process" 2 "Test in process" 3 "Test complete - isolation acceptable" 4 "Test complete - isolation marginal" 5 "Test complete - isolation fault" 6 "Test is inhibited" 7 "Reserved" 14 "Error" 15 "Not available" ;
VAL_ 2364577313 HVES1HVILStatus 0 "HVIL Closed" 1 "HVIL Open" 2 "Error" 3 "Not Available" ;
VAL_ 2364577313 HVES1InertiaSwitchStatus 0 "No impact sensed" 1 "Impact sensed" 2 "Error" 3 "Not Available" ;
VAL_ 2364577313 HVES1CellBalanceStatus 0 "Cells are balanced" 1 "Cells are unbalanced" 2 "Error" 3 "Not Available" ;
VAL_ 2364577313 HVES1CellBalancingActive 0 "Cell balancing is not active" 1 "Cell balancing is active" 2 "Error" 3 "Not Available" ;
VAL_ 2364577313 HVES1InternalChargerStatus 0 "Charging off" 1 "Charging on" 2 "Error" 3 "Not Available" ;
VAL_ 2364577313 HVES1HghVoltageBusConnectnStatus 0 "Disconnected" 1 "Connected" 2 "Connection in Process" 3 "Disconnection in Process" 4 "Disconnected: Precharge Failed" 5 "Reserved" 14 "Error" 15 "Not Available" ;
VAL_ 2364577313 HVES1OperationalStatus 0 "Initialization in Process" 1 "Initialization Complete, awaiting Operation Consent" 2 "Operational" 3 "Normal Power-Down in Process" 4 "Emergency Power-Down In Process" 5 "Disabled by external command" 6 "Disabled by internal decision of HVES controller" 7 "Reserved" 14 "Error" 15 "Not Available" ;
VAL_ 2566900513 PCvi_en_PortAState 3 "Error" 2 "Charging" 1 "Plugged In" 0 "Unplugged" ;
VAL_ 2365479471 NominalLevelFrontAxle 0 "Level not specified" 1 "Normal Level 1" 2 "Normal Level 2" 3 "Normal Level 3" 4 "Preset Level" 5 "Customer Level" 6 "Upper Level" 7 "Lower Level" 8 "Level change stopped" 9 "Raising" 10 "Lowering" 11 "Reserved" 14 "Error" 15 "Not available" ;
VAL_ 2365479471 NominalLevelRearAxle 0 "Level not specified" 1 "Normal Level 1" 2 "Normal Level 2" 3 "Normal Level 3" 4 "Preset Level" 5 "Customer Level" 6 "Upper Level" 7 "Lower Level" 8 "Level change stopped" 9 "Raising" 10 "Lowering" 11 "Reserved" 14 "Error" 15 "Not available" ;
VAL_ 2365479471 BelowNominalLevelFrontAxle 0 "Not below" 1 "Below" 2 "Error" 3 "Not available" ;
VAL_ 2365479471 BelowNominalLevelRearAxle 0 "Not below" 1 "Below" 2 "Error" 3 "Not available" ;
VAL_ 2365479471 AboveNominalLevelFrontAxle 0 "Not above" 1 "Above" 2 "Error" 3 "Not available" ;
VAL_ 2365479471 AboveNominalLevelRearAxle 0 "Not above" 1 "Above" 2 "Error" 3 "Not available" ;
VAL_ 2365479471 LoweringControlModeFrontAxle 0 "Lowering not active" 1 "Lowering active" 2 "Error" 3 "Not available" ;
VAL_ 2365479471 LoweringControlModeRearAxle 0 "Lowering not active" 1 "Lowering active" 2 "Error" 3 "Not available" ;
VAL_ 2365479471 LiftingControlModeFrontAxle 0 "Lifting not active" 1 "Lifting active" 2 "Error" 3 "Not available" ;
VAL_ 2365479471 LiftingControlModeRearAxle 0 "Lifting not active" 1 "Lifting active" 2 "Error" 3 "Not available" ;
VAL_ 2365479471 KneelingInformation 15 "SNV" 14 "NotDef" 13 "NotDef" 12 "NotDef" 11 "NotDef" 10 "NotDef" 9 "NotDef" 8 "NotDef" 7 "NotDef" 6 "NotDef" 5 "NotDef" 4 "Aborted" 3 "Lifting" 2 "LevelReached" 1 "Lowering" 0 "NotActive" ;
VAL_ 2365479471 LevelControlMode 15 "SNV" 14 "NotDef" 13 "NotDef" 12 "NotDef" 11 "NotDef" 10 "NotDef" 9 "NotDef" 8 "Exhaustbellow" 7 "TracHelpreduce" 6 "OptTraction2" 5 "OptTraction1" 4 "PressRatio2" 3 "PressRatio1" 2 "LoadFixing" 1 "TracHelpIncrease" 0 "Normal" ;
VAL_ 2365479471 SecurityDevice 0 "not active" 1 "active" 2 "error" 3 "not available" ;
VAL_ 2365479471 VehicleMotionInhibit 0 "Vehicle may be moved" 1 "Vehicle motion is inhibited" 2 "Error" 3 "Not available" ;
VAL_ 2365479471 DoorRelease 3 "SNV" 2 "NotDef" 1 "DoorsMayBeOpend" 0 "DoorsMayNotBeOpend" ;
VAL_ 2365479471 LiftAxle1Position 0 "Lift axle position down / tag axle laden" 1 "Lift axle position up / tag axle unladen" 2 "Error" 3 "Not available" ;
VAL_ 2365479471 FrontAxleInBumperRange 0 "Actual level out of bumper range" 1 "Actual level within bumper range" 2 "Error" 3 "Not available" ;
VAL_ 2365479471 RearAxleInBumperRange 0 "Actual level out of bumper range" 1 "Actual level within bumper range" 2 "Error" 3 "Not available" ;
VAL_ 2365479471 LiftAxle2Position 0 "Lift axle position down / tag axle laden" 1 "Lift axle position up / tag axle unladen" 2 "Error" 3 "Not available" ;
VAL_ 2365479471 SuspensionRemoteControl1 0 "not active" 1 "active" 2 "error" 3 "not available" ;
VAL_ 2365479471 SuspensionRemoteControl2 0 "not active" 1 "active" 2 "error" 3 "not available" ;
VAL_ 2365479471 AllowLevelCtrlDuringBrkngStatus 0 "Deactivated" 1 "Activated" 2 "Reserved" 3 "Don't care/take no action" ;
VAL_ 2365479471 SpeedDependantLevelControlStatus 0 "Inactive" 1 "Active" 2 "Reserved" 3 "Don't care/take no action" ;
VAL_ 2365479471 SuspensionCtrlRefusalInformation 0 "Actual request not refused" 1 "Axle load limit reached  (load transfer)" 2 "Would exceed axle load limit (tag axle)" 3 "Bogie differential not locked" 4 "Above speed limit" 5 "Below speed limit" 6 "General reject" 7 "Requested level not available" 8 "Not defined" 14 "Error" 15 "Not available" ;
VAL_ 2365479471 MemoryLevel 0 "No memory level" 1 "Memory level 1 selected" 2 "Memory level 2 selected" 3 "Memory level 3 selected" 4 "Memory level 4 selected" 5 "Memory level 5 selected" 6 "reserved" 9 "Memory level  1 stored" 10 "Memory level  2 stored" 11 "Memory level  3 stored" 12 "Memory level  4 stored" 13 "Memory level  5 stored" 14 "Error indicator" 15 "not available" ;
VAL_ 2364607265 HvessThermalEventDetected 0 "No Thermal Event Detected" 1 "Thermal Event Detected" 2 "Error" 3 "Not avaliable" ;
VAL_ 2565866785 TransmissionSelectedGear 0 "Neutral" 251 "Park" ;
VAL_ 2565866785 TransmissionCurrentGear 0 "Neutral" 251 "Park" ;
VAL_ 2566719265 EngineProtectLampCommand 0 "Lamp Off" 1 "Lamp On" 2 "Reserved" 3 "Not available" ;
VAL_ 2566719265 EngineAmberWarningLampCommand 0 "Lamp Off" 1 "Lamp On" 2 "Reserved" 3 "Not available" ;
VAL_ 2566719265 EngineRedStopLampCommand 0 "Lamp Off" 1 "Lamp On" 2 "Reserved" 3 "Not available" ;
VAL_ 2566719265 OBDMalfunctionIndicatorLampCmd 0 "Lamp Off" 1 "Lamp On" 2 "Reserved" 3 "Not available" ;
VAL_ 2566719265 EngineBrakeActiveLampCommand 0 "Lamp Off" 1 "Lamp On" 2 "Reserved" 3 "Not available" ;
VAL_ 2566719265 ComPrsionBrkEnblSwIndictrLampCmd 0 "Lamp Off" 1 "Lamp On" 2 "Reserved" 3 "Not available" ;
VAL_ 2566719265 EngineOilPressureLowLampCommand 0 "Lamp Off" 1 "Lamp On" 2 "Reserved" 3 "Not available" ;
VAL_ 2566719265 EngCoolntTemperatureHighLampCmd 0 "Lamp Off" 1 "Lamp On" 2 "Reserved" 3 "Not available" ;
VAL_ 2566719265 EngineCoolantLevelLowLampCommand 0 "Lamp Off" 1 "Lamp On" 2 "Reserved" 3 "Not available" ;
VAL_ 2566719265 EngineIdleManagementActvLampCmd 0 "Lamp Off" 1 "Lamp On" 2 "Reserved" 3 "Not available" ;
VAL_ 2566719265 EngAirFilterRestrictionLampCmd 0 "Lamp Off" 1 "Lamp On" 2 "Reserved" 3 "Not available" ;
VAL_ 2566719265 EngFuelFilterRestrictedLampCmd 0 "Lamp Off" 1 "Lamp On" 2 "Reserved" 3 "Not available" ;
VAL_ 2566719265 EngCtrlModule1ReadyForUseLampCmd 0 "Lamp Off" 1 "Lamp On" 2 "Reserved" 3 "Not available" ;
VAL_ 2566719265 EngCtrlModule2ReadyForUseLampCmd 0 "Lamp Off" 1 "Lamp On" 2 "Reserved" 3 "Not available" ;
VAL_ 2566719265 EngCtrlModule3ReadyForUseLampCmd 0 "Lamp Off" 1 "Lamp On" 2 "Reserved" 3 "Not available" ;
VAL_ 2566719265 EngineSpeedHighLampCommand 0 "Lamp Off" 1 "Lamp On" 2 "Reserved" 3 "Not available" ;
VAL_ 2566719265 EngineSpeedVeryHighLampCommand 0 "Lamp Off" 1 "Lamp On" 2 "Reserved" 3 "Not available" ;
VAL_ 2566719265 VehicleAccltnRateLimitLampCmd 0 "Lamp Off" 1 "Lamp On" 2 "Reserved" 3 "Not available" ;
VAL_ 2566719265 EngIdlMangmntPendingEvntLampCmd 0 "Lamp Off" 1 "Lamp On" 2 "Reserved" 3 "Not available" ;
VAL_ 2566719265 EngStopStartAutoStopActvLampCmd 0 "Lamp Off" 1 "Lamp On" 2 "Reserved" 3 "Not available" ;
VAL_ 2566719265 EngStopStrtAutoStrtFailedLampCmd 0 "Lamp Off" 1 "Lamp On" 2 "Reserved" 3 "Not available" ;
VAL_ 2566719265 EngineStopStartEnabledLampCmd 0 "Lamp Off" 1 "Lamp On" 2 "Reserved" 3 "Not available" ;
VAL_ 2566719265 EngineOilTemperatureHighLampCmd 0 "Lamp Off" 1 "Lamp On" 2 "Reserved" 3 "Not available" ;
VAL_ 2566719265 EngineFuelTemperatureHighLampCmd 0 "Lamp Off" 1 "Lamp On" 2 "Reserved" 3 "Not available" ;
VAL_ 2566719265 EngIntercoolerTempHghLampCmd 0 "Lamp Off" 1 "Lamp On" 2 "Reserved" 3 "Not available" ;
VAL_ 2566719265 EngineAirShutoffLampCommand 0 "Lamp Off" 1 "Lamp On" 2 "Reserved" 3 "Not available" ;
VAL_ 2566749463 FMS1_Mux 0 "FMS1_Mux_0" 2 "FMS1_Mux_2" 4 "FMS1_Mux_4" ;
VAL_ 2566749463 Coolingairconditioning 0 "Off" 1 "Condition Red" 2 "Condition Yellow" 3 "Condition Info" 15 "Not Avaliable" ;
VAL_ 2566749463 Highbeammainbeam 0 "Off" 1 "Condition Red" 2 "Condition Yellow" 3 "Condition Info" 15 "Not Avaliable" ;
VAL_ 2566749463 Lowbeamdippedbeam 0 "Off" 1 "Condition Red" 2 "Condition Yellow" 3 "Condition Info" 15 "Not Avaliable" ;
VAL_ 2566749463 Turnsignals 0 "Off" 1 "Condition Red" 2 "Condition Yellow" 3 "Condition Info" 15 "Not Avaliable" ;
VAL_ 2566749463 Hazardwarning 0 "Off" 1 "Condition Red" 2 "Condition Yellow" 3 "Condition Info" 15 "Not Avaliable" ;
VAL_ 2566749463 Provisionforthehandicapped 0 "Off" 1 "Condition Red" 2 "Condition Yellow" 3 "Condition Info" 15 "Not Avaliable" ;
VAL_ 2566749463 ParkingBrake 0 "Off" 1 "Condition Red" 2 "Condition Yellow" 3 "Condition Info" 15 "Not Avaliable" ;
VAL_ 2566749463 Brakefailure 0 "Off" 1 "Condition Red" 2 "Condition Yellow" 3 "Condition Info" 15 "Not Avaliable" ;
VAL_ 2566749463 Hatchopen 0 "Off" 1 "Condition Red" 2 "Condition Yellow" 3 "Condition Info" 15 "Not Avaliable" ;
VAL_ 2566749463 Fuellevel 0 "Off" 1 "Condition Red" 2 "Condition Yellow" 3 "Condition Info" 15 "Not Avaliable" ;
VAL_ 2566749463 Enginecoolanttemperature 0 "Off" 1 "Condition Red" 2 "Condition Yellow" 3 "Condition Info" 15 "Not Avaliable" ;
VAL_ 2566749463 Batterychargingcondition 0 "Off" 1 "Condition Red" 2 "Condition Yellow" 3 "Condition Info" 15 "Not Avaliable" ;
VAL_ 2566749463 Engineoil 0 "Off" 1 "Condition Red" 2 "Condition Yellow" 3 "Condition Info" 15 "Not Avaliable" ;
VAL_ 2566749463 Positionlightssidelights 0 "Off" 1 "Condition Red" 2 "Condition Yellow" 3 "Condition Info" 15 "Not Avaliable" ;
VAL_ 2566749463 Frontfoglight 0 "Off" 1 "Condition Red" 2 "Condition Yellow" 3 "Condition Info" 15 "Not Avaliable" ;
VAL_ 2566749463 StopRequest 0 "Off" 1 "Condition Red" 2 "Condition Yellow" 3 "Condition Info" 15 "Not Avaliable" ;
VAL_ 2566749463 Electricmotorfailures 0 "Off" 1 "Condition Red" 2 "Condition Yellow" 3 "Condition Info" 15 "Not Avaliable" ;
VAL_ 2566749463 Batterypack 0 "Off" 1 "Condition Red" 2 "Condition Yellow" 3 "Condition Info" 15 "Not Avaliable" ;
VAL_ 2566749463 HVsystemcaution 0 "Off" 1 "Condition Red" 2 "Condition Yellow" 3 "Condition Info" 15 "Not Avaliable" ;
VAL_ 2566749463 Batterypacktemperature 0 "Off" 1 "Condition Red" 2 "Condition Yellow" 3 "Condition Info" 15 "Not Avaliable" ;
VAL_ 2566749463 Limitedperformanceelectricmtr 0 "Off" 1 "Condition Red" 2 "Condition Yellow" 3 "Condition Info" 15 "Not Avaliable" ;
VAL_ 2566749463 Batterypackcooling 0 "Off" 1 "Condition Red" 2 "Condition Yellow" 3 "Condition Info" 15 "Not Avaliable" ;
VAL_ 2364552743 HVES1DisChrgPowerLmtDTStateChrg 0 "No power limit for this reason" 1 "Power limited for this reason" 2 "Error" 3 "Not Available" ;
VAL_ 2364552743 HVES1DisChrgPwrLmtDTBattryTemp 0 "No power limit for this reason" 1 "Power limited for this reason" 2 "Error" 3 "Not Available" ;
VAL_ 2364552743 HVES1DisChrgPwrLmtDTBattDiagCond 0 "No power limit for this reason" 1 "Power limited for this reason" 2 "Error" 3 "Not Available" ;
VAL_ 2364552743 HVES1DisChrgPwrLmtDTBattCellVltg 0 "No power limit for this reason" 1 "Power limited for this reason" 2 "Error" 3 "Not Available" ;
VAL_ 2364552743 HVES1DisChrgPowerLmtDTBattryCurr 0 "No power limit for this reason" 1 "Power limited for this reason" 2 "Error" 3 "Not Available" ;
VAL_ 2364552743 HVES1DisChrgPwrLmtDTUndefndCause 0 "No power limit for this reason" 1 "Power limited for this reason" 2 "Error" 3 "Not Available" ;
VAL_ 2364552743 HVES1ChrgPowerLimitDTStateChrg 0 "No power limit for this reason" 1 "Power limited for this reason" 2 "Error" 3 "Not Available" ;
VAL_ 2364552743 HVES1ChrgPwrLmtDTBattryTemp 0 "No power limit for this reason" 1 "Power limited for this reason" 2 "Error" 3 "Not Available" ;
VAL_ 2364552743 HVES1ChrgPwrLmtDTBattDiagCondtn 0 "No power limit for this reason" 1 "Power limited for this reason" 2 "Error" 3 "Not Available" ;
VAL_ 2364552743 HVES1ChrgPwrLmtDTBattryCellVltg 0 "No power limit for this reason" 1 "Power limited for this reason" 2 "Error" 3 "Not Available" ;
VAL_ 2364552743 HVES1ChrgPowerLimitDTBattryCurr 0 "No power limit for this reason" 1 "Power limited for this reason" 2 "Error" 3 "Not Available" ;
VAL_ 2364552743 HVES1ChrgPwrLmtDTUndefinedCause 0 "No power limit for this reason" 1 "Power limited for this reason" 2 "Error" 3 "Not Available" ;
VAL_ 2364606759 HVES1ThermalMangmntSystemHtrStat 0 "Heater Off" 1 "Heater On" 2 "Error" 3 "Not Available" ;
VAL_ 2364606759 HVESSThermalMangmntSysHVILStat 0 "HVIL Closed" 1 "HVIL Open" 2 "Error" 3 "Not Available" ;
VAL_ 2364606759 HVES1ThermalManagementSystemMode 0 "Off" 1 "Circulating" 2 "Cooling" 3 "Heating" 4 "Drying" 5 "Maintaining" 6 "Reserved" 14 "Faulted" 15 "Not Available" ;
VAL_ 2364606759 HVESSThermalMangmntSysCoolntLvl 0 "Coolant Level is not sufficient" 1 "Coolant Level is sufficient" 2 "Error" 3 "Not Available" ;
VAL_ 2566766631 TypeOfPassengerCount 0 "absolute passenger count" 1 "boarding passenger" 2 "exiting passenger" 3 "boarding passenger (second passenger stream)" 4 "exiting passenger (second passenger stream)" 5 "reserved for future assignment" 251 "reserved" 254 "error indicator" 255 "not available" ;
VAL_ 2566766631 SilentAlarmStatus 0 "Off" 1 "On" 2 "Error condition" 3 "Not available" ;
VAL_ 2566766631 VehicleUseStatus 0 "Normal use" 1 "Unauthorized use" 2 "Error condition" 3 "Not available" ;
VAL_ 2566766631 TransitRunStatus 0 "Off" 1 "On" 2 "Error condition" 3 "Not available" ;
VAL_ 2566834699 ProtectLamp 0 "Lamp Off" 1 "Lamp On" 2 "Reserved" 3 "Not available" ;
VAL_ 2566834699 AmberWarningLamp 0 "Lamp Off" 1 "Lamp On" 2 "Reserved" 3 "Not available" ;
VAL_ 2566834699 RedStopLamp 0 "Lamp Off" 1 "Lamp On" 2 "Reserved" 3 "Not available" ;
VAL_ 2566834699 MalfunctionIndicatorLamp 0 "Lamp Off" 1 "Lamp On" 2 "Short MIL for WWH OBD" 3 "Not available" ;
VAL_ 2566834699 FlashProtectLamp 0 "Slow Flash (1 Hz, 50 % duty cycle)" 1 "Fast Flash (2 Hz or faster, 50% duty cycle)" 2 "Reserved" 3 "Unavailable / Do Not Flash" ;
VAL_ 2566834699 FlashAmberWarningLamp 0 "Slow Flash (1 Hz, 50 % duty cycle)" 1 "Fast Flash (2 Hz or faster, 50% duty cycle)" 2 "Reserved" 3 "Unavailable / Do Not Flash" ;
VAL_ 2566834699 FlashRedStopLamp 0 "Slow Flash (1 Hz, 50 % duty cycle)" 1 "Fast Flash (2 Hz or faster, 50% duty cycle)" 2 "Reserved" 3 "Unavailable / Do Not Flash" ;
VAL_ 2566834699 FlashMalfunctionIndicatorLamp 0 "Slow Flash (1 Hz, 50 % duty cycle)" 1 "Fast Flash (2 Hz or faster, 50% duty cycle)" 2 "Class C DTC" 3 "Unavailable / Do Not Flash" ;
VAL_ 2566834699 SPNConversionMethod 0 "Convert SPN per Version 4" 1 "Convert SPN per Version 1, 2 or 3" ;
VAL_ 2566834699 SPNConversionMethod2 0 "Convert SPN per Version 4" 1 "Convert SPN per Version 1, 2 or 3" ;
VAL_ 2566834699 SPNConversionMethod3 0 "Convert SPN per Version 4" 1 "Convert SPN per Version 1, 2 or 3" ;
VAL_ 2566834699 SPNConversionMethod4 0 "Convert SPN per Version 4" 1 "Convert SPN per Version 1, 2 or 3" ;
VAL_ 2566834699 SPNConversionMethod5 0 "Convert SPN per Version 4" 1 "Convert SPN per Version 1, 2 or 3" ;
VAL_ 2566834699 SPNConversionMethod6 0 "Convert SPN per Version 4" 1 "Convert SPN per Version 1, 2 or 3" ;
VAL_ 2566834699 SPNConversionMethod7 0 "Convert SPN per Version 4" 1 "Convert SPN per Version 1, 2 or 3" ;
VAL_ 2566834699 SPNConversionMethod8 0 "Convert SPN per Version 4" 1 "Convert SPN per Version 1, 2 or 3" ;
VAL_ 2566834699 SPNConversionMethod9 0 "Convert SPN per Version 4" 1 "Convert SPN per Version 1, 2 or 3" ;
VAL_ 2566834699 SPNConversionMethod10 0 "Convert SPN per Version 4" 1 "Convert SPN per Version 1, 2 or 3" ;
VAL_ 2566834699 SPNConversionMethod11 0 "Convert SPN per Version 4" 1 "Convert SPN per Version 1, 2 or 3" ;
VAL_ 2566834699 SPNConversionMethod12 0 "Convert SPN per Version 4" 1 "Convert SPN per Version 1, 2 or 3" ;
VAL_ 2566834735 ProtectLamp 0 "Lamp Off" 1 "Lamp On" 2 "Reserved" 3 "Not available" ;
VAL_ 2566834735 AmberWarningLamp 0 "Lamp Off" 1 "Lamp On" 2 "Reserved" 3 "Not available" ;
VAL_ 2566834735 RedStopLamp 0 "Lamp Off" 1 "Lamp On" 2 "Reserved" 3 "Not available" ;
VAL_ 2566834735 MalfunctionIndicatorLamp 0 "Lamp Off" 1 "Lamp On" 2 "Short MIL for WWH OBD" 3 "Not available" ;
VAL_ 2566834735 FlashProtectLamp 0 "Slow Flash (1 Hz, 50 % duty cycle)" 1 "Fast Flash (2 Hz or faster, 50% duty cycle)" 2 "Reserved" 3 "Unavailable / Do Not Flash" ;
VAL_ 2566834735 FlashAmberWarningLamp 0 "Slow Flash (1 Hz, 50 % duty cycle)" 1 "Fast Flash (2 Hz or faster, 50% duty cycle)" 2 "Reserved" 3 "Unavailable / Do Not Flash" ;
VAL_ 2566834735 FlashRedStopLamp 0 "Slow Flash (1 Hz, 50 % duty cycle)" 1 "Fast Flash (2 Hz or faster, 50% duty cycle)" 2 "Reserved" 3 "Unavailable / Do Not Flash" ;
VAL_ 2566834735 FlashMalfunctionIndicatorLamp 0 "Slow Flash (1 Hz, 50 % duty cycle)" 1 "Fast Flash (2 Hz or faster, 50% duty cycle)" 2 "Class C DTC" 3 "Unavailable / Do Not Flash" ;
VAL_ 2566834735 SPNConversionMethod 0 "Convert SPN per Version 4" 1 "Convert SPN per Version 1, 2 or 3" ;
VAL_ 2566834735 SPNConversionMethod2 0 "Convert SPN per Version 4" 1 "Convert SPN per Version 1, 2 or 3" ;
VAL_ 2566834735 SPNConversionMethod3 0 "Convert SPN per Version 4" 1 "Convert SPN per Version 1, 2 or 3" ;
VAL_ 2566834735 SPNConversionMethod4 0 "Convert SPN per Version 4" 1 "Convert SPN per Version 1, 2 or 3" ;
VAL_ 2566834735 SPNConversionMethod5 0 "Convert SPN per Version 4" 1 "Convert SPN per Version 1, 2 or 3" ;
VAL_ 2566834735 SPNConversionMethod6 0 "Convert SPN per Version 4" 1 "Convert SPN per Version 1, 2 or 3" ;
VAL_ 2566834735 SPNConversionMethod7 0 "Convert SPN per Version 4" 1 "Convert SPN per Version 1, 2 or 3" ;
VAL_ 2566834735 SPNConversionMethod8 0 "Convert SPN per Version 4" 1 "Convert SPN per Version 1, 2 or 3" ;
VAL_ 2566834735 SPNConversionMethod9 0 "Convert SPN per Version 4" 1 "Convert SPN per Version 1, 2 or 3" ;
VAL_ 2566834735 SPNConversionMethod10 0 "Convert SPN per Version 4" 1 "Convert SPN per Version 1, 2 or 3" ;
VAL_ 2566834735 SPNConversionMethod11 0 "Convert SPN per Version 4" 1 "Convert SPN per Version 1, 2 or 3" ;
VAL_ 2566834735 SPNConversionMethod12 0 "Convert SPN per Version 4" 1 "Convert SPN per Version 1, 2 or 3" ;
VAL_ 2566834778 ProtectLamp 0 "Lamp Off" 1 "Lamp On" 2 "Reserved" 3 "Not available" ;
VAL_ 2566834778 AmberWarningLamp 0 "Lamp Off" 1 "Lamp On" 2 "Reserved" 3 "Not available" ;
VAL_ 2566834778 RedStopLamp 0 "Lamp Off" 1 "Lamp On" 2 "Reserved" 3 "Not available" ;
VAL_ 2566834778 MalfunctionIndicatorLamp 0 "Lamp Off" 1 "Lamp On" 2 "Short MIL for WWH OBD" 3 "Not available" ;
VAL_ 2566834778 FlashProtectLamp 0 "Slow Flash (1 Hz, 50 % duty cycle)" 1 "Fast Flash (2 Hz or faster, 50% duty cycle)" 2 "Reserved" 3 "Unavailable / Do Not Flash" ;
VAL_ 2566834778 FlashAmberWarningLamp 0 "Slow Flash (1 Hz, 50 % duty cycle)" 1 "Fast Flash (2 Hz or faster, 50% duty cycle)" 2 "Reserved" 3 "Unavailable / Do Not Flash" ;
VAL_ 2566834778 FlashRedStopLamp 0 "Slow Flash (1 Hz, 50 % duty cycle)" 1 "Fast Flash (2 Hz or faster, 50% duty cycle)" 2 "Reserved" 3 "Unavailable / Do Not Flash" ;
VAL_ 2566834778 FlashMalfunctionIndicatorLamp 0 "Slow Flash (1 Hz, 50 % duty cycle)" 1 "Fast Flash (2 Hz or faster, 50% duty cycle)" 2 "Class C DTC" 3 "Unavailable / Do Not Flash" ;
VAL_ 2566834778 SPNConversionMethod 0 "Convert SPN per Version 4" 1 "Convert SPN per Version 1, 2 or 3" ;
VAL_ 2566834778 SPNConversionMethod2 0 "Convert SPN per Version 4" 1 "Convert SPN per Version 1, 2 or 3" ;
VAL_ 2566834778 SPNConversionMethod3 0 "Convert SPN per Version 4" 1 "Convert SPN per Version 1, 2 or 3" ;
VAL_ 2566834778 SPNConversionMethod4 0 "Convert SPN per Version 4" 1 "Convert SPN per Version 1, 2 or 3" ;
VAL_ 2566834778 SPNConversionMethod5 0 "Convert SPN per Version 4" 1 "Convert SPN per Version 1, 2 or 3" ;
VAL_ 2566834778 SPNConversionMethod6 0 "Convert SPN per Version 4" 1 "Convert SPN per Version 1, 2 or 3" ;
VAL_ 2566834778 SPNConversionMethod7 0 "Convert SPN per Version 4" 1 "Convert SPN per Version 1, 2 or 3" ;
VAL_ 2566834778 SPNConversionMethod8 0 "Convert SPN per Version 4" 1 "Convert SPN per Version 1, 2 or 3" ;
VAL_ 2566834778 SPNConversionMethod9 0 "Convert SPN per Version 4" 1 "Convert SPN per Version 1, 2 or 3" ;
VAL_ 2566834778 SPNConversionMethod10 0 "Convert SPN per Version 4" 1 "Convert SPN per Version 1, 2 or 3" ;
VAL_ 2566834778 SPNConversionMethod11 0 "Convert SPN per Version 4" 1 "Convert SPN per Version 1, 2 or 3" ;
VAL_ 2566834778 SPNConversionMethod12 0 "Convert SPN per Version 4" 1 "Convert SPN per Version 1, 2 or 3" ;
